VERSION ""

NS_ :

BS_:

BU_: WPC2 RLPSU DPSU APSU PSB SHVU_RR vHS_B2 FCS EMCU SLB ARS RCM CGW_CCU vDummy_HS_B ATS RLHV SGU PFSU ALBCU DSAU SWRC SHVU_FR RCS RRPSU BLTN_CAM SCM DLBCU OHCL RWPC RRHV WPC HOD ASAU

BO_ 273 ARS_04_00ms: 8 ARS
 SG_ ARS_RrCurtainBtn : 0|2@1+ (1,0) [0|0] "" Vector__XXX

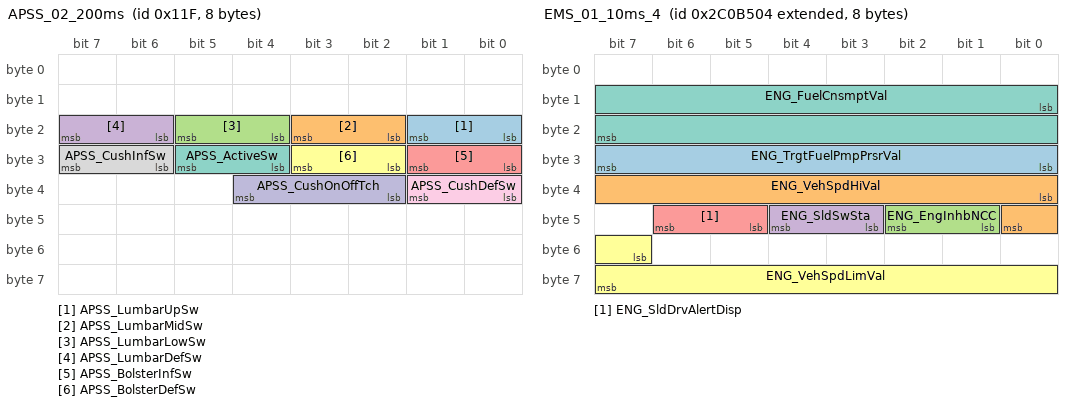
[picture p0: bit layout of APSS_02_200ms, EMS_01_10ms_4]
BO_ 287 APSS_02_200ms: 8 APSU
 SG_ APSS_LumbarUpSw : 16|2@1+ (1,0) [0|0] ""  ALBCU,CGW_CCU
 SG_ APSS_LumbarMidSw : 18|2@1+ (1,0) [0|0] ""  ALBCU,CGW_CCU
 SG_ APSS_LumbarLowSw : 20|2@1+ (1,0) [0|0] ""  ALBCU,CGW_CCU
 SG_ APSS_LumbarDefSw : 22|2@1+ (1,0) [0|0] ""  ALBCU,CGW_CCU
 SG_ APSS_BolsterInfSw : 24|2@1+ (1,0) [0|0] ""  ALBCU,CGW_CCU
 SG_ APSS_BolsterDefSw : 26|2@1+ (1,0) [0|0] ""  ALBCU,CGW_CCU
 SG_ APSS_ActiveSw : 28|2@1+ (1,0) [0|0] ""  ALBCU
 SG_ APSS_CushInfSw : 30|2@1+ (1,0) [0|0] ""  ALBCU
 SG_ APSS_CushDefSw : 32|2@1+ (1,0) [0|0] ""  ALBCU
 SG_ APSS_CushOnOffTch : 34|3@1+ (1,0) [0|0] ""  ALBCU

BO_ 2193667332 EMS_01_10ms_4: 8 CGW_CCU
 SG_ ENG_TrgtFuelPmpPrsrVal : 24|8@1+ (3.137254902,0) [0|0] "kPa" Vector__XXX
 SG_ ENG_VehSpdHiVal : 32|9@1+ (1,0) [0|0] "km/h" Vector__XXX
 SG_ ENG_EngInhbNCC : 41|2@1+ (1,0) [0|0] "" Vector__XXX
 SG_ ENG_SldSwSta : 43|2@1+ (1,0) [0|0] "" Vector__XXX
 SG_ ENG_SldDrvAlertDisp : 45|2@1+ (1,0) [0|0] "" Vector__XXX
 SG_ ENG_VehSpdLimVal : 55|9@1+ (1,0) [0|0] "km/h" Vector__XXX
 SG_ ENG_FuelCnsmptVal : 8|16@1+ (0.128,0) [0|0] "ul" Vector__XXX

BO_ 2193667331 EMS_01_10ms_3: 8 CGW_CCU
 SG_ ENG_TrgtIdleRpmVal : 0|8@1+ (10,0) [0|0] "rpm" Vector__XXX
 SG_ ENG_GearShftDnDis : 10|2@1+ (1,0) [0|0] "" Vector__XXX
 SG_ ENG_DsrGearPosDis : 12|4@1+ (1,0) [0|0] "" Vector__XXX
 SG_ ENG_SldFuncSta : 16|2@1+ (1,0) [0|0] "" Vector__XXX
 SG_ ENG_SldActnSta : 18|2@1+ (1,0) [0|0] "" Vector__XXX
 SG_ ENG_FuelTnkPrsrSta : 20|2@1+ (1,0) [0|0] "" Vector__XXX
 SG_ ENG_IsgBzrReq : 22|2@1+ (1,0) [0|0] "" Vector__XXX
 SG_ ENG_IsgFuelCnsmptDis : 24|2@1+ (1,0) [0|0] "" Vector__XXX
 SG_ ENG_FuelCapOpnSta : 26|2@1+ (1,0) [0|0] "" Vector__XXX
 SG_ ENG_EcoDrvActvSta : 28|2@1+ (1,0) [0|0] "" Vector__XXX
 SG_ ENG_EngRunSta : 30|2@1+ (1,0) [0|0] "" Vector__XXX
 SG_ ENG_Isg2Sta : 32|2@1+ (2,0) [0|0] "" Vector__XXX
 SG_ ENG_IgnOnSta : 34|2@1+ (1,0) [0|0] "" Vector__XXX
 SG_ ENG_Ack4TcsSta : 36|2@1+ (1,0) [0|0] "" Vector__XXX
 SG_ ENG_FuelCutOffSta : 38|2@1+ (1,0) [0|0] "" Vector__XXX
 SG_ ENG_CrctTqSta : 40|2@1+ (1,0) [0|0] "" Vector__XXX
 SG_ ENG_AirCompRlySta : 42|2@1+ (1,0) [0|0] "" Vector__XXX
 SG_ ENG_LnchCntrlSta : 45|3@1+ (1,0) [0|0] "" Vector__XXX
 SG_ ENG_EngSpdVal : 48|16@1+ (0.25,0) [0|0] "rpm"  EMCU
 SG_ ENG_GearShftUpDis : 8|2@1+ (1,0) [0|0] "" Vector__XXX

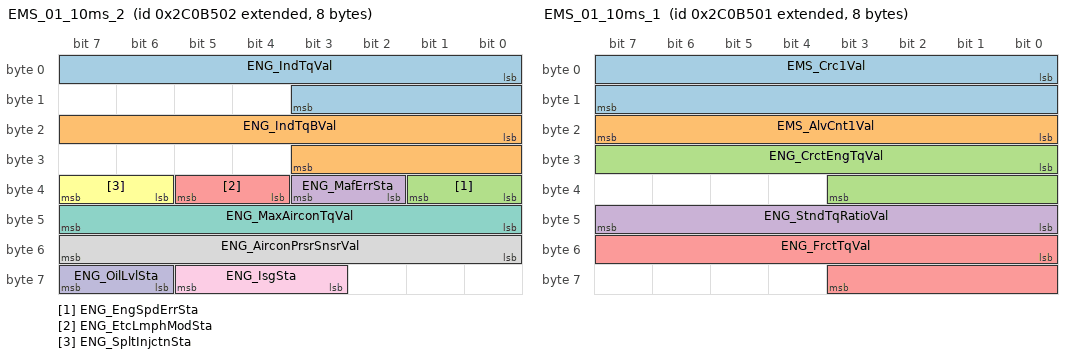
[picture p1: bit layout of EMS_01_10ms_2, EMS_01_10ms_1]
BO_ 2193667330 EMS_01_10ms_2: 8 CGW_CCU
 SG_ ENG_IndTqVal : 0|12@1- (1,0) [0|0] "Nm" Vector__XXX
 SG_ ENG_IndTqBVal : 16|12@1- (1,0) [0|0] "Nm" Vector__XXX
 SG_ ENG_EngSpdErrSta : 32|2@1+ (1,0) [0|0] "" Vector__XXX
 SG_ ENG_MafErrSta : 34|2@1+ (1,0) [0|0] "" Vector__XXX
 SG_ ENG_EtcLmphModSta : 36|2@1+ (1,0) [0|0] "" Vector__XXX
 SG_ ENG_SpltInjctnSta : 38|2@1+ (1,0) [0|0] "" Vector__XXX
 SG_ ENG_MaxAirconTqVal : 40|8@1+ (0.2,0) [0|0] "Nm" Vector__XXX
 SG_ ENG_AirconPrsrSnsrVal : 48|8@1+ (125,0) [0|0] "hPa" Vector__XXX
 SG_ ENG_IsgSta : 59|3@1+ (1,0) [0|0] ""  APSU,RLHV,RRHV,SHVU_FR,SHVU_RR,DPSU,RRPSU,RLPSU,EMCU
 SG_ ENG_OilLvlSta : 62|2@1+ (1,0) [0|0] "" Vector__XXX

BO_ 2193667329 EMS_01_10ms_1: 8 CGW_CCU
 SG_ EMS_Crc1Val : 0|16@1+ (1,0) [0|0] "" Vector__XXX
 SG_ EMS_AlvCnt1Val : 16|8@1+ (1,0) [0|0] "" Vector__XXX
 SG_ ENG_CrctEngTqVal : 24|12@1- (1,0) [0|0] "Nm" Vector__XXX
 SG_ ENG_StndTqRatioVal : 40|8@1+ (0.0078,0) [0|0] "" Vector__XXX
 SG_ ENG_FrctTqVal : 48|12@1- (1,0) [0|0] "Nm" Vector__XXX

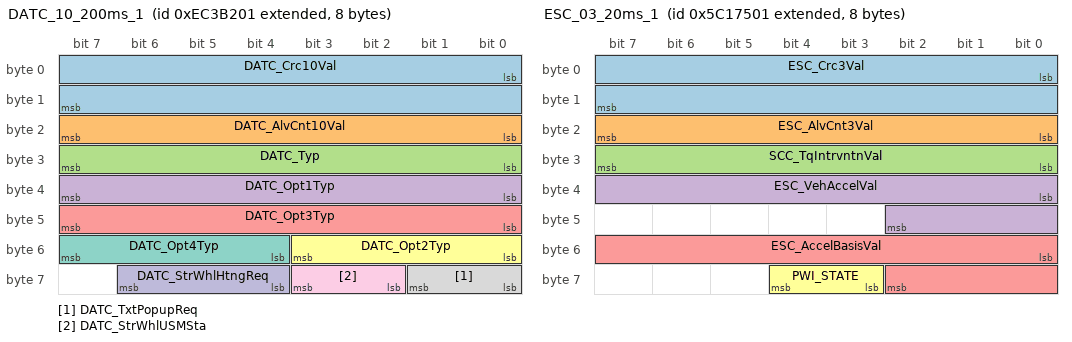
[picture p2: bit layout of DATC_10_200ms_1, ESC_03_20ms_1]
BO_ 2395189761 DATC_10_200ms_1: 8 CGW_CCU
 SG_ DATC_Crc10Val : 0|16@1+ (1,0) [0|0] "" Vector__XXX
 SG_ DATC_AlvCnt10Val : 16|8@1+ (1,0) [0|0] "" Vector__XXX
 SG_ DATC_Typ : 24|8@1+ (1,0) [0|0] ""  RLHV,RRHV,SHVU_FR,SHVU_RR,ATS
 SG_ DATC_Opt1Typ : 32|8@1+ (1,0) [0|0] ""  ATS
 SG_ DATC_Opt3Typ : 40|8@1+ (1,0) [0|0] ""  ATS
 SG_ DATC_Opt2Typ : 48|4@1+ (1,0) [0|0] ""  ATS
 SG_ DATC_Opt4Typ : 52|4@1+ (1,0) [0|0] ""  ATS
 SG_ DATC_TxtPopupReq : 56|2@1+ (1,0) [0|0] "" Vector__XXX
 SG_ DATC_StrWhlUSMSta : 58|2@1+ (1,0) [0|0] ""  APSU
 SG_ DATC_StrWhlHtngReq : 60|3@1+ (1,0) [0|0] "" Vector__XXX

BO_ 2244048129 ESC_03_20ms_1: 8 CGW_CCU
 SG_ ESC_Crc3Val : 0|16@1+ (1,0) [0|0] "" Vector__XXX
 SG_ ESC_AlvCnt3Val : 16|8@1+ (1,0) [0|0] "" Vector__XXX
 SG_ SCC_TqIntrvntnVal : 24|8@1+ (0.390625,0) [0|0] "%" Vector__XXX
 SG_ ESC_VehAccelVal : 32|11@1+ (0.01,-10.23) [0|0] "m/s^2" Vector__XXX
 SG_ ESC_AccelBasisVal : 48|11@1+ (0.01,-10.23) [0|0] "m/s^2" Vector__XXX
 SG_ PWI_STATE : 59|2@1+ (1,0) [0|0] "" Vector__XXX

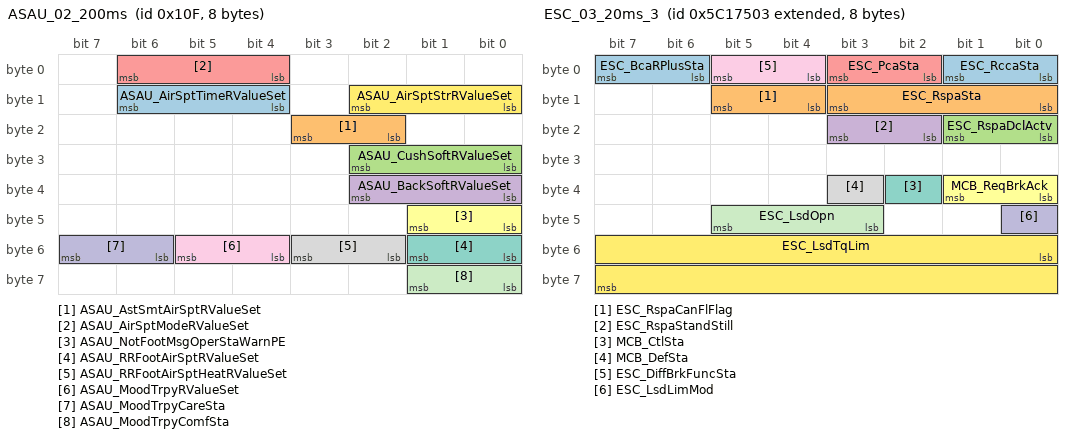
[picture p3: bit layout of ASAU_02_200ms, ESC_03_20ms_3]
BO_ 271 ASAU_02_200ms: 8 ASAU
 SG_ ASAU_AirSptTimeRValueSet : 12|3@1+ (1,0) [0|0] ""  CGW_CCU
 SG_ ASAU_AstSmtAirSptRValueSet : 18|2@1+ (1,0) [0|0] ""  CGW_CCU
 SG_ ASAU_CushSoftRValueSet : 24|3@1+ (1,0) [0|0] ""  CGW_CCU
 SG_ ASAU_BackSoftRValueSet : 32|3@1+ (1,0) [0|0] "" Vector__XXX
 SG_ ASAU_AirSptModeRValueSet : 4|3@1+ (1,0) [0|0] ""  CGW_CCU
 SG_ ASAU_NotFootMsgOperStaWarnPE : 40|2@1+ (1,0) [0|0] ""  ATS
 SG_ ASAU_RRFootAirSptRValueSet : 48|2@1+ (1,0) [0|0] ""  ATS
 SG_ ASAU_RRFootAirSptHeatRValueSet : 50|2@1+ (1,0) [0|0] ""  ATS
 SG_ ASAU_MoodTrpyRValueSet : 52|2@1+ (1,0) [0|0] ""  CGW_CCU
 SG_ ASAU_MoodTrpyCareSta : 54|2@1+ (1,0) [0|0] ""  CGW_CCU
 SG_ ASAU_MoodTrpyComfSta : 56|2@1+ (1,0) [0|0] ""  CGW_CCU
 SG_ ASAU_AirSptStrRValueSet : 8|3@1+ (1,0) [0|0] ""  CGW_CCU

BO_ 2244048131 ESC_03_20ms_3: 8 CGW_CCU
 SG_ ESC_RccaSta : 0|2@1+ (1,0) [0|0] "" Vector__XXX
 SG_ ESC_RspaCanFlFlag : 12|2@1+ (1,0) [0|0] "" Vector__XXX
 SG_ ESC_RspaDclActv : 16|2@1+ (1,0) [0|0] "" Vector__XXX
 SG_ ESC_RspaStandStill : 18|2@1+ (1,0) [0|0] "" Vector__XXX
 SG_ ESC_PcaSta : 2|2@1+ (1,0) [0|0] "" Vector__XXX
 SG_ MCB_ReqBrkAck : 32|2@1+ (1,0) [0|0] "" Vector__XXX
 SG_ MCB_CtlSta : 34|1@1+ (1,0) [0|0] "" Vector__XXX
 SG_ MCB_DefSta : 35|1@1+ (1,0) [0|0] "" Vector__XXX
 SG_ ESC_DiffBrkFuncSta : 4|2@1+ (1,0) [0|0] "" Vector__XXX
 SG_ ESC_LsdLimMod : 40|1@1+ (1,0) [0|0] "" Vector__XXX
 SG_ ESC_LsdOpn : 43|3@1+ (1,0) [0|0] "" Vector__XXX
 SG_ ESC_LsdTqLim : 48|16@1+ (1,0) [0|0] "Nm" Vector__XXX
 SG_ ESC_BcaRPlusSta : 6|2@1+ (1,0) [0|0] "" Vector__XXX
 SG_ ESC_RspaSta : 8|4@1+ (1,0) [0|0] "" Vector__XXX

BO_ 2244048130 ESC_03_20ms_2: 8 CGW_CCU
 SG_ SCC_OptTyp : 0|2@1+ (1,0) [0|0] "" Vector__XXX
 SG_ ESC_BrkLtReq : 10|2@1+ (1,0) [0|0] "" Vector__XXX
 SG_ ESC_DclEnblReq : 12|2@1+ (1,0) [0|0] "" Vector__XXX
 SG_ ESC_DrvOvrdSta : 16|2@1+ (1,0) [0|0] "" Vector__XXX
 SG_ ESC_DrvBrkSta : 18|2@1+ (1,0) [0|0] "" Vector__XXX
 SG_ SCC_EnblReq : 2|2@1+ (1,0) [0|0] "" Vector__XXX
 SG_ ESC_DrvBrkActvSta : 20|2@1+ (1,0) [0|0] "" Vector__XXX
 SG_ ESC_PrkBrkActvSta : 22|2@1+ (1,0) [0|0] "" Vector__XXX
 SG_ ESC_HDP_FltMonSta : 24|3@1+ (1,0) [0|0] ""  PSB
 SG_ ESC_HDPSpprtSWVer : 27|5@1+ (1,0) [0|0] "" Vector__XXX
 SG_ FCA_EquipSta : 32|2@1+ (1,0) [0|0] "" Vector__XXX
 SG_ FCA_AvlblSta : 34|2@1+ (1,0) [0|0] "" Vector__XXX
 SG_ ESC_FCA_ActvSta : 36|2@1+ (1,0) [0|0] "" Vector__XXX
 SG_ ESC_DBS_ActvSta : 38|2@1+ (1,0) [0|0] "" Vector__XXX
 SG_ SCC_TqReq : 4|2@1+ (1,0) [0|0] "" Vector__XXX
 SG_ ESC_HDP_EgSta : 40|3@1+ (1,0) [0|0] ""  PSB
 SG_ ESC_HDP_EnblReq : 43|3@1+ (1,0) [0|0] "" Vector__XXX
 SG_ CSC_Sta : 48|2@1+ (1,0) [0|0] "" Vector__XXX
 SG_ CSC_WrngSta : 50|2@1+ (1,0) [0|0] "" Vector__XXX
 SG_ ESC_BrkdFltStndstill : 56|2@1+ (1,0) [0|0] "" Vector__XXX
 SG_ SCC_ReqLimSta : 6|2@1+ (1,0) [0|0] "" Vector__XXX
 SG_ ESC_StdStillVal : 8|2@1+ (1,0) [0|0] "" Vector__XXX

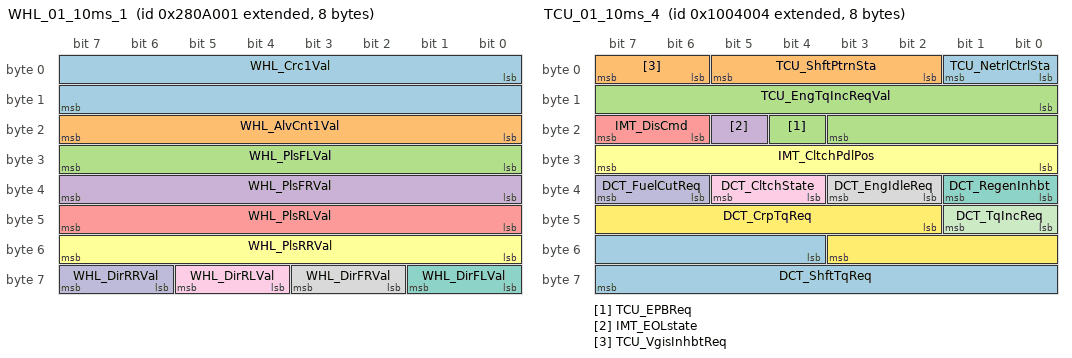
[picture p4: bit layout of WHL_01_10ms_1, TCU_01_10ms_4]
BO_ 2189467649 WHL_01_10ms_1: 8 CGW_CCU
 SG_ WHL_Crc1Val : 0|16@1+ (1,0) [0|0] "" Vector__XXX
 SG_ WHL_AlvCnt1Val : 16|8@1+ (1,0) [0|0] "" Vector__XXX
 SG_ WHL_PlsFLVal : 24|8@1+ (0.5,0) [0|0] "pulse count" Vector__XXX
 SG_ WHL_PlsFRVal : 32|8@1+ (0.5,0) [0|0] "pulse count" Vector__XXX
 SG_ WHL_PlsRLVal : 40|8@1+ (0.5,0) [0|0] "pulse count" Vector__XXX
 SG_ WHL_PlsRRVal : 48|8@1+ (0.5,0) [0|0] "pulse count" Vector__XXX
 SG_ WHL_DirFLVal : 56|2@1+ (1,0) [0|0] "" Vector__XXX
 SG_ WHL_DirFRVal : 58|2@1+ (1,0) [0|0] "" Vector__XXX
 SG_ WHL_DirRLVal : 60|2@1+ (1,0) [0|0] "" Vector__XXX
 SG_ WHL_DirRRVal : 62|2@1+ (1,0) [0|0] "" Vector__XXX

BO_ 2164277252 TCU_01_10ms_4: 8 CGW_CCU
 SG_ TCU_NetrlCtrlSta : 0|2@1+ (1,0) [0|0] "" Vector__XXX
 SG_ TCU_ShftPtrnSta : 2|4@1+ (1,0) [0|0] "" Vector__XXX
 SG_ TCU_EPBReq : 20|1@1+ (1,0) [0|0] "" Vector__XXX
 SG_ IMT_EOLstate : 21|1@1+ (1,0) [0|0] "" Vector__XXX
 SG_ IMT_DisCmd : 22|2@1+ (1,0) [0|0] "" Vector__XXX
 SG_ IMT_CltchPdlPos : 24|8@1+ (0.390625,0) [0|0] "%" Vector__XXX
 SG_ DCT_RegenInhbt : 32|2@1+ (1,0) [0|0] "" Vector__XXX
 SG_ DCT_EngIdleReq : 34|2@1+ (1,0) [0|0] "" Vector__XXX
 SG_ DCT_CltchState : 36|2@1+ (1,0) [0|0] "" Vector__XXX
 SG_ DCT_FuelCutReq : 38|2@1+ (1,0) [0|0] "" Vector__XXX
 SG_ DCT_TqIncReq : 40|2@1+ (1,0) [0|0] "" Vector__XXX
 SG_ DCT_CrpTqReq : 42|10@1+ (1,-512) [0|0] "Nm" Vector__XXX
 SG_ DCT_ShftTqReq : 52|12@1- (1,0) [0|0] "Nm" Vector__XXX
 SG_ TCU_VgisInhbtReq : 6|2@1+ (1,0) [0|0] "" Vector__XXX
 SG_ TCU_EngTqIncReqVal : 8|12@1- (1,0) [0|0] "Nm" Vector__XXX

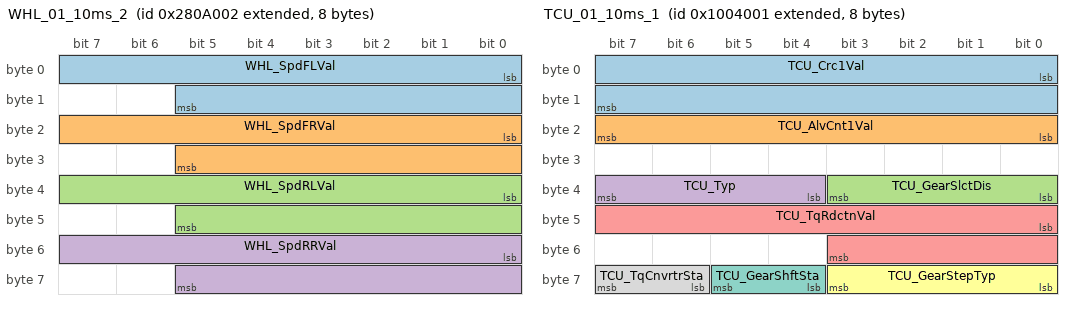
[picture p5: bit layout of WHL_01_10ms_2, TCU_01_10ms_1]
BO_ 2189467650 WHL_01_10ms_2: 8 CGW_CCU
 SG_ WHL_SpdFLVal : 0|14@1+ (0.03125,0) [0|0] "km^h"  PSB
 SG_ WHL_SpdFRVal : 16|14@1+ (0.03125,0) [0|0] "km^h"  PSB
 SG_ WHL_SpdRLVal : 32|14@1+ (0.03125,0) [0|0] "km^h"  PSB,APSU
 SG_ WHL_SpdRRVal : 48|14@1+ (0.03125,0) [0|0] "km^h"  PSB,APSU

BO_ 2189467651 WHL_01_10ms_3: 8 CGW_CCU
 SG_ WHL_SpdCalParmtr : 8|9@1+ (0.5,200) [0|0] "mm" Vector__XXX

BO_ 2164277249 TCU_01_10ms_1: 8 CGW_CCU
 SG_ TCU_Crc1Val : 0|16@1+ (1,0) [0|0] "" Vector__XXX
 SG_ TCU_AlvCnt1Val : 16|8@1+ (1,0) [0|0] ""  EMCU
 SG_ TCU_GearSlctDis : 32|4@1+ (1,0) [0|0] ""  SWRC,APSU,RLHV,RRHV,PFSU,RRPSU,RLPSU,BLTN_CAM
 SG_ TCU_Typ : 36|4@1+ (1,0) [0|0] ""  APSU,PFSU
 SG_ TCU_TqRdctnVal : 40|12@1- (1,0) [0|0] "Nm" Vector__XXX
 SG_ TCU_GearStepTyp : 56|4@1+ (1,0) [0|0] "" Vector__XXX
 SG_ TCU_GearShftSta : 60|2@1+ (1,0) [0|0] "" Vector__XXX
 SG_ TCU_TqCnvrtrSta : 62|2@1+ (1,0) [0|0] ""  EMCU

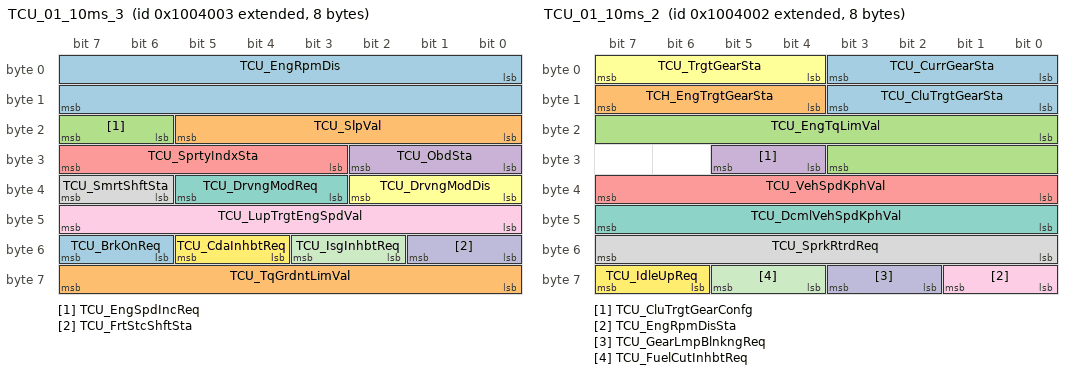
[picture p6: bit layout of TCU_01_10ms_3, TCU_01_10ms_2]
BO_ 2164277251 TCU_01_10ms_3: 8 CGW_CCU
 SG_ TCU_EngRpmDis : 0|16@1+ (0.25,0) [0|0] "rpm" Vector__XXX
 SG_ TCU_SlpVal : 16|6@1+ (0.5,-16) [0|0] "%" Vector__XXX
 SG_ TCU_EngSpdIncReq : 22|2@1+ (1,0) [0|0] "" Vector__XXX
 SG_ TCU_ObdSta : 24|3@1+ (1,0) [0|0] "" Vector__XXX
 SG_ TCU_SprtyIndxSta : 27|5@1+ (1,0) [0|0] "" Vector__XXX
 SG_ TCU_DrvngModDis : 32|3@1+ (1,0) [0|0] "" Vector__XXX
 SG_ TCU_DrvngModReq : 35|3@1+ (1,0) [0|0] "" Vector__XXX
 SG_ TCU_SmrtShftSta : 38|2@1+ (1,0) [0|0] "" Vector__XXX
 SG_ TCU_LupTrgtEngSpdVal : 40|8@1+ (10,500) [0|0] "rpm" Vector__XXX
 SG_ TCU_FrtStcShftSta : 48|2@1+ (1,0) [0|0] "" Vector__XXX
 SG_ TCU_IsgInhbtReq : 50|2@1+ (1,0) [0|0] "" Vector__XXX
 SG_ TCU_CdaInhbtReq : 52|2@1+ (1,0) [0|0] "" Vector__XXX
 SG_ TCU_BrkOnReq : 54|2@1+ (1,0) [0|0] "" Vector__XXX
 SG_ TCU_TqGrdntLimVal : 56|8@1+ (10,0) [0|0] "Nm/s" Vector__XXX

BO_ 2164277250 TCU_01_10ms_2: 8 CGW_CCU
 SG_ TCU_CurrGearSta : 0|4@1+ (1,0) [0|0] ""  EMCU
 SG_ TCH_EngTrgtGearSta : 12|4@1+ (1,0) [0|0] "" Vector__XXX
 SG_ TCU_EngTqLimVal : 16|12@1- (1,0) [0|0] "Nm" Vector__XXX
 SG_ TCU_CluTrgtGearConfg : 28|2@1+ (1,0) [0|0] "" Vector__XXX
 SG_ TCU_VehSpdKphVal : 32|8@1+ (1,0) [0|0] "km/h" Vector__XXX
 SG_ TCU_TrgtGearSta : 4|4@1+ (1,0) [0|0] "" Vector__XXX
 SG_ TCU_DcmlVehSpdKphVal : 40|8@1+ (0.0078125,0) [0|0] "km/h" Vector__XXX
 SG_ TCU_SprkRtrdReq : 48|8@1+ (0.375,-23.625) [0|0] "¢ª" Vector__XXX
 SG_ TCU_EngRpmDisSta : 56|2@1+ (1,0) [0|0] "" Vector__XXX
 SG_ TCU_GearLmpBlnkngReq : 58|2@1+ (1,0) [0|0] "" Vector__XXX
 SG_ TCU_FuelCutInhbtReq : 60|2@1+ (1,0) [0|0] "" Vector__XXX
 SG_ TCU_IdleUpReq : 62|2@1+ (1,0) [0|0] "" Vector__XXX
 SG_ TCU_CluTrgtGearSta : 8|4@1+ (1,0) [0|0] "" Vector__XXX

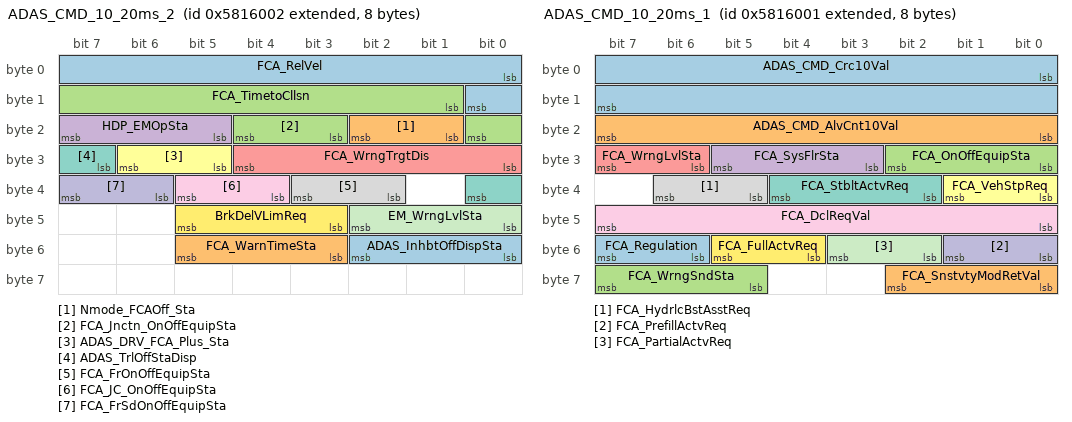
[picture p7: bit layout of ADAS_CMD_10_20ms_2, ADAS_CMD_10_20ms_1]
BO_ 2239848450 ADAS_CMD_10_20ms_2: 8 CGW_CCU
 SG_ FCA_RelVel : 0|9@1+ (0.1,-25.5) [0|0] "m/s" Vector__XXX
 SG_ Nmode_FCAOff_Sta : 17|2@1+ (1,0) [0|0] "" Vector__XXX
 SG_ FCA_Jnctn_OnOffEquipSta : 19|2@1+ (1,0) [0|0] "" Vector__XXX
 SG_ HDP_EMOpSta : 21|3@1+ (1,0) [0|0] "" Vector__XXX
 SG_ FCA_WrngTrgtDis : 24|5@1+ (1,0) [0|0] ""  APSU
 SG_ ADAS_DRV_FCA_Plus_Sta : 29|2@1+ (1,0) [0|0] "" Vector__XXX
 SG_ ADAS_TrlOffStaDisp : 31|2@1+ (1,0) [0|0] "" Vector__XXX
 SG_ FCA_FrOnOffEquipSta : 34|2@1+ (1,0) [0|0] "" Vector__XXX
 SG_ FCA_JC_OnOffEquipSta : 36|2@1+ (1,0) [0|0] "" Vector__XXX
 SG_ FCA_FrSdOnOffEquipSta : 38|2@1+ (1,0) [0|0] "" Vector__XXX
 SG_ EM_WrngLvlSta : 40|3@1+ (1,0) [0|0] "" Vector__XXX
 SG_ BrkDelVLimReq : 43|3@1+ (1,0) [0|0] "" Vector__XXX
 SG_ ADAS_InhbtOffDispSta : 48|3@1+ (1,0) [0|0] "" Vector__XXX
 SG_ FCA_WarnTimeSta : 51|3@1+ (1,0) [0|0] "" Vector__XXX
 SG_ FCA_TimetoCllsn : 9|8@1+ (10,0) [0|0] "ms" Vector__XXX

BO_ 2239848449 ADAS_CMD_10_20ms_1: 8 CGW_CCU
 SG_ ADAS_CMD_Crc10Val : 0|16@1+ (1,0) [0|0] "" Vector__XXX
 SG_ ADAS_CMD_AlvCnt10Val : 16|8@1+ (1,0) [0|0] "" Vector__XXX
 SG_ FCA_OnOffEquipSta : 24|3@1+ (1,0) [0|0] "" Vector__XXX
 SG_ FCA_SysFlrSta : 27|3@1+ (1,0) [0|0] ""  PSB
 SG_ FCA_WrngLvlSta : 30|2@1+ (1,0) [0|0] ""  SWRC,APSU,RRPSU,RLPSU
 SG_ FCA_VehStpReq : 32|2@1+ (1,0) [0|0] ""  SWRC
 SG_ FCA_StbltActvReq : 34|3@1+ (1,0) [0|0] ""  PSB
 SG_ FCA_HydrlcBstAsstReq : 37|2@1+ (1,0) [0|0] "" Vector__XXX
 SG_ FCA_DclReqVal : 40|8@1+ (0.01,0) [0|0] "g" Vector__XXX
 SG_ FCA_PrefillActvReq : 48|2@1+ (1,0) [0|0] "" Vector__XXX
 SG_ FCA_PartialActvReq : 50|2@1+ (1,0) [0|0] "" Vector__XXX
 SG_ FCA_FullActvReq : 52|2@1+ (1,0) [0|0] ""  APSU,RRPSU,RLPSU
 SG_ FCA_Regulation : 54|2@1+ (1,0) [0|0] "" Vector__XXX
 SG_ FCA_SnstvtyModRetVal : 56|3@1+ (1,0) [0|0] "" Vector__XXX
 SG_ FCA_WrngSndSta : 61|3@1+ (1,0) [0|0] "" Vector__XXX

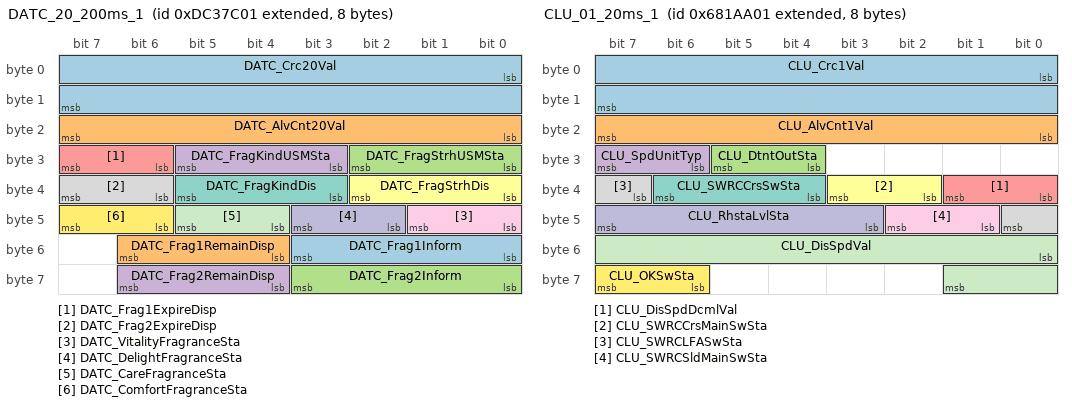
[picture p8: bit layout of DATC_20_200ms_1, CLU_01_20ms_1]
BO_ 2378398721 DATC_20_200ms_1: 8 CGW_CCU
 SG_ DATC_Crc20Val : 0|16@1+ (1,0) [0|0] "" Vector__XXX
 SG_ DATC_AlvCnt20Val : 16|8@1+ (1,0) [0|0] "" Vector__XXX
 SG_ DATC_FragStrhUSMSta : 24|3@1+ (1,0) [0|0] ""  ATS
 SG_ DATC_FragKindUSMSta : 27|3@1+ (1,0) [0|0] ""  ATS
 SG_ DATC_Frag1ExpireDisp : 30|2@1+ (1,0) [0|0] ""  ATS
 SG_ DATC_FragStrhDis : 32|3@1+ (1,0) [0|0] ""  ATS
 SG_ DATC_FragKindDis : 35|3@1+ (1,0) [0|0] ""  ATS
 SG_ DATC_Frag2ExpireDisp : 38|2@1+ (1,0) [0|0] ""  ATS
 SG_ DATC_VitalityFragranceSta : 40|2@1+ (1,0) [0|0] "" Vector__XXX
 SG_ DATC_DelightFragranceSta : 42|2@1+ (1,0) [0|0] "" Vector__XXX
 SG_ DATC_CareFragranceSta : 44|2@1+ (1,0) [0|0] "" Vector__XXX
 SG_ DATC_ComfortFragranceSta : 46|2@1+ (1,0) [0|0] "" Vector__XXX
 SG_ DATC_Frag1Inform : 48|4@1+ (1,0) [0|0] ""  ATS
 SG_ DATC_Frag1RemainDisp : 52|3@1+ (1,0) [0|0] ""  ATS
 SG_ DATC_Frag2Inform : 56|4@1+ (1,0) [0|0] ""  ATS
 SG_ DATC_Frag2RemainDisp : 60|3@1+ (1,0) [0|0] ""  ATS

BO_ 2256644609 CLU_01_20ms_1: 8 CGW_CCU
 SG_ CLU_Crc1Val : 0|16@1+ (1,0) [0|0] ""  SHVU_RR,DPSU,ATS
 SG_ CLU_AlvCnt1Val : 16|8@1+ (1,0) [0|0] ""  SHVU_RR,DPSU,ATS,EMCU
 SG_ CLU_DtntOutSta : 28|2@1+ (1,0) [0|0] ""  FCS,WPC,RWPC,ARS,SWRC,APSU,RLHV,RRHV,SHVU_FR,SHVU_RR,DPSU,RCS,RRPSU,RLPSU,ATS,DSAU,ASAU,OHCL,WPC2
 SG_ CLU_SpdUnitTyp : 30|2@1+ (1,0) [0|0] ""  DPSU,BLTN_CAM,EMCU,WPC2
 SG_ CLU_DisSpdDcmlVal : 32|2@1+ (0.125,0) [0|0] "" Vector__XXX
 SG_ CLU_SWRCCrsMainSwSta : 34|2@1+ (1,0) [0|0] "" Vector__XXX
 SG_ CLU_SWRCCrsSwSta : 36|3@1+ (1,0) [0|0] "" Vector__XXX
 SG_ CLU_SWRCLFASwSta : 39|2@1+ (1,0) [0|0] "" Vector__XXX
 SG_ CLU_SWRCSldMainSwSta : 41|2@1+ (1,0) [0|0] "" Vector__XXX
 SG_ CLU_RhstaLvlSta : 43|5@1+ (1,0) [0|0] ""  FCS,WPC,RWPC,ARS,SWRC,APSU,RLHV,RRHV,SHVU_FR,SHVU_RR,DPSU,RCS,RRPSU,RLPSU,ATS,DSAU,ASAU,OHCL,WPC2
 SG_ CLU_DisSpdVal : 48|10@1+ (0.5,0) [0|0] "km/h or MPH"  APSU,DPSU,BLTN_CAM,EMCU,WPC2
 SG_ CLU_OKSwSta : 62|2@1+ (1,0) [0|0] "" Vector__XXX

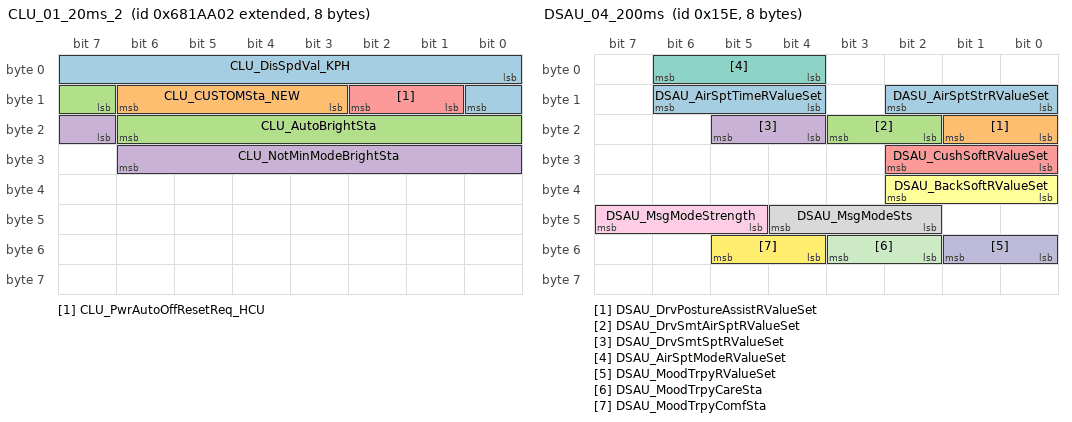
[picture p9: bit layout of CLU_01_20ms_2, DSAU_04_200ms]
BO_ 2256644610 CLU_01_20ms_2: 8 CGW_CCU
 SG_ CLU_DisSpdVal_KPH : 0|9@1+ (1,0) [0|0] "km/h"  WPC,RWPC,APSU,RLHV,RRHV,SHVU_FR,SHVU_RR,DPSU,DLBCU,PFSU,RRPSU,RLPSU,ATS,DSAU,ASAU,RCM,ALBCU,WPC2
 SG_ CLU_CUSTOMSta_NEW : 11|4@1+ (1,0) [0|0] ""  SWRC
 SG_ CLU_AutoBrightSta : 15|8@1+ (1,0) [0|0] ""  FCS,WPC,RWPC,SWRC,APSU,RLHV,RRHV,SHVU_FR,SHVU_RR,DPSU,RCS,ATS,DSAU,ASAU,OHCL,BLTN_CAM,WPC2
 SG_ CLU_NotMinModeBrightSta : 23|8@1+ (1,0) [0|0] "" Vector__XXX
 SG_ CLU_PwrAutoOffResetReq_HCU : 9|2@1+ (1,0) [0|0] "" Vector__XXX

BO_ 350 DSAU_04_200ms: 8 DSAU
 SG_ DSAU_AirSptTimeRValueSet : 12|3@1+ (1,0) [0|0] ""  CGW_CCU
 SG_ DSAU_DrvPostureAssistRValueSet : 16|2@1+ (1,0) [0|0] "" Vector__XXX
 SG_ DSAU_DrvSmtAirSptRValueSet : 18|2@1+ (1,0) [0|0] ""  CGW_CCU
 SG_ DSAU_DrvSmtSptRValueSet : 20|2@1+ (1,0) [0|0] "" Vector__XXX
 SG_ DSAU_CushSoftRValueSet : 24|3@1+ (1,0) [0|0] ""  CGW_CCU
 SG_ DSAU_BackSoftRValueSet : 32|3@1+ (1,0) [0|0] "" Vector__XXX
 SG_ DSAU_AirSptModeRValueSet : 4|3@1+ (1,0) [0|0] ""  CGW_CCU
 SG_ DSAU_MsgModeSts : 42|3@1+ (1,0) [0|0] ""  CGW_CCU
 SG_ DSAU_MsgModeStrength : 45|3@1+ (1,0) [0|0] ""  CGW_CCU
 SG_ DSAU_MoodTrpyRValueSet : 48|2@1+ (1,0) [0|0] ""  CGW_CCU
 SG_ DSAU_MoodTrpyCareSta : 50|2@1+ (1,0) [0|0] ""  CGW_CCU
 SG_ DSAU_MoodTrpyComfSta : 52|2@1+ (1,0) [0|0] ""  CGW_CCU
 SG_ DASU_AirSptStrRValueSet : 8|3@1+ (1,0) [0|0] ""  CGW_CCU

BO_ 349 DSAU_03_200ms: 8 DSAU
 SG_ DSAU_CushInfDis : 0|2@1+ (1,0) [0|0] ""  CGW_CCU
 SG_ DSAU_CushDefDis : 2|2@1+ (1,0) [0|0] ""  CGW_CCU

BO_ 348 DSAU_02_200ms: 8 DSAU
 SG_ DSAU_BolsterInfDis : 0|2@1+ (1,0) [0|0] ""  CGW_CCU
 SG_ DSAU_BolsterDefDis : 2|2@1+ (1,0) [0|0] ""  CGW_CCU

BO_ 346 DPSS_04_200ms: 8 DPSU
 SG_ DPSS_WalkInSwitchSts : 44|2@1+ (1,0) [0|0] "" Vector__XXX

CM_ BO_ 273 "[EC] On Event and On Change";
CM_ SG_ 273 ARS_RrCurtainBtn "Rear Curtain Button";
CM_ BO_ 287 "[PE] Periodic and On Event";
CM_ SG_ 287 APSS_LumbarUpSw "APSS_LumbarUpMoveSwitch";
CM_ SG_ 287 APSS_LumbarMidSw "APSS_LumbarMiddleSwitch";
CM_ SG_ 287 APSS_LumbarLowSw "APSS_LumbarLowerSwitch";
CM_ SG_ 287 APSS_LumbarDefSw "APSS_LumbarDeflationSwitch";
CM_ SG_ 287 APSS_BolsterInfSw "APSS_BolsterInflationSwitch";
CM_ SG_ 287 APSS_BolsterDefSw "APSS_BolsterDeflationSwitch";
CM_ SG_ 287 APSS_ActiveSw "APSS_ActiveSwitch";
CM_ SG_ 287 APSS_CushInfSw "APSS_Cush Support Inflation Switch";
CM_ SG_ 287 APSS_CushDefSw "APSS_Cush Support Deflation Switch";
CM_ SG_ 287 APSS_CushOnOffTch "APSS_CushOnOffTouch";
CM_ BO_ 2193667332 "[P] Periodic";
CM_ SG_ 2193667332 ENG_TrgtFuelPmpPrsrVal "ENG_TargetFuelPumpPressureValue ##2G##EMS - EMS20 - CF_Ems_PumpTPres";
CM_ SG_ 2193667332 ENG_VehSpdHiVal "ENG_VehicleSpeedHighValue";
CM_ SG_ 2193667332 ENG_EngInhbNCC "This signal indicates the Inhibition of NCC MODE";
CM_ SG_ 2193667332 ENG_SldSwSta "The status of Speed limiter function.";
CM_ SG_ 2193667332 ENG_SldDrvAlertDisp "The status of No Sld Engaged or Sld Disengaged.";
CM_ SG_ 2193667332 ENG_VehSpdLimVal "ENG_VehicleSpeedLimitValue ##2G##EMS - EMS_H12 - SLD_VS, EMS20-SLD_VS_EXT";
CM_ SG_ 2193667332 ENG_FuelCnsmptVal "ENG_FuelConsumptionValue ##2G##EMS - EMS20 - FCO";
CM_ BO_ 2193667331 "[P] Periodic";
CM_ SG_ 2193667331 ENG_TrgtIdleRpmVal "ENG_TargetIdleRpmValue ##2G##EMS - EMS_H12 - R_NEngIdlTgC";
CM_ SG_ 2193667331 ENG_GearShftDnDis "ENG_GearShiftDownDisplay ##2G##EMS - EMS_H12 - CF_Ems_DownTarGr";
CM_ SG_ 2193667331 ENG_DsrGearPosDis "ENG_DesirableGearPositionDisplay ##2G##EMS - EMS_H12 - CF_Ems_DesCurGr";
CM_ SG_ 2193667331 ENG_SldFuncSta "ENG_SpeedLimitFunctionStatus ##2G##EMS - EMS_H12 - CF_Ems_SldAct";
CM_ SG_ 2193667331 ENG_SldActnSta "ENG_SpeedLimitActionStatus ##2G##EMS - EMS_H12 - CF_Ems_SldPosAct";
CM_ SG_ 2193667331 ENG_FuelTnkPrsrSta "ENG_FuelTankPressureStatus ##2G##EMS - EMS_H12 - CF_Ems_HPresStat";
CM_ SG_ 2193667331 ENG_IsgBzrReq "ENG_IsgBuzzerRequest ##2G##EMS - EMS_H12 - CF_Ems_IsgBuz";
CM_ SG_ 2193667331 ENG_IsgFuelCnsmptDis "ENG_IsgFuelConsumptionDisplay ##2G##EMS - EMS_H12 - CF_Ems_IdlStpFCO";
CM_ SG_ 2193667331 ENG_FuelCapOpnSta "ENG_FuelCapOpenStatus ##2G##EMS - EMS_H12 - CF_Ems_FCopen";
CM_ SG_ 2193667331 ENG_EcoDrvActvSta "ENG_EcoDriveActiveStatus ##2G##EMS - EMS_H12 - CF_Ems_ActEcoAct";
CM_ SG_ 2193667331 ENG_EngRunSta "ENG_EngineRunningStatus ##2G##EMS - EMS_H12 - CF_Ems_EngRunNorm";
CM_ SG_ 2193667331 ENG_Isg2Sta "ENG_Isg2Status ##2G##EMS - EMS_H12 - CF_Ems_IsgStat2";
CM_ SG_ 2193667331 ENG_IgnOnSta "ENG_IgnitionOnStatus ##2G##EMS - EMS11 - SWI_IGK";
CM_ SG_ 2193667331 ENG_Ack4TcsSta "ENG_AcknowledgeForTcsStatus ##2G##EMS - EMS11 - ACK_TCS";
CM_ SG_ 2193667331 ENG_FuelCutOffSta "ENG_FuelCutOffStatus ##2G##EMS - EMS11 - PUC_STAT";
CM_ SG_ 2193667331 ENG_CrctTqSta "ENG_CorrectedTorqueStatus ##2G##EMS - EMS11 - TQ_COR_STAT";
CM_ SG_ 2193667331 ENG_AirCompRlySta "ENG_AirCompressorRelayStatus ##2G##EMS - EMS11 - RLY_AC";
CM_ SG_ 2193667331 ENG_LnchCntrlSta "ENG_LaunchControlStatus";
CM_ SG_ 2193667331 ENG_EngSpdVal "ENG_EngineSpeedValue ##2G##EMS - EMS11 - N";
CM_ SG_ 2193667331 ENG_GearShftUpDis "ENG_GearShiftUpDisplay ##2G##EMS - EMS_H12 - CF_Ems_UpTarGr";
CM_ BO_ 2193667330 "[P] Periodic";
CM_ SG_ 2193667330 ENG_IndTqVal "ENG_IndicatedTorqueValue ##2G##EMS - EMS11 - TQI";
CM_ SG_ 2193667330 ENG_IndTqBVal "ENG_IndicatedTorqueBValue ##2G##EMS - EMS_H12 - TQI_B";
CM_ SG_ 2193667330 ENG_EngSpdErrSta "ENG_EngineSpeedErrorStatus ##2G##EMS - EMS11 - F_N_ENG";
CM_ SG_ 2193667330 ENG_MafErrSta "ENG_MassAirFlowErrorStatus ##2G##EMS - EMS11 - F_SUB_TQI";
CM_ SG_ 2193667330 ENG_EtcLmphModSta "ENG_EtcLimphomeModeStatus ##2G##EMS - EMS_H12 - CF_Ems_EtcLimpMod";
CM_ SG_ 2193667330 ENG_SpltInjctnSta "ENG_SplitInjectionStatus";
CM_ SG_ 2193667330 ENG_MaxAirconTqVal "ENG_MaximumAirconTorqueValue ##2G##EMS - EMS_H12 - R_TqAcnApvC";
CM_ SG_ 2193667330 ENG_AirconPrsrSnsrVal "ENG_AirconPressureSensorValue ##2G##EMS - EMS_H12 - R_PAcnC";
CM_ SG_ 2193667330 ENG_IsgSta "ENG_IsgStatus ##2G##EMS - EMS_H12 - CF_Ems_IsgStat";
CM_ SG_ 2193667330 ENG_OilLvlSta "ENG_OilLevelStatus ##2G##EMS - EMS_H12 - CF_Ems_OilChg";
CM_ BO_ 2193667329 "[P] Periodic";
CM_ SG_ 2193667329 EMS_Crc1Val "EMS_CyclicRedundancyCheck1Value";
CM_ SG_ 2193667329 EMS_AlvCnt1Val "EMS_AliveCounter1Value";
CM_ SG_ 2193667329 ENG_CrctEngTqVal "ENG_CorrectedEngineTorqueValue ##2G##EMS - EMS11 - TQI_ACOR";
CM_ SG_ 2193667329 ENG_StndTqRatioVal "ENG_StandardTorqueRatioValue ##2G##EMS - EMS11 - RATIO_TQI_BAS_MAX_STND";
CM_ SG_ 2193667329 ENG_FrctTqVal "ENG_FrictionTorqueValue ##2G##EMS - EMS11 - TQFR";
CM_ BO_ 2395189761 "[PE] Periodic and On Event";
CM_ SG_ 2395189761 DATC_Crc10Val "DATC_CyclicRedundancyCheck10Value";
CM_ SG_ 2395189761 DATC_AlvCnt10Val "DATC_AliveCounter10Value";
CM_ SG_ 2395189761 DATC_Typ "DATC_Type";
CM_ SG_ 2395189761 DATC_Opt1Typ "DATC_Option1Type";
CM_ SG_ 2395189761 DATC_Opt3Typ "DATC_Option3Type";
CM_ SG_ 2395189761 DATC_Opt2Typ "DATC_Option2Type";
CM_ SG_ 2395189761 DATC_Opt4Typ "HTR CONTROL OPTION";
CM_ SG_ 2395189761 DATC_TxtPopupReq "DATC_TextPopupReq";
CM_ SG_ 2395189761 DATC_StrWhlUSMSta "DATC_SteeringWheelUSMState";
CM_ SG_ 2395189761 DATC_StrWhlHtngReq "DATC_SteeringWheelHeatReq";
CM_ BO_ 2244048129 "[P] Periodic";
CM_ SG_ 2244048129 ESC_Crc3Val "ESC_CyclicRedundancyCheck3Value";
CM_ SG_ 2244048129 ESC_AlvCnt3Val "ESC_AliveCounter3Value";
CM_ SG_ 2244048129 SCC_TqIntrvntnVal "SCC_TorqueInterventionValue ##2G##ESC - TCS13 - TQI_ACC";
CM_ SG_ 2244048129 ESC_VehAccelVal "ESC_VehicleAccelerationValue ##2G##ESC - TCS13 - ACCEL_REF_ACC";
CM_ SG_ 2244048129 ESC_AccelBasisVal "ESC_AccelerationBasisValue ##2G##ESC - TCS13 - aBasis";
CM_ BO_ 271 "[PE] Periodic and On Event";
CM_ SG_ 271 ASAU_AirSptTimeRValueSet "Air Support Time(Massage Time) USM R Value";
CM_ SG_ 271 ASAU_AstSmtAirSptRValueSet "Seat Smart Air Support Function USM R Value";
CM_ SG_ 271 ASAU_CushSoftRValueSet "Cushion Soft R Value";
CM_ SG_ 271 ASAU_BackSoftRValueSet "Back Soft USM R Value";
CM_ SG_ 271 ASAU_AirSptModeRValueSet "Air Support Mode(Massage Mode) USM R Value";
CM_ SG_ 271 ASAU_NotFootMsgOperStaWarnPE "Passenger Foot Massage Operation Disable Mode";
CM_ SG_ 271 ASAU_RRFootAirSptRValueSet "Foot Air Support USM R Value";
CM_ SG_ 271 ASAU_RRFootAirSptHeatRValueSet "Foot Air Support Heat USM R Value";
CM_ SG_ 271 ASAU_MoodTrpyRValueSet "Passenger Seat Mood Therapy R Value";
CM_ SG_ 271 ASAU_MoodTrpyCareSta "Passenger Seat Mood Therapy Care Mode R Value";
CM_ SG_ 271 ASAU_MoodTrpyComfSta "Passenger Seat Mood Therapy Comfort Mode R Value";
CM_ SG_ 271 ASAU_AirSptStrRValueSet "Air Support Strenth(Massage Strenth) USM R Value";
CM_ BO_ 2244048131 "[P] Periodic";
CM_ SG_ 2244048131 ESC_RccaSta "ESC_RccaStatus ##2G##ESC - ESP11 - ESP_RCCA_STAT";
CM_ SG_ 2244048131 ESC_RspaCanFlFlag "##2G##ESC - ESP11 - ESC_RspaCanfailflag";
CM_ SG_ 2244048131 ESC_RspaDclActv "##2G##ESC - ESP11 - ESC_RSPA_DEC_ACT";
CM_ SG_ 2244048131 ESC_RspaStandStill "##2G##ESC - ESP11 - ESC_RSPA_STANDSTILL";
CM_ SG_ 2244048131 ESC_PcaSta "ESC_PcaStatus";
CM_ SG_ 2244048131 MCB_ReqBrkAck "Acknowledge Status for MCB Brake Request";
CM_ SG_ 2244048131 MCB_CtlSta "Status for MCB Activation";
CM_ SG_ 2244048131 MCB_DefSta "Status for MCB defect";
CM_ SG_ 2244048131 ESC_DiffBrkFuncSta "ESC_DifferentialBrakeFunctionStatus ##2G##ESC - TCS13 - DF_BF_STAT";
CM_ SG_ 2244048131 ESC_LsdLimMod "eLSD torque limit mode ##2G##ESC - ESP_LSD11 - LSD_LIM_MODE";
CM_ SG_ 2244048131 ESC_LsdOpn "eLSD clutch open mode ##2G##ESC - ESP_LSD11 - LSD_OPEN";
CM_ SG_ 2244048131 ESC_LsdTqLim "value of the torquel limit of eLSD ##2G##ESC - ESP_LSD11 - LSD_TQC_LIM";
CM_ SG_ 2244048131 ESC_BcaRPlusSta "ESC_BcaRPlusStatus";
CM_ SG_ 2244048131 ESC_RspaSta "ESC_RspaStatus ##2G##ESC - ESP11 - ESP_RSPA_STAT";
CM_ BO_ 2244048130 "[P] Periodic";
CM_ SG_ 2244048130 SCC_OptTyp "SCC_OptionType ##2G##ESC - TCS13 - ACC_EQUIP";
CM_ SG_ 2244048130 ESC_BrkLtReq "ESC_BrakeLightRequest ##2G##ESC - TCS13 - BrakeLight";
CM_ SG_ 2244048130 ESC_DclEnblReq "ESC_DecelerationEnableRequest ##2G##ESC - TCS13 - DCEnable";
CM_ SG_ 2244048130 ESC_DrvOvrdSta "ESC_OverrideRequest ##2G##ESC - TCS13 - DriverOverride";
CM_ SG_ 2244048130 ESC_DrvBrkSta "ESC_DriverBrakingStatus ##2G##ESC - TCS13 - CF_DriBkeStat";
CM_ SG_ 2244048130 SCC_EnblReq "SCC_EnableRequest ##2G##ESC - TCS13 - ACCEnable";
CM_ SG_ 2244048130 ESC_DrvBrkActvSta "ESC_DriverBrakingActiveStatus ##2G##ESC - TCS13 - DriverBraking";
CM_ SG_ 2244048130 ESC_PrkBrkActvSta "ESC_ParkingBrakeActiveStatus ##2G##ESC - TCS13 - PBRAKE_ACT";
CM_ SG_ 2244048130 ESC_HDP_FltMonSta "ESC_HDP_FaultStatus";
CM_ SG_ 2244048130 ESC_HDPSpprtSWVer "IEB/RCU - HDP Support Software Version";
CM_ SG_ 2244048130 FCA_EquipSta "FCA_EquipmentStatus ##2G##ESC - TCS13 - FCA_EQUIP";
CM_ SG_ 2244048130 FCA_AvlblSta "VSM_AvailableStatus ##2G##ESC - TCS13 - CF_VSM_Avail";
CM_ SG_ 2244048130 ESC_FCA_ActvSta "Status of control for FCA control request flag";
CM_ SG_ 2244048130 ESC_DBS_ActvSta "ESC_DBS_ActvSta ##2G## ESC - TCS11 - DBS_ACK";
CM_ SG_ 2244048130 SCC_TqReq "SCC_TorqueRequest ##2G##ESC - TCS13 - ACC_REQ";
CM_ SG_ 2244048130 ESC_HDP_EgSta "ESC_HDP_EngagedStatus";
CM_ SG_ 2244048130 ESC_HDP_EnblReq "ESC_HDP_EnableRequest";
CM_ SG_ 2244048130 ESC_BrkdFltStndstill "Detect Indication of braked, flatland and standstill state";
CM_ SG_ 2244048130 SCC_ReqLimSta "SCC_RequestLimitedStatus ##2G##ESC - TCS13 - ACCReqLim";
CM_ SG_ 2244048130 ESC_StdStillVal "ESC_StandStillValue ##2G##ESC - TCS13 - StandStill";
CM_ BO_ 2189467649 "[P] Periodic";
CM_ SG_ 2189467649 WHL_Crc1Val "WHL_CyclicRedundancyCheck1Value";
CM_ SG_ 2189467649 WHL_AlvCnt1Val "WHL_AliveCounter1Value";
CM_ SG_ 2189467649 WHL_PlsFLVal "WHL_PulseFrontLeftValue ##2G##ESC - WHL_PUL11 - WHL_PUL_FL";
CM_ SG_ 2189467649 WHL_PlsFRVal "WHL_PulseFrontRightValue ##2G##ESC - WHL_PUL11 - WHL_PUL_FR";
CM_ SG_ 2189467649 WHL_PlsRLVal "WHL_PulseRearLeftValue ##2G##ESC - WHL_PUL11 - WHL_PUL_RL";
CM_ SG_ 2189467649 WHL_PlsRRVal "WHL_PulseRearRightValue ##2G##ESC - WHL_PUL11 - WHL_PUL_RR";
CM_ SG_ 2189467649 WHL_DirFLVal "WHL_DirectionFrontLeftValue ##2G##ESC - WHL_PUL11 - WHL_DIR_FL";
CM_ SG_ 2189467649 WHL_DirFRVal "WHL_DirectionFrontRightValue ##2G##ESC - WHL_PUL11 - WHL_DIR_FR";
CM_ SG_ 2189467649 WHL_DirRLVal "WHL_DirectionRearLeftValue ##2G##ESC - WHL_PUL11 - WHL_DIR_RL";
CM_ SG_ 2189467649 WHL_DirRRVal "WHL_DirectionRearRightValue ##2G##ESC - WHL_PUL11 - WHL_DIR_RR";
CM_ BO_ 2164277252 "[P] Periodic";
CM_ SG_ 2164277252 TCU_NetrlCtrlSta "TCU_NeutralControlStatus";
CM_ SG_ 2164277252 TCU_ShftPtrnSta "TCU_ShiftPatternStatus";
CM_ SG_ 2164277252 TCU_EPBReq "EPB Request signal for prevent P-D Shock on hill";
CM_ SG_ 2164277252 IMT_EOLstate "Gear Display for EOL mode to cluster. This signal is for IMT system only.";
CM_ SG_ 2164277252 IMT_DisCmd "Gear Display type command to cluster . this signal is for IMT system only.";
CM_ SG_ 2164277252 IMT_CltchPdlPos "Clutch Pedal Position. This signal is for IMT system only.";
CM_ SG_ 2164277252 DCT_RegenInhbt "The regen inhibit request from TCU";
CM_ SG_ 2164277252 DCT_EngIdleReq "Engine Idle Request";
CM_ SG_ 2164277252 DCT_CltchState "DCT clutch status";
CM_ SG_ 2164277252 DCT_FuelCutReq "TCU require ECU to perform ¡®Fuel Cut¡¯";
CM_ SG_ 2164277252 DCT_TqIncReq "Request for Torque Increase";
CM_ SG_ 2164277252 DCT_CrpTqReq "Pre-control torque for creeping";
CM_ SG_ 2164277252 DCT_ShftTqReq "Pre-control torque for shifting";
CM_ SG_ 2164277252 TCU_VgisInhbtReq "TCU_VgisInhibitionRequest";
CM_ SG_ 2164277252 TCU_EngTqIncReqVal "TCU_EngineTorqueIncreaseReqValue";
CM_ BO_ 2189467650 "[P] Periodic";
CM_ SG_ 2189467650 WHL_SpdFLVal "WHL_SpeedFrontLeftValue ##2G##ESC - WHL_SPD11 - WHL_SPD_FL";
CM_ SG_ 2189467650 WHL_SpdFRVal "WHL_SpeedFrontRightValue ##2G##ESC - WHL_SPD11 - WHL_SPD_FR";
CM_ SG_ 2189467650 WHL_SpdRLVal "WHL_SpeedRearLeftValue ##2G##ESC - WHL_SPD11 - WHL_SPD_RL";
CM_ SG_ 2189467650 WHL_SpdRRVal "WHL_SpeedRearRightValue ##2G##ESC - WHL_SPD11 - WHL_SPD_RR";
CM_ BO_ 2189467651 "[P] Periodic";
CM_ SG_ 2189467651 WHL_SpdCalParmtr "WHL_SpeedCalculationParameter";
CM_ BO_ 2164277249 "[P] Periodic";
CM_ SG_ 2164277249 TCU_Crc1Val "TCU_CyclicRedundancyCheck1Value";
CM_ SG_ 2164277249 TCU_AlvCnt1Val "TCU_AliveCounter1Value";
CM_ SG_ 2164277249 TCU_GearSlctDis "TCU_GearSelectDisplay";
CM_ SG_ 2164277249 TCU_Typ "TCU_Type";
CM_ SG_ 2164277249 TCU_TqRdctnVal "TCU_TorqueReductionValue";
CM_ SG_ 2164277249 TCU_GearStepTyp "TCU_GearStepType";
CM_ SG_ 2164277249 TCU_GearShftSta "TCU_GearShiftStatus";
CM_ SG_ 2164277249 TCU_TqCnvrtrSta "TCU_TorqueConverterStatus";
CM_ BO_ 2164277251 "[P] Periodic";
CM_ SG_ 2164277251 TCU_EngRpmDis "TCU_EngineRpmDisplay";
CM_ SG_ 2164277251 TCU_SlpVal "TCU_SlopeValue";
CM_ SG_ 2164277251 TCU_EngSpdIncReq "TCU_EngineSpeedIncreaseRequest";
CM_ SG_ 2164277251 TCU_ObdSta "TCU_ObdStatus";
CM_ SG_ 2164277251 TCU_SprtyIndxSta "TCU_SportyIndexStatus";
CM_ SG_ 2164277251 TCU_DrvngModDis "TCU_DrivingModeDisplay";
CM_ SG_ 2164277251 TCU_DrvngModReq "TCU_DrivingModeRequest";
CM_ SG_ 2164277251 TCU_SmrtShftSta "TCU_SmartShiftStatus";
CM_ SG_ 2164277251 TCU_LupTrgtEngSpdVal "TCU_LupTargetEngineSpeedValue";
CM_ SG_ 2164277251 TCU_FrtStcShftSta "TCU_FirstStaticShiftStatus";
CM_ SG_ 2164277251 TCU_IsgInhbtReq "TCU_IsgInhibitRequest";
CM_ SG_ 2164277251 TCU_CdaInhbtReq "TCU_CdaInhibitRequest";
CM_ SG_ 2164277251 TCU_BrkOnReq "TCU_BrakeOnRequest";
CM_ SG_ 2164277251 TCU_TqGrdntLimVal "TCU_TorqueGradientLimitationValue";
CM_ BO_ 2164277250 "[P] Periodic";
CM_ SG_ 2164277250 TCU_CurrGearSta "TCU_CurrentGearStatus";
CM_ SG_ 2164277250 TCH_EngTrgtGearSta "TCU_EngineTargetGear";
CM_ SG_ 2164277250 TCU_EngTqLimVal "TCU_EngineTorqueLimitValue";
CM_ SG_ 2164277250 TCU_CluTrgtGearConfg "Signal source Configuration of  Target gear for CLU";
CM_ SG_ 2164277250 TCU_VehSpdKphVal "TCU_VehicleSpeedKphValue";
CM_ SG_ 2164277250 TCU_TrgtGearSta "TCU_TargetGearStatus";
CM_ SG_ 2164277250 TCU_DcmlVehSpdKphVal "TCU_VehicleSpeedDecimalKphValue";
CM_ SG_ 2164277250 TCU_SprkRtrdReq "TCU_SparkRetardAngleValue";
CM_ SG_ 2164277250 TCU_EngRpmDisSta "TCU_EngineRpmDisplayStatus";
CM_ SG_ 2164277250 TCU_GearLmpBlnkngReq "TCU_GearLampBlinkingRequest";
CM_ SG_ 2164277250 TCU_FuelCutInhbtReq "TCU_FuelCutInhibitionRequest";
CM_ SG_ 2164277250 TCU_IdleUpReq "TCU_IdleUpRequest";
CM_ SG_ 2164277250 TCU_CluTrgtGearSta "TCU_ClusterTargetGear";
CM_ BO_ 2239848450 "[P] Periodic";
CM_ SG_ 2239848450 FCA_RelVel "FCA_RelativeVelocity ##2G##FCA - FCA11_FS - FCA_RelativeVelocity";
CM_ SG_ 2239848450 Nmode_FCAOff_Sta "Nmode_FCAOff_Status ##2G##FCA - FCA12 - Nmode_FCAOff_Status";
CM_ SG_ 2239848450 FCA_Jnctn_OnOffEquipSta "FCA_Junction_OnOffEquipStatus";
CM_ SG_ 2239848450 HDP_EMOpSta "HDP EM Operating State";
CM_ SG_ 2239848450 FCA_WrngTrgtDis "FCA_WarningTargetDisplay";
CM_ SG_ 2239848450 ADAS_DRV_FCA_Plus_Sta "Àü¹æÄ«¸Þ¶ó, Àü¹æ·¹ÀÌ´õ ¹× ÀüÃø¹æ ·¹ÀÌ´õ/ÈÄÃø¹æ ·¹ÀÌÅÍ Ç»Àü Æ®·¢À» ÅëÇØ FCA-Car Å¸°Ù ¹× ÀÚÂ÷ ÁÂÃø/¿ìÃø ¿µ¿ª È¸ÇÇ ºÒ°¡´É ¿©ºÎ¸¦ ÆÇ´ÜÇÏ¿© FCA-Car/Ped/Cyc+ Flag¸¦ Ãâ·Â";
CM_ SG_ 2239848450 ADAS_TrlOffStaDisp "ADAS_Trailer Off State Display";
CM_ SG_ 2239848450 FCA_FrOnOffEquipSta "FCA Front On Off Equipment State";
CM_ SG_ 2239848450 FCA_JC_OnOffEquipSta "FCA_JC On Off Equipment State";
CM_ SG_ 2239848450 FCA_FrSdOnOffEquipSta "FCA Front Side On Off Equipment State";
CM_ SG_ 2239848450 EM_WrngLvlSta "EM_WarningLevelStatus";
CM_ SG_ 2239848450 BrkDelVLimReq "Brake Delta V Limit Request";
CM_ SG_ 2239848450 ADAS_InhbtOffDispSta "ADAS Inhibit Off Display State";
CM_ SG_ 2239848450 FCA_WarnTimeSta "FCA Warning Timing State";
CM_ SG_ 2239848450 FCA_TimetoCllsn "FCA_TimetoCollision ##2G##FCA - FCA11_FS - FCA_TimetoCollision";
CM_ BO_ 2239848449 "[P] Periodic";
CM_ SG_ 2239848449 ADAS_CMD_Crc10Val "ADAS_CMD_CyclicRedundancyCheck10Value ##2G##FCA - FCA11 - CR_FCA_ChkSum";
CM_ SG_ 2239848449 ADAS_CMD_AlvCnt10Val "ADAS_CMD_AliveCounter10Value ##2G##FCA - FCA11 - CR_FCA_Alive";
CM_ SG_ 2239848449 FCA_OnOffEquipSta "FCA_OnOffEquipmentStatus ##2G##FCA - FCA12 - FCA_USM";
CM_ SG_ 2239848449 FCA_SysFlrSta "FCA_SystemFailureStatus ##2G##FCA - FCA11 - FCA_Failinfo";
CM_ SG_ 2239848449 FCA_WrngLvlSta "FCA_WarningLevelStatus ##2G##FCA - FCA11 - CF_VSM_Warn";
CM_ SG_ 2239848449 FCA_VehStpReq "FCA_VehicleStopRequest ##2G##FCA - FCA11 - FCA_StopReq";
CM_ SG_ 2239848449 FCA_StbltActvReq "FCA_SeatBeltActivateRequest ##2G##FCA - FCA11 - CF_VSM_BeltCmd";
CM_ SG_ 2239848449 FCA_HydrlcBstAsstReq "FCA_HydraulicBoostAssistRequest ##2G##FCA - FCA11 - CF_VSM_HBACmd";
CM_ SG_ 2239848449 FCA_DclReqVal "FCA_DecelerationRequestValue ##2G##FCA - FCA11 - CR_VSM_DecCmd";
CM_ SG_ 2239848449 FCA_PrefillActvReq "FCA_PrefillActivateRequest ##2G##FCA - FCA11 - CF_VSM_Prefill";
CM_ SG_ 2239848449 FCA_PartialActvReq "FCA_PartialActivateRequest";
CM_ SG_ 2239848449 FCA_FullActvReq "FCA_FullActivateRequest";
CM_ SG_ 2239848449 FCA_Regulation "FCA_Regulation";
CM_ SG_ 2239848449 FCA_SnstvtyModRetVal "FCA_SensitivityModeReturnValue ##2G##FCA - FCA12 - FCA_DrvSetState";
CM_ SG_ 2239848449 FCA_WrngSndSta "FCA warning sound status";
CM_ BO_ 2378398721 "[PE] Periodic and On Event";
CM_ SG_ 2378398721 DATC_Crc20Val "DATC_CyclicRedundancyCheck20Value";
CM_ SG_ 2378398721 DATC_AlvCnt20Val "DATC_AliveCounter20Value";
CM_ SG_ 2378398721 DATC_FragStrhUSMSta "Fragrance Strength State";
CM_ SG_ 2378398721 DATC_FragKindUSMSta "Fragrance Kind State";
CM_ SG_ 2378398721 DATC_Frag1ExpireDisp "DATC_Fragrance1ExpireDisplay";
CM_ SG_ 2378398721 DATC_FragStrhDis "Fragrance Strength Display";
CM_ SG_ 2378398721 DATC_FragKindDis "Fragrance Kind Display";
CM_ SG_ 2378398721 DATC_Frag2ExpireDisp "DATC_Fragrance2ExpireDisplay";
CM_ SG_ 2378398721 DATC_VitalityFragranceSta "DATC_VitalityFragranceState";
CM_ SG_ 2378398721 DATC_DelightFragranceSta "DATC_DelightFragranceState";
CM_ SG_ 2378398721 DATC_CareFragranceSta "DATC_CareFragranceState";
CM_ SG_ 2378398721 DATC_ComfortFragranceSta "DATC_ComfortFragranceState";
CM_ SG_ 2378398721 DATC_Frag1Inform "DATC_Fragrance1Information";
CM_ SG_ 2378398721 DATC_Frag1RemainDisp "DATC_Fragrance1RemainDisplay";
CM_ SG_ 2378398721 DATC_Frag2Inform "DATC_Fragrance2Information";
CM_ SG_ 2378398721 DATC_Frag2RemainDisp "DATC_Fragrance2RemainDisplay";
CM_ BO_ 2256644609 "[P] Periodic";
CM_ SG_ 2256644609 CLU_Crc1Val "CLU_CyclicRedundancyCheck1Value";
CM_ SG_ 2256644609 CLU_AlvCnt1Val "CLU_AliveCounter1Value";
CM_ SG_ 2256644609 CLU_DtntOutSta "CLU_DetentOutStatus";
CM_ SG_ 2256644609 CLU_SpdUnitTyp "CLU_SpeedUnitType";
CM_ SG_ 2256644609 CLU_DisSpdDcmlVal "CLU_DisplaySpeedDecimalValue";
CM_ SG_ 2256644609 CLU_SWRCCrsMainSwSta "CLU_SWRCCrsMainSwSta";
CM_ SG_ 2256644609 CLU_SWRCCrsSwSta "CLU_SWRCCrsSwSta";
CM_ SG_ 2256644609 CLU_SWRCLFASwSta "SWRC_LFASwitchStatus";
CM_ SG_ 2256644609 CLU_SWRCSldMainSwSta "SWRC_SpeedLimiterMainSwitchStatus";
CM_ SG_ 2256644609 CLU_RhstaLvlSta "CLU_RheostatLevelStatus";
CM_ SG_ 2256644609 CLU_DisSpdVal "CLU_DisplaySpeedValue";
CM_ SG_ 2256644609 CLU_OKSwSta "OK Switch On/Off State";
CM_ BO_ 2256644610 "[P] Periodic";
CM_ SG_ 2256644610 CLU_DisSpdVal_KPH "CLU_DisplaySpeedValue_KPH";
CM_ SG_ 2256644610 CLU_AutoBrightSta "CLU_AutoBrightStatus";
CM_ SG_ 2256644610 CLU_NotMinModeBrightSta "CLU_NotMinimumModeBrightStaus";
CM_ SG_ 2256644610 CLU_PwrAutoOffResetReq_HCU "reset power auto off time";
CM_ BO_ 350 "[PE] Periodic and On Event";
CM_ SG_ 350 DSAU_AirSptTimeRValueSet "Air Support Time(Massage Time) USM R Value";
CM_ SG_ 350 DSAU_DrvPostureAssistRValueSet "Drive Seat Posture Assist Function USM R Value";
CM_ SG_ 350 DSAU_DrvSmtAirSptRValueSet "Seat Smart Air Support Function USM R Value";
CM_ SG_ 350 DSAU_DrvSmtSptRValueSet "Seat Smart Support Function USM R Value";
CM_ SG_ 350 DSAU_CushSoftRValueSet "Cushion Soft R Value";
CM_ SG_ 350 DSAU_BackSoftRValueSet "Back Soft USM R Value";
CM_ SG_ 350 DSAU_AirSptModeRValueSet "Air Support Mode(Massage Mode) USM R Value";
CM_ SG_ 350 DSAU_MsgModeSts "Air Support Mode Function Operating Display";
CM_ SG_ 350 DSAU_MsgModeStrength "Air Support intensity regulation(Massage Strenth)";
CM_ SG_ 350 DSAU_MoodTrpyRValueSet "Drive Seat Mood Therapy R Value";
CM_ SG_ 350 DSAU_MoodTrpyCareSta "Drive Seat Mood Therapy Care Mode R Value";
CM_ SG_ 350 DSAU_MoodTrpyComfSta "Drive Seat Mood Therapy Comfort Mode R Value";
CM_ SG_ 350 DASU_AirSptStrRValueSet "Air Support Strenth(Massage Strenth) USM R Value";
CM_ BO_ 349 "[PE] Periodic and On Event";
CM_ SG_ 349 DSAU_CushInfDis "DSAU_CushionInflationDisplay";
CM_ SG_ 349 DSAU_CushDefDis "DSAU_CushionDeflationDisplay";
CM_ BO_ 348 "[PE] Periodic and On Event";
CM_ SG_ 348 DSAU_BolsterInfDis "DSAU_BolsterInflationDisplay";
CM_ SG_ 348 DSAU_BolsterDefDis "DSAU_BolsterDeflationDisplay";
CM_ BO_ 346 "[PE] Periodic and On Event";
CM_ SG_ 346 DPSS_WalkInSwitchSts "DPSS_WalkInSwitchStatus";
BA_DEF_ BO_  "DiagState" ENUM  "No","Yes";
BA_DEF_ BO_  "DiagResponse" ENUM  "No","Yes";
BA_DEF_ BO_  "DiagRequest" ENUM  "No","Yes";
BA_DEF_ BO_  "TpMessage" ENUM  "No","Yes";
BA_DEF_ BO_  "UsrMsgIDSforwardDeviation" INT 0 100;
BA_DEF_ BO_  "UsrMsgIDSbackwardDeviation" INT 50 1000;
BA_DEF_ BO_  "GenMsgCycleTime" INT 0 2000;
BA_DEF_ BO_  "GenMsgStartDelayTime" INT 0 2000;
BA_DEF_ BO_  "GenMsgSendType" ENUM  "Cyclic","NoMsgSendType";
BA_DEF_ BO_  "GenMsgCycleTimeFast" INT 0 500;
BA_DEF_ BO_  "GenMsgDelayTime" INT 0 20;
BA_DEF_ BO_  "GenMsgILSupport" ENUM  "No","Yes";
BA_DEF_ BO_  "GenMsgNrOfRepetition" INT 0 3;
BA_DEF_ BO_  "NmMessage" ENUM  "No","Yes";
BA_DEF_ BO_  "NWM-Botschaft" ENUM  "No","Yes";
BA_DEF_ BO_  "TpTxIndex" INT 0 65535;
BA_DEF_ BO_  "VFrameFormat" ENUM  "StandardCAN","ExtendedCAN","reserved","reserved","reserved","reserved","reserved","reserved","reserved","reserved","reserved","reserved","reserved","reserved","StandardCAN_FD","ExtendedCAN_FD";
BA_DEF_ SG_  "UserSigValidity" ENUM  "B+","ACC","IG","IG1","IG2","IG3","IG1 or IG2","IG1 or IG3","Undef";
BA_DEF_ SG_  "TimeoutValue" STRING ;
BA_DEF_ SG_  "UsrSigPurpose" ENUM  "Undef","FN","DIAG","DIAG(Req)","DIAG(Res)","DIAG(Phy)","DEV","CCP(Req)","CCP(Res)","NM","TP";
BA_DEF_ SG_  "GenSigStartValue" INT 0 1215752192;
BA_DEF_ SG_  "NetworkRequest" ENUM  "Yes","No";
BA_DEF_ SG_  "NetworkRequestHoldingTime" INT 0 65535;
BA_DEF_ SG_  "Description" STRING ;
BA_DEF_ SG_  "Version" STRING ;
BA_DEF_ SG_  "GenSigEnvVarType" ENUM  "Int","Float","Undef";
BA_DEF_ SG_  "GenSigSendType" ENUM  "Cyclic","OnWrite","OnWriteWithRepetition","OnChange","OnChangeWithRepetition","IfActive","IfActiveWithRepetition","NoSigSendType","OnChangeAndIfActive","OnChangeAndIfActiveWithRepetition";
BA_DEF_ SG_  "GwSigLatencyTime" INT 0 65536;
BA_DEF_ SG_  "GwSigMissingSourceType" ENUM  "Undef","OldValue","DefaultValue","InitialValue";
BA_DEF_ SG_  "NWM-WakeupAllowed" ENUM  "<n.a.>";
BA_DEF_ SG_  "RoutingFactor" INT 1 1215752192;
BA_DEF_ SG_  "SystemSignalLongSymbol" STRING ;
BA_DEF_REL_ BU_SG_REL_  "GenSigTimeoutTime" INT 0 7000;
BA_DEF_DEF_  "DiagState" "No";
BA_DEF_DEF_  "DiagResponse" "No";
BA_DEF_DEF_  "DiagRequest" "No";
BA_DEF_DEF_  "TpMessage" "No";
BA_DEF_DEF_  "UsrMsgIDSforwardDeviation" 10;
BA_DEF_DEF_  "UsrMsgIDSbackwardDeviation" 100;
BA_DEF_DEF_  "GenMsgCycleTime" 200;
BA_DEF_DEF_  "GenMsgStartDelayTime" 0;
BA_DEF_DEF_  "GenMsgSendType" "NoMsgSendType";
BA_DEF_DEF_  "GenMsgCycleTimeFast" 40;
BA_DEF_DEF_  "GenMsgDelayTime" 20;
BA_DEF_DEF_  "GenMsgILSupport" "Yes";
BA_DEF_DEF_  "GenMsgNrOfRepetition" 3;
BA_DEF_DEF_  "NmMessage" "No";
BA_DEF_DEF_  "NWM-Botschaft" "No";
BA_DEF_DEF_  "TpTxIndex" 0;
BA_DEF_DEF_  "VFrameFormat" "StandardCAN";
BA_DEF_DEF_  "UserSigValidity" "IG";
BA_DEF_DEF_  "TimeoutValue" "";
BA_DEF_DEF_  "UsrSigPurpose" "FN";
BA_DEF_DEF_  "GenSigStartValue" 0;
BA_DEF_DEF_  "NetworkRequest" "No";
BA_DEF_DEF_  "NetworkRequestHoldingTime" 0;
BA_DEF_DEF_  "Description" "";
BA_DEF_DEF_  "Version" "";
BA_DEF_DEF_  "GenSigEnvVarType" "Undef";
BA_DEF_DEF_  "GenSigSendType" "NoSigSendType";
BA_DEF_DEF_  "GwSigLatencyTime" 40;
BA_DEF_DEF_  "GwSigMissingSourceType" "Undef";
BA_DEF_DEF_  "NWM-WakeupAllowed" "<n.a.>";
BA_DEF_DEF_  "RoutingFactor" 1;
BA_DEF_DEF_REL_ "GenSigTimeoutTime" 500;
BA_DEF_DEF_  "SystemSignalLongSymbol" "";
BA_ "GenMsgCycleTime" BO_ 273 0;
BA_ "GenMsgSendType" BO_ 287 0;
BA_ "GenMsgSendType" BO_ 2193667332 0;
BA_ "GenMsgCycleTime" BO_ 2193667332 50;
BA_ "GenMsgCycleTimeFast" BO_ 2193667332 0;
BA_ "GenMsgNrOfRepetition" BO_ 2193667332 0;
BA_ "VFrameFormat" BO_ 2193667332 1;
BA_ "GenMsgSendType" BO_ 2193667331 0;
BA_ "GenMsgCycleTime" BO_ 2193667331 50;
BA_ "GenMsgCycleTimeFast" BO_ 2193667331 0;
BA_ "GenMsgNrOfRepetition" BO_ 2193667331 0;
BA_ "VFrameFormat" BO_ 2193667331 1;
BA_ "GenMsgSendType" BO_ 2193667330 0;
BA_ "GenMsgCycleTime" BO_ 2193667330 50;
BA_ "GenMsgCycleTimeFast" BO_ 2193667330 0;
BA_ "GenMsgNrOfRepetition" BO_ 2193667330 0;
BA_ "VFrameFormat" BO_ 2193667330 1;
BA_ "GenMsgSendType" BO_ 2193667329 0;
BA_ "GenMsgCycleTime" BO_ 2193667329 50;
BA_ "GenMsgCycleTimeFast" BO_ 2193667329 0;
BA_ "GenMsgNrOfRepetition" BO_ 2193667329 0;
BA_ "VFrameFormat" BO_ 2193667329 1;
BA_ "GenMsgSendType" BO_ 2395189761 0;
BA_ "VFrameFormat" BO_ 2395189761 1;
BA_ "GenMsgSendType" BO_ 2244048129 0;
BA_ "GenMsgCycleTime" BO_ 2244048129 100;
BA_ "GenMsgCycleTimeFast" BO_ 2244048129 0;
BA_ "GenMsgNrOfRepetition" BO_ 2244048129 0;
BA_ "VFrameFormat" BO_ 2244048129 1;
BA_ "GenMsgSendType" BO_ 271 0;
BA_ "GenMsgSendType" BO_ 2244048131 0;
BA_ "GenMsgCycleTime" BO_ 2244048131 100;
BA_ "GenMsgCycleTimeFast" BO_ 2244048131 0;
BA_ "GenMsgNrOfRepetition" BO_ 2244048131 0;
BA_ "VFrameFormat" BO_ 2244048131 1;
BA_ "GenMsgSendType" BO_ 2244048130 0;
BA_ "GenMsgCycleTime" BO_ 2244048130 100;
BA_ "GenMsgCycleTimeFast" BO_ 2244048130 0;
BA_ "GenMsgNrOfRepetition" BO_ 2244048130 0;
BA_ "VFrameFormat" BO_ 2244048130 1;
BA_ "GenMsgSendType" BO_ 2189467649 0;
BA_ "GenMsgCycleTime" BO_ 2189467649 50;
BA_ "GenMsgCycleTimeFast" BO_ 2189467649 0;
BA_ "GenMsgNrOfRepetition" BO_ 2189467649 0;
BA_ "VFrameFormat" BO_ 2189467649 1;
BA_ "GenMsgSendType" BO_ 2164277252 0;
BA_ "GenMsgCycleTime" BO_ 2164277252 50;
BA_ "GenMsgCycleTimeFast" BO_ 2164277252 0;
BA_ "GenMsgNrOfRepetition" BO_ 2164277252 0;
BA_ "VFrameFormat" BO_ 2164277252 1;
BA_ "GenMsgSendType" BO_ 2189467650 0;
BA_ "GenMsgCycleTime" BO_ 2189467650 50;
BA_ "GenMsgCycleTimeFast" BO_ 2189467650 0;
BA_ "GenMsgNrOfRepetition" BO_ 2189467650 0;
BA_ "VFrameFormat" BO_ 2189467650 1;
BA_ "GenMsgSendType" BO_ 2189467651 0;
BA_ "GenMsgCycleTime" BO_ 2189467651 50;
BA_ "GenMsgCycleTimeFast" BO_ 2189467651 0;
BA_ "GenMsgNrOfRepetition" BO_ 2189467651 0;
BA_ "VFrameFormat" BO_ 2189467651 1;
BA_ "GenMsgSendType" BO_ 2164277249 0;
BA_ "GenMsgCycleTime" BO_ 2164277249 50;
BA_ "GenMsgCycleTimeFast" BO_ 2164277249 0;
BA_ "GenMsgNrOfRepetition" BO_ 2164277249 0;
BA_ "VFrameFormat" BO_ 2164277249 1;
BA_ "GenMsgSendType" BO_ 2164277251 0;
BA_ "GenMsgCycleTime" BO_ 2164277251 50;
BA_ "GenMsgCycleTimeFast" BO_ 2164277251 0;
BA_ "GenMsgNrOfRepetition" BO_ 2164277251 0;
BA_ "VFrameFormat" BO_ 2164277251 1;
BA_ "GenMsgSendType" BO_ 2164277250 0;
BA_ "GenMsgCycleTime" BO_ 2164277250 50;
BA_ "GenMsgCycleTimeFast" BO_ 2164277250 0;
BA_ "GenMsgNrOfRepetition" BO_ 2164277250 0;
BA_ "VFrameFormat" BO_ 2164277250 1;
BA_ "GenMsgSendType" BO_ 2239848450 0;
BA_ "GenMsgCycleTime" BO_ 2239848450 100;
BA_ "GenMsgCycleTimeFast" BO_ 2239848450 0;
BA_ "GenMsgNrOfRepetition" BO_ 2239848450 0;
BA_ "VFrameFormat" BO_ 2239848450 1;
BA_ "GenMsgSendType" BO_ 2239848449 0;
BA_ "GenMsgCycleTime" BO_ 2239848449 100;
BA_ "GenMsgCycleTimeFast" BO_ 2239848449 0;
BA_ "GenMsgNrOfRepetition" BO_ 2239848449 0;
BA_ "VFrameFormat" BO_ 2239848449 1;
BA_ "GenMsgSendType" BO_ 2378398721 0;
BA_ "VFrameFormat" BO_ 2378398721 1;
BA_ "GenMsgSendType" BO_ 2256644609 0;
BA_ "GenMsgCycleTime" BO_ 2256644609 100;
BA_ "GenMsgCycleTimeFast" BO_ 2256644609 0;
BA_ "GenMsgNrOfRepetition" BO_ 2256644609 0;
BA_ "VFrameFormat" BO_ 2256644609 1;
BA_ "GenMsgSendType" BO_ 2256644610 0;
BA_ "GenMsgCycleTime" BO_ 2256644610 100;
BA_ "GenMsgCycleTimeFast" BO_ 2256644610 0;
BA_ "GenMsgNrOfRepetition" BO_ 2256644610 0;
BA_ "VFrameFormat" BO_ 2256644610 1;
BA_ "GenMsgSendType" BO_ 350 0;
BA_ "GenMsgSendType" BO_ 349 0;
BA_ "GenMsgSendType" BO_ 348 0;
BA_ "GenMsgSendType" BO_ 346 0;
BA_ "Description" SG_ 273 ARS_RrCurtainBtn "Rear Curtain Button";
BA_ "GenSigSendType" SG_ 273 ARS_RrCurtainBtn 4;
BA_ "UserSigValidity" SG_ 273 ARS_RrCurtainBtn 3;
BA_ "NetworkRequest" SG_ 273 ARS_RrCurtainBtn 0;
BA_ "NetworkRequestHoldingTime" SG_ 273 ARS_RrCurtainBtn 5000;
BA_ "Version" SG_ 273 ARS_RrCurtainBtn "22.02.05";
BA_ "Description" SG_ 287 APSS_LumbarUpSw "APSS_LumbarUpMoveSwitch";
BA_ "GenSigSendType" SG_ 287 APSS_LumbarUpSw 4;
BA_ "UserSigValidity" SG_ 287 APSS_LumbarUpSw 0;
BA_ "NetworkRequest" SG_ 287 APSS_LumbarUpSw 0;
BA_ "NetworkRequestHoldingTime" SG_ 287 APSS_LumbarUpSw 5000;
BA_ "Version" SG_ 287 APSS_LumbarUpSw "19.11.06";
BA_ "Description" SG_ 287 APSS_LumbarMidSw "APSS_LumbarMiddleSwitch";
BA_ "GenSigSendType" SG_ 287 APSS_LumbarMidSw 4;
BA_ "UserSigValidity" SG_ 287 APSS_LumbarMidSw 0;
BA_ "NetworkRequest" SG_ 287 APSS_LumbarMidSw 0;
BA_ "NetworkRequestHoldingTime" SG_ 287 APSS_LumbarMidSw 5000;
BA_ "Version" SG_ 287 APSS_LumbarMidSw "19.11.06";
BA_ "Description" SG_ 287 APSS_LumbarLowSw "APSS_LumbarLowerSwitch";
BA_ "GenSigSendType" SG_ 287 APSS_LumbarLowSw 4;
BA_ "UserSigValidity" SG_ 287 APSS_LumbarLowSw 0;
BA_ "NetworkRequest" SG_ 287 APSS_LumbarLowSw 0;
BA_ "NetworkRequestHoldingTime" SG_ 287 APSS_LumbarLowSw 5000;
BA_ "Version" SG_ 287 APSS_LumbarLowSw "19.11.06";
BA_ "Description" SG_ 287 APSS_LumbarDefSw "APSS_LumbarDeflationSwitch";
BA_ "GenSigSendType" SG_ 287 APSS_LumbarDefSw 4;
BA_ "UserSigValidity" SG_ 287 APSS_LumbarDefSw 0;
BA_ "NetworkRequest" SG_ 287 APSS_LumbarDefSw 0;
BA_ "NetworkRequestHoldingTime" SG_ 287 APSS_LumbarDefSw 5000;
BA_ "Version" SG_ 287 APSS_LumbarDefSw "19.11.06";
BA_ "Description" SG_ 287 APSS_BolsterInfSw "APSS_BolsterInflationSwitch";
BA_ "GenSigSendType" SG_ 287 APSS_BolsterInfSw 4;
BA_ "UserSigValidity" SG_ 287 APSS_BolsterInfSw 0;
BA_ "NetworkRequest" SG_ 287 APSS_BolsterInfSw 0;
BA_ "NetworkRequestHoldingTime" SG_ 287 APSS_BolsterInfSw 5000;
BA_ "Version" SG_ 287 APSS_BolsterInfSw "19.11.06";
BA_ "Description" SG_ 287 APSS_BolsterDefSw "APSS_BolsterDeflationSwitch";
BA_ "GenSigSendType" SG_ 287 APSS_BolsterDefSw 4;
BA_ "UserSigValidity" SG_ 287 APSS_BolsterDefSw 0;
BA_ "NetworkRequest" SG_ 287 APSS_BolsterDefSw 0;
BA_ "NetworkRequestHoldingTime" SG_ 287 APSS_BolsterDefSw 5000;
BA_ "Version" SG_ 287 APSS_BolsterDefSw "19.11.06";
BA_ "Description" SG_ 287 APSS_ActiveSw "Á¶¼ö¼® Äí¼Ç º¼½ºÅÍ Á¶Àý ½ºÀ§Ä¡";
BA_ "GenSigSendType" SG_ 287 APSS_ActiveSw 4;
BA_ "UserSigValidity" SG_ 287 APSS_ActiveSw 0;
BA_ "NetworkRequest" SG_ 287 APSS_ActiveSw 0;
BA_ "NetworkRequestHoldingTime" SG_ 287 APSS_ActiveSw 5000;
BA_ "Version" SG_ 287 APSS_ActiveSw "20.11.02";
BA_ "Description" SG_ 287 APSS_CushInfSw "Á¶¼ö¼® Äí¼Ç°ø¾ÐÁ¶Àý Èí±â ¹öÆ°";
BA_ "GenSigSendType" SG_ 287 APSS_CushInfSw 4;
BA_ "UserSigValidity" SG_ 287 APSS_CushInfSw 0;
BA_ "NetworkRequest" SG_ 287 APSS_CushInfSw 0;
BA_ "NetworkRequestHoldingTime" SG_ 287 APSS_CushInfSw 5000;
BA_ "Version" SG_ 287 APSS_CushInfSw "20.11.02";
BA_ "Description" SG_ 287 APSS_CushDefSw "Á¶¼ö¼® Äí¼Ç °ø¾Ð Á¶Àý ¹è±â ¹öÆ°";
BA_ "GenSigSendType" SG_ 287 APSS_CushDefSw 4;
BA_ "UserSigValidity" SG_ 287 APSS_CushDefSw 0;
BA_ "NetworkRequest" SG_ 287 APSS_CushDefSw 0;
BA_ "NetworkRequestHoldingTime" SG_ 287 APSS_CushDefSw 5000;
BA_ "Version" SG_ 287 APSS_CushDefSw "20.11.02";
BA_ "Description" SG_ 287 APSS_CushOnOffTch "ÅÍÄ¡ ½ºÀ§Ä¡ Á¤º¸";
BA_ "GenSigSendType" SG_ 287 APSS_CushOnOffTch 4;
BA_ "UserSigValidity" SG_ 287 APSS_CushOnOffTch 3;
BA_ "NetworkRequest" SG_ 287 APSS_CushOnOffTch 0;
BA_ "NetworkRequestHoldingTime" SG_ 287 APSS_CushOnOffTch 5000;
BA_ "Version" SG_ 287 APSS_CushOnOffTch "20.11.02";
BA_ "Description" SG_ 2193667332 ENG_TrgtFuelPmpPrsrVal "This signal indicates the Target Pressure of Fuel Pump";
BA_ "UserSigValidity" SG_ 2193667332 ENG_TrgtFuelPmpPrsrVal 3;
BA_ "RoutingFactor" SG_ 2193667332 ENG_TrgtFuelPmpPrsrVal 5;
BA_ "Version" SG_ 2193667332 ENG_TrgtFuelPmpPrsrVal "17.12.00";
BA_ "Description" SG_ 2193667332 ENG_VehSpdHiVal "This signal provides the one wheel velocity with resolution of 1 km/h,

and have 9 bits lengh.

In case of failure of sheel speed sensor, the value 1FF is used as error identifier";
BA_ "UserSigValidity" SG_ 2193667332 ENG_VehSpdHiVal 3;
BA_ "RoutingFactor" SG_ 2193667332 ENG_VehSpdHiVal 5;
BA_ "Version" SG_ 2193667332 ENG_VehSpdHiVal "18.01.01";
BA_ "Description" SG_ 2193667332 ENG_EngInhbNCC "This signal indicates the Inhibition of NCC MODE";
BA_ "GenSigStartValue" SG_ 2193667332 ENG_EngInhbNCC 1;
BA_ "UserSigValidity" SG_ 2193667332 ENG_EngInhbNCC 3;
BA_ "RoutingFactor" SG_ 2193667332 ENG_EngInhbNCC 5;
BA_ "Version" SG_ 2193667332 ENG_EngInhbNCC "18.04.02";
BA_ "Description" SG_ 2193667332 ENG_SldSwSta "This signal indicates the status of Speed limiter function.";
BA_ "TimeoutValue" SG_ 2193667332 ENG_SldSwSta "0x0";
BA_ "UserSigValidity" SG_ 2193667332 ENG_SldSwSta 3;
BA_ "RoutingFactor" SG_ 2193667332 ENG_SldSwSta 5;
BA_ "Version" SG_ 2193667332 ENG_SldSwSta "19.12.08";
BA_ "Description" SG_ 2193667332 ENG_SldDrvAlertDisp "If EMS sends the No Sld engaged status or Sld Disengaged status, 

Cluster shall display the status of Sld.";
BA_ "TimeoutValue" SG_ 2193667332 ENG_SldDrvAlertDisp "0x0";
BA_ "UserSigValidity" SG_ 2193667332 ENG_SldDrvAlertDisp 3;
BA_ "RoutingFactor" SG_ 2193667332 ENG_SldDrvAlertDisp 5;
BA_ "Version" SG_ 2193667332 ENG_SldDrvAlertDisp "19.12.08";
BA_ "Description" SG_ 2193667332 ENG_VehSpdLimVal "The vehicle speed which is measured by the EMS has to be sent to CLUSTER. This value is used for limiting speed of EMS. 

EMS limite vehicle speed as this value.";
BA_ "UserSigValidity" SG_ 2193667332 ENG_VehSpdLimVal 3;
BA_ "RoutingFactor" SG_ 2193667332 ENG_VehSpdLimVal 5;
BA_ "Version" SG_ 2193667332 ENG_VehSpdLimVal "18.01.01";
BA_ "Description" SG_ 2193667332 ENG_FuelCnsmptVal "The EMS uses the signal 'FCO' (FUEL CONSUMPTION) to inform other ECUs about the current consumption.";
BA_ "UserSigValidity" SG_ 2193667332 ENG_FuelCnsmptVal 3;
BA_ "RoutingFactor" SG_ 2193667332 ENG_FuelCnsmptVal 5;
BA_ "Version" SG_ 2193667332 ENG_FuelCnsmptVal "17.12.00";
BA_ "Description" SG_ 2193667331 ENG_TrgtIdleRpmVal "The stationary target speed depends principally of the engine coolant temperature.

There is a difference between the target speed for manual transmission MT and automatic transmission (AT) in ¡¯neutral¡¯ and AT in ¡¯drive¡¯. 

- Immediately after start ";
BA_ "UserSigValidity" SG_ 2193667331 ENG_TrgtIdleRpmVal 3;
BA_ "RoutingFactor" SG_ 2193667331 ENG_TrgtIdleRpmVal 5;
BA_ "Version" SG_ 2193667331 ENG_TrgtIdleRpmVal "17.12.00";
BA_ "Description" SG_ 2193667331 ENG_GearShftDnDis "This signal represents gear shift down display status. EMS transmits gear shift down status to the cluster.";
BA_ "UserSigValidity" SG_ 2193667331 ENG_GearShftDnDis 3;
BA_ "RoutingFactor" SG_ 2193667331 ENG_GearShftDnDis 5;
BA_ "Version" SG_ 2193667331 ENG_GearShftDnDis "17.12.00";
BA_ "Description" SG_ 2193667331 ENG_DsrGearPosDis "This signal represents desirable gear position of current driving condition.

EMS transmits desirable gear position to the cluster.";
BA_ "UserSigValidity" SG_ 2193667331 ENG_DsrGearPosDis 3;
BA_ "RoutingFactor" SG_ 2193667331 ENG_DsrGearPosDis 5;
BA_ "Version" SG_ 2193667331 ENG_DsrGearPosDis "17.12.00";
BA_ "Description" SG_ 2193667331 ENG_SldFuncSta "This signal indicates that if speed limiter function is active or not.

If the speed limiter function is activated then CF_Ems_SldAct = 1. Although ¡°SLD Main¡± switch is on, if the Speed limiter function is deactivated then CF_Ems_SldAct should be set t";
BA_ "UserSigValidity" SG_ 2193667331 ENG_SldFuncSta 3;
BA_ "RoutingFactor" SG_ 2193667331 ENG_SldFuncSta 5;
BA_ "Version" SG_ 2193667331 ENG_SldFuncSta "17.12.00";
BA_ "Description" SG_ 2193667331 ENG_SldActnSta "This signal indicates that if positive action of a driver at speed limiter function is active or not. If the positive action is activated then CF_Ems_SldPosAct = 1, which let the current vehicle speed to exceed the limit speed set from a driver.

If kick";
BA_ "UserSigValidity" SG_ 2193667331 ENG_SldActnSta 3;
BA_ "RoutingFactor" SG_ 2193667331 ENG_SldActnSta 5;
BA_ "Version" SG_ 2193667331 ENG_SldActnSta "17.12.00";
BA_ "Description" SG_ 2193667331 ENG_FuelTnkPrsrSta "This signal indicates that if fuel tank is high Pressure or not.

If the fuel tank is in high pressure status then CF_Ems_HPresStat = ¡®1¡¯.

If the fuel tank isn¡¯t in high pressure status then CF_Ems_HPresStat should be set to ¡®0¡¯.";
BA_ "UserSigValidity" SG_ 2193667331 ENG_FuelTnkPrsrSta 3;
BA_ "RoutingFactor" SG_ 2193667331 ENG_FuelTnkPrsrSta 5;
BA_ "Version" SG_ 2193667331 ENG_FuelTnkPrsrSta "17.12.00";
BA_ "Description" SG_ 2193667331 ENG_IsgBzrReq "This signal is for Economy Type ISG. This signal is reminding for preventing sudden starting immediately just after engine restarted or driver shift gear N to D range without braking to make auto starting.

 It transfer first 3 times why if valid one is ";
BA_ "UserSigValidity" SG_ 2193667331 ENG_IsgBzrReq 3;
BA_ "RoutingFactor" SG_ 2193667331 ENG_IsgBzrReq 5;
BA_ "Version" SG_ 2193667331 ENG_IsgBzrReq "17.12.00";
BA_ "Description" SG_ 2193667331 ENG_IsgFuelCnsmptDis "This signal is the fuel consumption during Idle stop for display to cluster. 

It transfer first 3 times during 0.001L why if valid one is missing, other valid signals are used for extra signals. So, cluster displays 0.001L at only one among three signal";
BA_ "UserSigValidity" SG_ 2193667331 ENG_IsgFuelCnsmptDis 3;
BA_ "RoutingFactor" SG_ 2193667331 ENG_IsgFuelCnsmptDis 5;
BA_ "Version" SG_ 2193667331 ENG_IsgFuelCnsmptDis "17.12.00";
BA_ "Description" SG_ 2193667331 ENG_FuelCapOpnSta "This signal indicates that if fuel cap is opened or not.

If the fuel cap is opened then CF_Ems_FCopen = 1.

If the fuel tank isn¡¯t opened then CF_Ems_FCopen should be set to ¡®0¡¯.";
BA_ "UserSigValidity" SG_ 2193667331 ENG_FuelCapOpnSta 3;
BA_ "RoutingFactor" SG_ 2193667331 ENG_FuelCapOpnSta 5;
BA_ "Version" SG_ 2193667331 ENG_FuelCapOpnSta "17.12.00";
BA_ "Description" SG_ 2193667331 ENG_EcoDrvActvSta "This signal indicates if Active Eco Drive function is active or not.

If Active Eco Drive function is active, then CF_Ems_ActEcoAct =1.";
BA_ "UserSigValidity" SG_ 2193667331 ENG_EcoDrvActvSta 3;
BA_ "RoutingFactor" SG_ 2193667331 ENG_EcoDrvActvSta 5;
BA_ "Version" SG_ 2193667331 ENG_EcoDrvActvSta "17.12.00";
BA_ "Description" SG_ 2193667331 ENG_EngRunSta "This signal is indicating normal engine running status. When engine is normal engine running state out of start, the signal turns to 1, otherwise 0 including engine stop & starting phase(cranking).";
BA_ "UserSigValidity" SG_ 2193667331 ENG_EngRunSta 3;
BA_ "RoutingFactor" SG_ 2193667331 ENG_EngRunSta 5;
BA_ "Version" SG_ 2193667331 ENG_EngRunSta "17.12.00";
BA_ "Description" SG_ 2193667331 ENG_Isg2Sta "1. ISG Status CAN message is divided by CF_EMS_IsgStat and CF_EMS_IsgStat2 

2. CF_EMS_IsgStat and CF_EMS_IsgStat2 do not duplicate the output condition

(EX: If CF_EMS_IsgStat2 is 01h~03h, CF_EMS_IsgStat is 00h)";
BA_ "UserSigValidity" SG_ 2193667331 ENG_Isg2Sta 3;
BA_ "RoutingFactor" SG_ 2193667331 ENG_Isg2Sta 5;
BA_ "Version" SG_ 2193667331 ENG_Isg2Sta "17.12.00";
BA_ "Description" SG_ 2193667331 ENG_IgnOnSta "Status of ignition lock.";
BA_ "GenSigStartValue" SG_ 2193667331 ENG_IgnOnSta 1;
BA_ "UserSigValidity" SG_ 2193667331 ENG_IgnOnSta 3;
BA_ "RoutingFactor" SG_ 2193667331 ENG_IgnOnSta 5;
BA_ "Version" SG_ 2193667331 ENG_IgnOnSta "17.12.00";
BA_ "Description" SG_ 2193667331 ENG_Ack4TcsSta "Monitoring of TCS message; the EMS checks whether at least one new message has been transferred within 500 ms, and whether there is no plausibility error in conjunction with a torque intervention. If this case occurs, the bit is set; otherwise it is rese";
BA_ "UserSigValidity" SG_ 2193667331 ENG_Ack4TcsSta 3;
BA_ "RoutingFactor" SG_ 2193667331 ENG_Ack4TcsSta 5;
BA_ "Version" SG_ 2193667331 ENG_Ack4TcsSta "17.12.00";
BA_ "Description" SG_ 2193667331 ENG_FuelCutOffSta "If the PUC_STAT - bit = 1 then the engine is in fuel cut off state, i.e. e. no injection is applied.";
BA_ "UserSigValidity" SG_ 2193667331 ENG_FuelCutOffSta 3;
BA_ "RoutingFactor" SG_ 2193667331 ENG_FuelCutOffSta 5;
BA_ "Version" SG_ 2193667331 ENG_FuelCutOffSta "17.12.00";
BA_ "Description" SG_ 2193667331 ENG_CrctTqSta "The information TQ_COR_STAT informs the TCS or the TCU whether and to which extent injection and ignition interventions are admitted.



0x0:The desired intervention regarding ignition angle retardation and cylinder shut-off is executed. (Default value)/";
BA_ "UserSigValidity" SG_ 2193667331 ENG_CrctTqSta 3;
BA_ "RoutingFactor" SG_ 2193667331 ENG_CrctTqSta 5;
BA_ "Version" SG_ 2193667331 ENG_CrctTqSta "17.12.02";
BA_ "Description" SG_ 2193667331 ENG_AirCompRlySta "The signal RLY_AC identifies the activation of the air conditioner compressor relay.";
BA_ "UserSigValidity" SG_ 2193667331 ENG_AirCompRlySta 3;
BA_ "RoutingFactor" SG_ 2193667331 ENG_AirCompRlySta 5;
BA_ "Version" SG_ 2193667331 ENG_AirCompRlySta "17.12.00";
BA_ "Description" SG_ 2193667331 ENG_LnchCntrlSta "State of Launch Control";
BA_ "UserSigValidity" SG_ 2193667331 ENG_LnchCntrlSta 3;
BA_ "RoutingFactor" SG_ 2193667331 ENG_LnchCntrlSta 5;
BA_ "Version" SG_ 2193667331 ENG_LnchCntrlSta "17.11.00";
BA_ "Description" SG_ 2193667331 ENG_EngSpdVal "This signal is generated by crankshaft segment period measurement (in case of an six-cylinder engine, this corresponds to a crankshaft angle of 120¡Æ) and measured with a resolution of 4 us.

This signal is represented as a 16 bit value.



The signal is";
BA_ "UserSigValidity" SG_ 2193667331 ENG_EngSpdVal 3;
BA_ "RoutingFactor" SG_ 2193667331 ENG_EngSpdVal 5;
BA_ "Version" SG_ 2193667331 ENG_EngSpdVal "17.12.00";
BA_ "Description" SG_ 2193667331 ENG_GearShftUpDis "This signal represents gear shift up display status. EMS transmits gear shift up status to the cluster.";
BA_ "UserSigValidity" SG_ 2193667331 ENG_GearShftUpDis 3;
BA_ "RoutingFactor" SG_ 2193667331 ENG_GearShftUpDis 5;
BA_ "Version" SG_ 2193667331 ENG_GearShftUpDis "17.12.00";
BA_ "Description" SG_ 2193667330 ENG_IndTqVal "1) In cars equipped with gasoline engines with ETC system, the signal TQI is determined on the driver¡¯s demand including cruise control and other functions and corresponds to the theoretical

engine torque. The signal comprises influences, such as the a";
BA_ "UserSigValidity" SG_ 2193667330 ENG_IndTqVal 3;
BA_ "RoutingFactor" SG_ 2193667330 ENG_IndTqVal 5;
BA_ "Version" SG_ 2193667330 ENG_IndTqVal "18.01.01";
BA_ "Description" SG_ 2193667330 ENG_IndTqBVal "TQI_B = f (actual torque + with the influence of TCS/ESC [without the influence of TCU interventions])

In cars equipped with gasoline engines with ETC system, the signal TQI is determined on actual torque.

The signal comprises influences, such as the a";
BA_ "UserSigValidity" SG_ 2193667330 ENG_IndTqBVal 3;
BA_ "RoutingFactor" SG_ 2193667330 ENG_IndTqBVal 5;
BA_ "Version" SG_ 2193667330 ENG_IndTqBVal "18.01.01";
BA_ "Description" SG_ 2193667330 ENG_EngSpdErrSta "This signal identifies an error on searching for a long tooth or on engine speed sensing.

Note : in some cases a limp-home function can be activated in the ECU (the engine speed signal is then based on the camshaft signal), and the engine may run even i";
BA_ "UserSigValidity" SG_ 2193667330 ENG_EngSpdErrSta 3;
BA_ "RoutingFactor" SG_ 2193667330 ENG_EngSpdErrSta 5;
BA_ "Version" SG_ 2193667330 ENG_EngSpdErrSta "17.12.00";
BA_ "Description" SG_ 2193667330 ENG_MafErrSta "This signal indicates error on MAF signal";
BA_ "UserSigValidity" SG_ 2193667330 ENG_MafErrSta 3;
BA_ "RoutingFactor" SG_ 2193667330 ENG_MafErrSta 5;
BA_ "Version" SG_ 2193667330 ENG_MafErrSta "17.12.00";
BA_ "Description" SG_ 2193667330 ENG_EtcLmphModSta "When ETC Mal-function occurred, EMS requests Cluster to indicate limphome mode driving and inform driver to go to AS center as soon as possible.

- In case of ETC malfunction, EMS finishes ETC control so that a vehicle goes to limphome mode driving (Forc";
BA_ "UserSigValidity" SG_ 2193667330 ENG_EtcLmphModSta 3;
BA_ "RoutingFactor" SG_ 2193667330 ENG_EtcLmphModSta 5;
BA_ "Version" SG_ 2193667330 ENG_EtcLmphModSta "17.12.00";
BA_ "Description" SG_ 2193667330 ENG_SpltInjctnSta "The signal Split_Stat identifies the split injection status. 

 * Note This message is for the GDI Delphi engine applied vehicle only.";
BA_ "UserSigValidity" SG_ 2193667330 ENG_SpltInjctnSta 3;
BA_ "RoutingFactor" SG_ 2193667330 ENG_SpltInjctnSta 5;
BA_ "Version" SG_ 2193667330 ENG_SpltInjctnSta "17.11.00";
BA_ "Description" SG_ 2193667330 ENG_MaxAirconTqVal "EMS defines the maximum allowed A/C compressor torque for drivability and engine safety.

This signal offered to A/C ECU unit only in case of the external variable A/C system installed vehicle.";
BA_ "UserSigValidity" SG_ 2193667330 ENG_MaxAirconTqVal 3;
BA_ "RoutingFactor" SG_ 2193667330 ENG_MaxAirconTqVal 5;
BA_ "Version" SG_ 2193667330 ENG_MaxAirconTqVal "17.12.00";
BA_ "Description" SG_ 2193667330 ENG_AirconPrsrSnsrVal "An EMS senses A/C pitot-tube pressure (between compressor & evaporator) directly with APT sensor.

This signal offered to A/C ECU only in case of the external variable A/C system installed vehicle.";
BA_ "UserSigValidity" SG_ 2193667330 ENG_AirconPrsrSnsrVal 3;
BA_ "RoutingFactor" SG_ 2193667330 ENG_AirconPrsrSnsrVal 5;
BA_ "Version" SG_ 2193667330 ENG_AirconPrsrSnsrVal "17.12.00";
BA_ "Description" SG_ 2193667330 ENG_IsgSta "1. ISG Status expressing CAN message divided by CF_EMS_IsgStat and CF_EMS_IsgStat2 

2. In EMS , CF_EMS_IsgStat and CF_EMS_IsgStat2 do not duplicate the output condition

(EX: If CF_EMS_IsgStat is 01h~07h, CF_EMS_IsgStat2 is 00h)



0x0:ISG is not operat";
BA_ "UserSigValidity" SG_ 2193667330 ENG_IsgSta 3;
BA_ "RoutingFactor" SG_ 2193667330 ENG_IsgSta 5;
BA_ "Version" SG_ 2193667330 ENG_IsgSta "17.12.02";
BA_ "Description" SG_ 2193667330 ENG_OilLvlSta "This signal indicates the replace time of engine oil.";
BA_ "UserSigValidity" SG_ 2193667330 ENG_OilLvlSta 3;
BA_ "RoutingFactor" SG_ 2193667330 ENG_OilLvlSta 5;
BA_ "Version" SG_ 2193667330 ENG_OilLvlSta "17.12.00";
BA_ "Description" SG_ 2193667329 EMS_Crc1Val "The data area for CRC calculation is based on the data length (DLC) of the message DB.

The CRC shall be calculated over the entire data block (excluding the CRC bytes) including the user data, alive counter and Data ID



- CRC Polynomial (0x1021) , Ini";
BA_ "GenSigStartValue" SG_ 2193667329 EMS_Crc1Val 65535;
BA_ "UserSigValidity" SG_ 2193667329 EMS_Crc1Val 3;
BA_ "RoutingFactor" SG_ 2193667329 EMS_Crc1Val 5;
BA_ "Version" SG_ 2193667329 EMS_Crc1Val "21.09.03";
BA_ "Description" SG_ 2193667329 EMS_AlvCnt1Val "For the first transmission request for a data element the counter shall be initialized with 0 and shall be incremented by 1 for every subsequent send request. 

When the counter reaches the maximum value(0xFF), then it shall restart with 0 for the next s";
BA_ "UserSigValidity" SG_ 2193667329 EMS_AlvCnt1Val 3;
BA_ "RoutingFactor" SG_ 2193667329 EMS_AlvCnt1Val 5;
BA_ "Version" SG_ 2193667329 EMS_AlvCnt1Val "21.09.03";
BA_ "Description" SG_ 2193667329 ENG_CrctEngTqVal "This signal comprises the actual indicated engine torque (determined by calculation within the engine management system) (lambda control, knock control, catalyst overheating prevention function, temperature influences, TCS, TCU torque intervention etc. b";
BA_ "UserSigValidity" SG_ 2193667329 ENG_CrctEngTqVal 3;
BA_ "RoutingFactor" SG_ 2193667329 ENG_CrctEngTqVal 5;
BA_ "Version" SG_ 2193667329 ENG_CrctEngTqVal "18.01.03";
BA_ "Description" SG_ 2193667329 ENG_StndTqRatioVal "This factor is calculated inside the ECU to express the long-term changes of the engine torque capabilities due to special operating conditions. It takes into consideration mainly the ambient pressure, the ambient air temperature, and the fuel quality. I";
BA_ "GenSigStartValue" SG_ 2193667329 ENG_StndTqRatioVal 127;
BA_ "UserSigValidity" SG_ 2193667329 ENG_StndTqRatioVal 3;
BA_ "RoutingFactor" SG_ 2193667329 ENG_StndTqRatioVal 5;
BA_ "Version" SG_ 2193667329 ENG_StndTqRatioVal "17.12.00";
BA_ "Description" SG_ 2193667329 ENG_FrctTqVal "This signal identifies the current engine friction loss torque. It is stored as a function of 'EngClntTempVal' and 'EngSpdVal' (FrctTqVal = f(EngClntTempVal, EngSpdVal)) in terms of an index table.

The index table is corrected depending on the current l";
BA_ "UserSigValidity" SG_ 2193667329 ENG_FrctTqVal 3;
BA_ "RoutingFactor" SG_ 2193667329 ENG_FrctTqVal 5;
BA_ "Version" SG_ 2193667329 ENG_FrctTqVal "18.01.01";
BA_ "Description" SG_ 2395189761 DATC_Crc10Val "The data area for CRC calculation is based on the data length (DLC) of the message DB.

The CRC shall be calculated over the entire data block (excluding the CRC bytes) including the user data, alive counter and Data ID



- CRC Polynomial (0x1021) , Ini";
BA_ "GenSigSendType" SG_ 2395189761 DATC_Crc10Val 4;
BA_ "GenSigStartValue" SG_ 2395189761 DATC_Crc10Val 65535;
BA_ "UserSigValidity" SG_ 2395189761 DATC_Crc10Val 3;
BA_ "Version" SG_ 2395189761 DATC_Crc10Val "21.09.03";
BA_ "Description" SG_ 2395189761 DATC_AlvCnt10Val "For the first transmission request for a data element the counter shall be initialized with 0 and shall be incremented by 1 for every subsequent send request. 

When the counter reaches the maximum value(0xFF), then it shall restart with 0 for the next s";
BA_ "GenSigSendType" SG_ 2395189761 DATC_AlvCnt10Val 4;
BA_ "UserSigValidity" SG_ 2395189761 DATC_AlvCnt10Val 3;
BA_ "Version" SG_ 2395189761 DATC_AlvCnt10Val "21.09.03";
BA_ "Description" SG_ 2395189761 DATC_Typ "HTR CONTROL TYPE

Bit0 (FR Control) : 0 ? ATC / 1 ? MTC

Bit1~2 (Temp) : 0 ? Single / 1 ? Dual / 2 ? 3Zone / 3 ? 4Zone

Bit3~4 (Mode) : 0 ? Single / 1 ? Dual / 2 ? 3Zone / 3 ? 4Zone

Bit5 (Rear Control) : 0 ? None or MTC / 1- ATC

Bit6 (RHD) : 0 ? LHD / ";
BA_ "GenSigSendType" SG_ 2395189761 DATC_Typ 4;
BA_ "UserSigValidity" SG_ 2395189761 DATC_Typ 3;
BA_ "Version" SG_ 2395189761 DATC_Typ "20.03.01";
BA_ "Description" SG_ 2395189761 DATC_Opt1Typ "Bit0 : (ADS) : 0 - Non ADS / 1 - ADS

Bit1 : (AQS) : 0 - Non AQS / 1 ? AQS

Bit2 : (MAX AC) : 0 - Non MAX AC / 1 - MAX AC

Bit3 : (SYNC) : 0 - Non SYNC / 1 - SYNC

Bit4 : (DUST) : 0 - Non AIR PURIFIER / 1 - AIR PURIFIER

Bit5 : (Smart_Vent) : 0 - Non SMA";
BA_ "GenSigSendType" SG_ 2395189761 DATC_Opt1Typ 4;
BA_ "UserSigValidity" SG_ 2395189761 DATC_Opt1Typ 3;
BA_ "Version" SG_ 2395189761 DATC_Opt1Typ "18.05.00";
BA_ "Description" SG_ 2395189761 DATC_Opt3Typ "This signal indicates Option of HTR Control.



Bit0~1 (Button Type)  : 0 ? Not Display in AVN /

                              1 ? Single (Blower-Temp-Mode) /

                              2 ? Single (Temp-Mode-Blower) / 

                             ";
BA_ "GenSigSendType" SG_ 2395189761 DATC_Opt3Typ 4;
BA_ "UserSigValidity" SG_ 2395189761 DATC_Opt3Typ 3;
BA_ "Version" SG_ 2395189761 DATC_Opt3Typ "18.11.00";
BA_ "Description" SG_ 2395189761 DATC_Opt2Typ "Bit0 : (FRONT BLOWER) : 0 - SINGLE BLOWER / 1 ? DUAL BLOWER

Bit1 : (FRONT AUTO ZONE) : 0 - SINGLE AUTO / 1 - DUAL AUTO

Bit2 : (LCD / NON LCD TYPE) : 0 - NON LCD /  1 - LCD TYPE

Bit3 : (INDIRECT VENT) : 0 - NON INDIRECT VENT /  1 - INDIRECT VENT

HTR C";
BA_ "GenSigSendType" SG_ 2395189761 DATC_Opt2Typ 4;
BA_ "UserSigValidity" SG_ 2395189761 DATC_Opt2Typ 3;
BA_ "Version" SG_ 2395189761 DATC_Opt2Typ "19.04.06";
BA_ "Description" SG_ 2395189761 DATC_Opt4Typ "This signal indicates Option of HTR Control.



Bit0 (Driver Only Button) :  0 ? NOT Apply / 1 ? Apply

Bit1 (HEAT Button) :  0 ? NOT Apply / 1 ? Apply

Bit2 (Multi-Air Mode) : 0 ? Not Apply / 1 - Apply

Bit3 : (Scheduled Ventilation) : 0 ? Not Apply / 1";
BA_ "GenSigSendType" SG_ 2395189761 DATC_Opt4Typ 4;
BA_ "UserSigValidity" SG_ 2395189761 DATC_Opt4Typ 7;
BA_ "Version" SG_ 2395189761 DATC_Opt4Typ "19.08.08";
BA_ "Description" SG_ 2395189761 DATC_TxtPopupReq "DATC TEXT Pop-up";
BA_ "GenSigSendType" SG_ 2395189761 DATC_TxtPopupReq 4;
BA_ "UserSigValidity" SG_ 2395189761 DATC_TxtPopupReq 3;
BA_ "Version" SG_ 2395189761 DATC_TxtPopupReq "17.11.00";
BA_ "Description" SG_ 2395189761 DATC_StrWhlUSMSta "DATC and Steering Wheel heat Control Display request signal";
BA_ "GenSigSendType" SG_ 2395189761 DATC_StrWhlUSMSta 4;
BA_ "UserSigValidity" SG_ 2395189761 DATC_StrWhlUSMSta 3;
BA_ "Version" SG_ 2395189761 DATC_StrWhlUSMSta "18.03.05";
BA_ "Description" SG_ 2395189761 DATC_StrWhlHtngReq "Steering Wheel heat function on/off request";
BA_ "GenSigSendType" SG_ 2395189761 DATC_StrWhlHtngReq 4;
BA_ "UserSigValidity" SG_ 2395189761 DATC_StrWhlHtngReq 3;
BA_ "Version" SG_ 2395189761 DATC_StrWhlHtngReq "18.01.07";
BA_ "Description" SG_ 2244048129 ESC_Crc3Val "The data area for CRC calculation is based on the data length (DLC) of the message DB.

The CRC shall be calculated over the entire data block (excluding the CRC bytes) including the user data, alive counter and Data ID



- CRC Polynomial (0x1021) , Ini";
BA_ "GenSigStartValue" SG_ 2244048129 ESC_Crc3Val 65535;
BA_ "UserSigValidity" SG_ 2244048129 ESC_Crc3Val 3;
BA_ "RoutingFactor" SG_ 2244048129 ESC_Crc3Val 5;
BA_ "Version" SG_ 2244048129 ESC_Crc3Val "21.09.03";
BA_ "Description" SG_ 2244048129 ESC_AlvCnt3Val "For the first transmission request for a data element the counter shall be initialized with 0 and shall be incremented by 1 for every subsequent send request. 

When the counter reaches the maximum value(0xFF), then it shall restart with 0 for the next s";
BA_ "UserSigValidity" SG_ 2244048129 ESC_AlvCnt3Val 3;
BA_ "RoutingFactor" SG_ 2244048129 ESC_AlvCnt3Val 5;
BA_ "Version" SG_ 2244048129 ESC_AlvCnt3Val "21.09.03";
BA_ "Description" SG_ 2244048129 SCC_TqIntrvntnVal "The indicated torque command TQI_ACC is the basic control path to the engine power control. This command has the same priority in the torque-structure than the driver¡¯s demand torque. The maximum value of either TQI_ACC or the driver torque is selected ";
BA_ "UserSigValidity" SG_ 2244048129 SCC_TqIntrvntnVal 3;
BA_ "RoutingFactor" SG_ 2244048129 SCC_TqIntrvntnVal 5;
BA_ "Version" SG_ 2244048129 SCC_TqIntrvntnVal "17.12.00";
BA_ "Description" SG_ 2244048129 ESC_VehAccelVal "The vehicle acceleration ACCEL_REF_ACC displays the feedback signal for the inner acceleration control loop since it is the SCC-internal acceleration command value. In addition this signal is used to calculate the target object acceleration. If the requi";
BA_ "UserSigValidity" SG_ 2244048129 ESC_VehAccelVal 3;
BA_ "RoutingFactor" SG_ 2244048129 ESC_VehAccelVal 5;
BA_ "Version" SG_ 2244048129 ESC_VehAccelVal "17.12.00";
BA_ "Description" SG_ 2244048129 ESC_AccelBasisVal "This value is used to initialize the acceleration control when SCC is engaged or after driver override.";
BA_ "UserSigValidity" SG_ 2244048129 ESC_AccelBasisVal 3;
BA_ "RoutingFactor" SG_ 2244048129 ESC_AccelBasisVal 5;
BA_ "Version" SG_ 2244048129 ESC_AccelBasisVal "17.12.00";
BA_ "Description" SG_ 2244048129 PWI_STATE "This signal indicates brake pad wear state. If the brake pad is worn to the designted amount, this signal is used to indicate the alarm on the cluster";
BA_ "UserSigValidity" SG_ 2244048129 PWI_STATE 3;
BA_ "RoutingFactor" SG_ 2244048129 PWI_STATE 5;
BA_ "Version" SG_ 2244048129 PWI_STATE "21.04.02";
BA_ "Description" SG_ 271 ASAU_AirSptTimeRValueSet "Air Support Time(Massage Time) USM R Value";
BA_ "GenSigSendType" SG_ 271 ASAU_AirSptTimeRValueSet 4;
BA_ "UserSigValidity" SG_ 271 ASAU_AirSptTimeRValueSet 3;
BA_ "NetworkRequest" SG_ 271 ASAU_AirSptTimeRValueSet 0;
BA_ "NetworkRequestHoldingTime" SG_ 271 ASAU_AirSptTimeRValueSet 5000;
BA_ "Version" SG_ 271 ASAU_AirSptTimeRValueSet "19.11.06";
BA_ "Description" SG_ 271 ASAU_AstSmtAirSptRValueSet "Seat Smart Air Support Function USM R Value";
BA_ "GenSigSendType" SG_ 271 ASAU_AstSmtAirSptRValueSet 4;
BA_ "UserSigValidity" SG_ 271 ASAU_AstSmtAirSptRValueSet 3;
BA_ "NetworkRequest" SG_ 271 ASAU_AstSmtAirSptRValueSet 0;
BA_ "NetworkRequestHoldingTime" SG_ 271 ASAU_AstSmtAirSptRValueSet 5000;
BA_ "Version" SG_ 271 ASAU_AstSmtAirSptRValueSet "19.12.00";
BA_ "Description" SG_ 271 ASAU_CushSoftRValueSet "Cushion Soft R Value";
BA_ "GenSigSendType" SG_ 271 ASAU_CushSoftRValueSet 4;
BA_ "UserSigValidity" SG_ 271 ASAU_CushSoftRValueSet 3;
BA_ "NetworkRequest" SG_ 271 ASAU_CushSoftRValueSet 0;
BA_ "NetworkRequestHoldingTime" SG_ 271 ASAU_CushSoftRValueSet 5000;
BA_ "Version" SG_ 271 ASAU_CushSoftRValueSet "20.04.02";
BA_ "Description" SG_ 271 ASAU_BackSoftRValueSet "Back Soft USM R Value";
BA_ "GenSigSendType" SG_ 271 ASAU_BackSoftRValueSet 4;
BA_ "UserSigValidity" SG_ 271 ASAU_BackSoftRValueSet 3;
BA_ "NetworkRequest" SG_ 271 ASAU_BackSoftRValueSet 0;
BA_ "NetworkRequestHoldingTime" SG_ 271 ASAU_BackSoftRValueSet 5000;
BA_ "Version" SG_ 271 ASAU_BackSoftRValueSet "20.04.02";
BA_ "Description" SG_ 271 ASAU_AirSptModeRValueSet "Air Support Mode(Massage Mode) USM R Value";
BA_ "GenSigSendType" SG_ 271 ASAU_AirSptModeRValueSet 4;
BA_ "UserSigValidity" SG_ 271 ASAU_AirSptModeRValueSet 3;
BA_ "NetworkRequest" SG_ 271 ASAU_AirSptModeRValueSet 0;
BA_ "NetworkRequestHoldingTime" SG_ 271 ASAU_AirSptModeRValueSet 5000;
BA_ "Version" SG_ 271 ASAU_AirSptModeRValueSet "19.11.06";
BA_ "Description" SG_ 271 ASAU_NotFootMsgOperStaWarnPE "Passenger Foot Massage Operation Disable Mode";
BA_ "GenSigSendType" SG_ 271 ASAU_NotFootMsgOperStaWarnPE 4;
BA_ "UserSigValidity" SG_ 271 ASAU_NotFootMsgOperStaWarnPE 3;
BA_ "NetworkRequest" SG_ 271 ASAU_NotFootMsgOperStaWarnPE 0;
BA_ "NetworkRequestHoldingTime" SG_ 271 ASAU_NotFootMsgOperStaWarnPE 5000;
BA_ "Version" SG_ 271 ASAU_NotFootMsgOperStaWarnPE "20.08.00";
BA_ "Description" SG_ 271 ASAU_RRFootAirSptRValueSet "Foot Air Support USM R Value";
BA_ "GenSigSendType" SG_ 271 ASAU_RRFootAirSptRValueSet 4;
BA_ "UserSigValidity" SG_ 271 ASAU_RRFootAirSptRValueSet 3;
BA_ "NetworkRequest" SG_ 271 ASAU_RRFootAirSptRValueSet 0;
BA_ "NetworkRequestHoldingTime" SG_ 271 ASAU_RRFootAirSptRValueSet 5000;
BA_ "Version" SG_ 271 ASAU_RRFootAirSptRValueSet "19.12.00";
BA_ "Description" SG_ 271 ASAU_RRFootAirSptHeatRValueSet "Foot Air Support Heat USM R Value";
BA_ "GenSigSendType" SG_ 271 ASAU_RRFootAirSptHeatRValueSet 4;
BA_ "UserSigValidity" SG_ 271 ASAU_RRFootAirSptHeatRValueSet 3;
BA_ "NetworkRequest" SG_ 271 ASAU_RRFootAirSptHeatRValueSet 0;
BA_ "NetworkRequestHoldingTime" SG_ 271 ASAU_RRFootAirSptHeatRValueSet 5000;
BA_ "Version" SG_ 271 ASAU_RRFootAirSptHeatRValueSet "20.01.02";
BA_ "Description" SG_ 271 ASAU_MoodTrpyRValueSet "Passenger Seat Mood Therapy R Value";
BA_ "GenSigSendType" SG_ 271 ASAU_MoodTrpyRValueSet 4;
BA_ "UserSigValidity" SG_ 271 ASAU_MoodTrpyRValueSet 3;
BA_ "NetworkRequest" SG_ 271 ASAU_MoodTrpyRValueSet 0;
BA_ "NetworkRequestHoldingTime" SG_ 271 ASAU_MoodTrpyRValueSet 5000;
BA_ "Version" SG_ 271 ASAU_MoodTrpyRValueSet "20.07.03";
BA_ "Description" SG_ 271 ASAU_MoodTrpyCareSta "Passenger Seat Mood Therapy Care Mode R Value";
BA_ "GenSigSendType" SG_ 271 ASAU_MoodTrpyCareSta 4;
BA_ "UserSigValidity" SG_ 271 ASAU_MoodTrpyCareSta 3;
BA_ "NetworkRequest" SG_ 271 ASAU_MoodTrpyCareSta 0;
BA_ "NetworkRequestHoldingTime" SG_ 271 ASAU_MoodTrpyCareSta 5000;
BA_ "Version" SG_ 271 ASAU_MoodTrpyCareSta "20.07.12";
BA_ "Description" SG_ 271 ASAU_MoodTrpyComfSta "Passenger Seat Mood Therapy Comfort Mode R Value";
BA_ "GenSigSendType" SG_ 271 ASAU_MoodTrpyComfSta 4;
BA_ "UserSigValidity" SG_ 271 ASAU_MoodTrpyComfSta 3;
BA_ "NetworkRequest" SG_ 271 ASAU_MoodTrpyComfSta 0;
BA_ "NetworkRequestHoldingTime" SG_ 271 ASAU_MoodTrpyComfSta 5000;
BA_ "Version" SG_ 271 ASAU_MoodTrpyComfSta "20.07.12";
BA_ "Description" SG_ 271 ASAU_AirSptStrRValueSet "Air Support Strenth(Massage Strenth) USM R Value";
BA_ "GenSigSendType" SG_ 271 ASAU_AirSptStrRValueSet 4;
BA_ "UserSigValidity" SG_ 271 ASAU_AirSptStrRValueSet 3;
BA_ "NetworkRequest" SG_ 271 ASAU_AirSptStrRValueSet 0;
BA_ "NetworkRequestHoldingTime" SG_ 271 ASAU_AirSptStrRValueSet 5000;
BA_ "Version" SG_ 271 ASAU_AirSptStrRValueSet "20.07.11";
BA_ "Description" SG_ 2244048131 ESC_RccaSta "RCCA Brake Function Status";
BA_ "UserSigValidity" SG_ 2244048131 ESC_RccaSta 3;
BA_ "RoutingFactor" SG_ 2244048131 ESC_RccaSta 5;
BA_ "Version" SG_ 2244048131 ESC_RccaSta "17.12.00";
BA_ "Description" SG_ 2244048131 ESC_RspaCanFlFlag "This signal indicates RSPA CAN failure value.

E.g. Timeout, CRC error, Alive counter error, out of range signal value¡¦";
BA_ "UserSigValidity" SG_ 2244048131 ESC_RspaCanFlFlag 3;
BA_ "RoutingFactor" SG_ 2244048131 ESC_RspaCanFlFlag 5;
BA_ "Version" SG_ 2244048131 ESC_RspaCanFlFlag "17.12.00";
BA_ "Description" SG_ 2244048131 ESC_RspaDclActv "This signal indicates the additional braking control is activated for RSPA.

ESC activate additional deceleration to minimize vehicle speed overshoot.";
BA_ "UserSigValidity" SG_ 2244048131 ESC_RspaDclActv 3;
BA_ "RoutingFactor" SG_ 2244048131 ESC_RspaDclActv 5;
BA_ "Version" SG_ 2244048131 ESC_RspaDclActv "17.12.00";
BA_ "Description" SG_ 2244048131 ESC_RspaStandStill "This signal indicates confirmation for standstill of the vehicle.";
BA_ "UserSigValidity" SG_ 2244048131 ESC_RspaStandStill 3;
BA_ "RoutingFactor" SG_ 2244048131 ESC_RspaStandStill 5;
BA_ "Version" SG_ 2244048131 ESC_RspaStandStill "17.12.00";
BA_ "Description" SG_ 2244048131 ESC_PcaSta "PCA-R Brake Status";
BA_ "UserSigValidity" SG_ 2244048131 ESC_PcaSta 3;
BA_ "RoutingFactor" SG_ 2244048131 ESC_PcaSta 5;
BA_ "Version" SG_ 2244048131 ESC_PcaSta "17.12.06";
BA_ "Description" SG_ 2244048131 MCB_ReqBrkAck "This signal is about communication with ACU. It is changed with ACU_ReqBrk_By_PCB signal value.

If ESC receive 0x1 or 0x2 value of ACU_ReqBrk_By_PCB, signal value of MCB_ReqBrkAck change to 0x1.

If ESC receive 0x0 value of ACU_ReqBrk_By_PCB, signal val";
BA_ "UserSigValidity" SG_ 2244048131 MCB_ReqBrkAck 3;
BA_ "RoutingFactor" SG_ 2244048131 MCB_ReqBrkAck 5;
BA_ "Version" SG_ 2244048131 MCB_ReqBrkAck "18.12.05";
BA_ "Description" SG_ 2244048131 MCB_CtlSta "This signal indicate MCB activation status.";
BA_ "UserSigValidity" SG_ 2244048131 MCB_CtlSta 3;
BA_ "RoutingFactor" SG_ 2244048131 MCB_CtlSta 5;
BA_ "Version" SG_ 2244048131 MCB_CtlSta "19.05.02";
BA_ "Description" SG_ 2244048131 MCB_DefSta "This signal indicate MCB defective status.";
BA_ "UserSigValidity" SG_ 2244048131 MCB_DefSta 3;
BA_ "RoutingFactor" SG_ 2244048131 MCB_DefSta 5;
BA_ "Version" SG_ 2244048131 MCB_DefSta "19.05.02";
BA_ "Description" SG_ 2244048131 ESC_DiffBrkFuncSta "This is ESC status for Differential brake function.";
BA_ "UserSigValidity" SG_ 2244048131 ESC_DiffBrkFuncSta 3;
BA_ "RoutingFactor" SG_ 2244048131 ESC_DiffBrkFuncSta 5;
BA_ "Version" SG_ 2244048131 ESC_DiffBrkFuncSta "17.12.00";
BA_ "Description" SG_ 2244048131 ESC_LsdLimMod "This signal indicates the request for eLSD torque limit mode.

0x0:Maximum limitation mode

0x1:Minimum limitation mode";
BA_ "UserSigValidity" SG_ 2244048131 ESC_LsdLimMod 3;
BA_ "RoutingFactor" SG_ 2244048131 ESC_LsdLimMod 5;
BA_ "Version" SG_ 2244048131 ESC_LsdLimMod "18.05.02";
BA_ "Description" SG_ 2244048131 ESC_LsdOpn "This signal indicates the command for eLSD clutch open mode.";
BA_ "UserSigValidity" SG_ 2244048131 ESC_LsdOpn 3;
BA_ "RoutingFactor" SG_ 2244048131 ESC_LsdOpn 5;
BA_ "Version" SG_ 2244048131 ESC_LsdOpn "20.08.05";
BA_ "Description" SG_ 2244048131 ESC_LsdTqLim "This signal indicates the request for the value of the torquel limit of eLSD.

0xFFFF : Error";
BA_ "GenSigStartValue" SG_ 2244048131 ESC_LsdTqLim 64255;
BA_ "UserSigValidity" SG_ 2244048131 ESC_LsdTqLim 3;
BA_ "RoutingFactor" SG_ 2244048131 ESC_LsdTqLim 5;
BA_ "Version" SG_ 2244048131 ESC_LsdTqLim "18.05.02";
BA_ "Description" SG_ 2244048131 ESC_BcaRPlusSta "BCA-R+ Brake Function Status";
BA_ "UserSigValidity" SG_ 2244048131 ESC_BcaRPlusSta 3;
BA_ "RoutingFactor" SG_ 2244048131 ESC_BcaRPlusSta 5;
BA_ "Version" SG_ 2244048131 ESC_BcaRPlusSta "17.12.07";
BA_ "Description" SG_ 2244048131 ESC_RspaSta "This signal indicates RSPA assistant control mode of ESC";
BA_ "GenSigStartValue" SG_ 2244048131 ESC_RspaSta 1;
BA_ "UserSigValidity" SG_ 2244048131 ESC_RspaSta 3;
BA_ "RoutingFactor" SG_ 2244048131 ESC_RspaSta 5;
BA_ "Version" SG_ 2244048131 ESC_RspaSta "17.12.00";
BA_ "Description" SG_ 2244048130 SCC_OptTyp "This value is used for SCC is equipped or not.

Do not recognize 0x3(Not Coded) as failure.";
BA_ "UserSigValidity" SG_ 2244048130 SCC_OptTyp 3;
BA_ "RoutingFactor" SG_ 2244048130 SCC_OptTyp 5;
BA_ "Version" SG_ 2244048130 SCC_OptTyp "18.12.04";
BA_ "Description" SG_ 2244048130 ESC_BrkLtReq "Flag from TCS which activates the illumination of the brake lights during automatic braking.";
BA_ "UserSigValidity" SG_ 2244048130 ESC_BrkLtReq 3;
BA_ "RoutingFactor" SG_ 2244048130 ESC_BrkLtReq 5;
BA_ "Version" SG_ 2244048130 ESC_BrkLtReq "17.12.00";
BA_ "Description" SG_ 2244048130 ESC_DclEnblReq "This signal enables the deceleration control to accept command values axvCv from SCC. This flag is complementary to the ACC_REQ flag if SCC is in active mode.";
BA_ "UserSigValidity" SG_ 2244048130 ESC_DclEnblReq 3;
BA_ "RoutingFactor" SG_ 2244048130 ESC_DclEnblReq 5;
BA_ "Version" SG_ 2244048130 ESC_DclEnblReq "17.12.00";
BA_ "Description" SG_ 2244048130 ESC_DrvOvrdSta "This signal indicates that acceleration or deceleration value of driver¡¯s requirement is greater than SCC setting value.";
BA_ "UserSigValidity" SG_ 2244048130 ESC_DrvOvrdSta 3;
BA_ "RoutingFactor" SG_ 2244048130 ESC_DrvOvrdSta 5;
BA_ "Version" SG_ 2244048130 ESC_DrvOvrdSta "17.12.00";
BA_ "Description" SG_ 2244048130 ESC_DrvBrkSta "This signal indicates flag from ESC to SCC to indicate the driver braking state";
BA_ "UserSigValidity" SG_ 2244048130 ESC_DrvBrkSta 3;
BA_ "RoutingFactor" SG_ 2244048130 ESC_DrvBrkSta 5;
BA_ "Version" SG_ 2244048130 ESC_DrvBrkSta "17.12.00";
BA_ "Description" SG_ 2244048130 SCC_EnblReq "This signal is set by the safety logic in the TCS/ESC. The safety logic shall monitor the following:

1. A temporary failure in the vehicle does not allow SCC (Brakes are overheated, etc¡¦). 

SCC is disabled reversible.

2. SCC communication failure (ti";
BA_ "UserSigValidity" SG_ 2244048130 SCC_EnblReq 3;
BA_ "RoutingFactor" SG_ 2244048130 SCC_EnblReq 5;
BA_ "Version" SG_ 2244048130 SCC_EnblReq "17.12.00";
BA_ "Description" SG_ 2244048130 ESC_DrvBrkActvSta "This signal indicates that a driver is pressing the brake pedal or not.";
BA_ "UserSigValidity" SG_ 2244048130 ESC_DrvBrkActvSta 3;
BA_ "RoutingFactor" SG_ 2244048130 ESC_DrvBrkActvSta 5;
BA_ "Version" SG_ 2244048130 ESC_DrvBrkActvSta "17.12.00";
BA_ "Description" SG_ 2244048130 ESC_PrkBrkActvSta "This signal indicates whether the parking brake is activated or not.";
BA_ "UserSigValidity" SG_ 2244048130 ESC_PrkBrkActvSta 3;
BA_ "RoutingFactor" SG_ 2244048130 ESC_PrkBrkActvSta 5;
BA_ "Version" SG_ 2244048130 ESC_PrkBrkActvSta "17.12.00";
BA_ "Description" SG_ 2244048130 ESC_HDP_FltMonSta "ÀÌ ½ÅÈ£´Â IEB (ESC)°¡ HDP Á¦¾î±â(Main/Sub)ÀÇ »óÅÂ¸¦ ¸ð´ÏÅÍ¸µÇÑ °á°úÀÌ´Ù.

This signal is the result of the IEB (ESC) monitoring the state of the HDP controller (Main/Sub).";
BA_ "UserSigValidity" SG_ 2244048130 ESC_HDP_FltMonSta 3;
BA_ "RoutingFactor" SG_ 2244048130 ESC_HDP_FltMonSta 5;
BA_ "Version" SG_ 2244048130 ESC_HDP_FltMonSta "21.04.00";
BA_ "Description" SG_ 2244048130 ESC_HDPSpprtSWVer "Software version of IEB/RCU that supports HDP function";
BA_ "UserSigValidity" SG_ 2244048130 ESC_HDPSpprtSWVer 3;
BA_ "RoutingFactor" SG_ 2244048130 ESC_HDPSpprtSWVer 5;
BA_ "Version" SG_ 2244048130 ESC_HDPSpprtSWVer "21.12.07";
BA_ "Description" SG_ 2244048130 FCA_EquipSta "FCA Equipment Status

Do not recognize 0x3(Not Coded) as failure.";
BA_ "UserSigValidity" SG_ 2244048130 FCA_EquipSta 3;
BA_ "RoutingFactor" SG_ 2244048130 FCA_EquipSta 5;
BA_ "Version" SG_ 2244048130 FCA_EquipSta "18.12.04";
BA_ "Description" SG_ 2244048130 FCA_AvlblSta "This signal indicates state signal from ESC to FCA which tells if ESC is 'Available', 'Temporarily not available', 'Permanently not available' or 'FCA Communication Error'.";
BA_ "UserSigValidity" SG_ 2244048130 FCA_AvlblSta 3;
BA_ "RoutingFactor" SG_ 2244048130 FCA_AvlblSta 5;
BA_ "Version" SG_ 2244048130 FCA_AvlblSta "18.02.00";
BA_ "Description" SG_ 2244048130 ESC_FCA_ActvSta "This signal specifies the status of control for FCA control request flag.

(FCA Á¦¾î ¿äÃ»¿¡ ´ëÇÑ Á¦µ¿ Á¦¾î±â ¼öÇà¿©ºÎ È®ÀÎÀ» À§ÇÑ Á¤º¸ ½ÅÈ£)";
BA_ "UserSigValidity" SG_ 2244048130 ESC_FCA_ActvSta 3;
BA_ "RoutingFactor" SG_ 2244048130 ESC_FCA_ActvSta 5;
BA_ "Version" SG_ 2244048130 ESC_FCA_ActvSta "19.11.02";
BA_ "Description" SG_ 2244048130 ESC_DBS_ActvSta "This signal specifies the status of control for DBS flag.

(DBS Á¦¾î ¿äÃ»¿¡ ´ëÇÑ Á¦µ¿ Á¦¾î±â ¼öÇà¿©ºÎ È®ÀÎ À§ÇÑ Á¤º¸ ½ÅÈ£)";
BA_ "UserSigValidity" SG_ 2244048130 ESC_DBS_ActvSta 3;
BA_ "RoutingFactor" SG_ 2244048130 ESC_DBS_ActvSta 5;
BA_ "Version" SG_ 2244048130 ESC_DBS_ActvSta "19.11.02";
BA_ "Description" SG_ 2244048130 SCC_TqReq "When it is set, the signal indicates that ESC requests engine torque control for SCC. When the signal is set, EMS should not conduct fuel-cut off control unless it is required to prevent the damage of the engine and the related components.";
BA_ "UserSigValidity" SG_ 2244048130 SCC_TqReq 3;
BA_ "RoutingFactor" SG_ 2244048130 SCC_TqReq 5;
BA_ "Version" SG_ 2244048130 SCC_TqReq "17.12.00";
BA_ "Description" SG_ 2244048130 ESC_HDP_EgSta "This signal is the information which of the HDP controllers (Main/Sub) the IEB (ESC)/RCU is engaged.";
BA_ "UserSigValidity" SG_ 2244048130 ESC_HDP_EgSta 0;
BA_ "RoutingFactor" SG_ 2244048130 ESC_HDP_EgSta 5;
BA_ "Version" SG_ 2244048130 ESC_HDP_EgSta "22.05.03";
BA_ "Description" SG_ 2244048130 ESC_HDP_EnblReq "This signal is a fault state of the IEB (ESC) for the HDP function.";
BA_ "UserSigValidity" SG_ 2244048130 ESC_HDP_EnblReq 3;
BA_ "RoutingFactor" SG_ 2244048130 ESC_HDP_EnblReq 5;
BA_ "Version" SG_ 2244048130 ESC_HDP_EnblReq "21.12.07";
BA_ "Description" SG_ 2244048130 CSC_Sta "This signal indicates whether the crosswind stability control(CSC) is active.";
BA_ "UserSigValidity" SG_ 2244048130 CSC_Sta 3;
BA_ "RoutingFactor" SG_ 2244048130 CSC_Sta 5;
BA_ "Version" SG_ 2244048130 CSC_Sta "22.01.06";
BA_ "Description" SG_ 2244048130 CSC_WrngSta "This signal is used to display warning message on cluster and hud about crosswind stability control(CSC) function.";
BA_ "UserSigValidity" SG_ 2244048130 CSC_WrngSta 3;
BA_ "RoutingFactor" SG_ 2244048130 CSC_WrngSta 5;
BA_ "Version" SG_ 2244048130 CSC_WrngSta "22.01.06";
BA_ "Description" SG_ 2244048130 ESC_BrkdFltStndstill "The signal indicates state when vehicle is braked, flatland and standstill";
BA_ "UserSigValidity" SG_ 2244048130 ESC_BrkdFltStndstill 3;
BA_ "RoutingFactor" SG_ 2244048130 ESC_BrkdFltStndstill 5;
BA_ "Version" SG_ 2244048130 ESC_BrkdFltStndstill "20.12.04";
BA_ "Description" SG_ 2244048130 SCC_ReqLimSta "Due to limitaion of the actuators the acceleration or deceleration request from SCC can not be processed or only partly. 



Examples:

1. SCC is requesting more acceleration than the engine can deliver.

2. SCC is requesting deceleration on a low ¥ì sur";
BA_ "UserSigValidity" SG_ 2244048130 SCC_ReqLimSta 3;
BA_ "RoutingFactor" SG_ 2244048130 SCC_ReqLimSta 5;
BA_ "Version" SG_ 2244048130 SCC_ReqLimSta "17.12.00";
BA_ "Description" SG_ 2244048130 ESC_StdStillVal "If an ESC uses active wheel speed sensors, wheel speeds down to 0 Km/h can be measured. And at 0 Km/h a StandStill flag is set in the ESC. This signal is used in the offset determination of the yaw rate and shall indicate that the vehicle has come to a c";
BA_ "UserSigValidity" SG_ 2244048130 ESC_StdStillVal 3;
BA_ "RoutingFactor" SG_ 2244048130 ESC_StdStillVal 5;
BA_ "Version" SG_ 2244048130 ESC_StdStillVal "17.12.00";
BA_ "Description" SG_ 2189467649 WHL_Crc1Val "The data area for CRC calculation is based on the data length (DLC) of the message DB.

The CRC shall be calculated over the entire data block (excluding the CRC bytes) including the user data, alive counter and Data ID



- CRC Polynomial (0x1021) , Ini";
BA_ "GenSigStartValue" SG_ 2189467649 WHL_Crc1Val 65535;
BA_ "UserSigValidity" SG_ 2189467649 WHL_Crc1Val 3;
BA_ "RoutingFactor" SG_ 2189467649 WHL_Crc1Val 5;
BA_ "Version" SG_ 2189467649 WHL_Crc1Val "21.09.03";
BA_ "Description" SG_ 2189467649 WHL_AlvCnt1Val "For the first transmission request for a data element the counter shall be initialized with 0 and shall be incremented by 1 for every subsequent send request. 

When the counter reaches the maximum value(0xFF), then it shall restart with 0 for the next s";
BA_ "UserSigValidity" SG_ 2189467649 WHL_AlvCnt1Val 3;
BA_ "RoutingFactor" SG_ 2189467649 WHL_AlvCnt1Val 5;
BA_ "Version" SG_ 2189467649 WHL_AlvCnt1Val "21.09.03";
BA_ "Description" SG_ 2189467649 WHL_PlsFLVal "This signal indicates accumulated pulse counter of ABS^ESC wheel speed sensor (FL^FR^RL^RR)

Receiver unit uses this signal for calculation of vehicle movement distance.

Requested resolution of this signal is 0.5 pulses and refer to below (wheel sensor ";
BA_ "UserSigValidity" SG_ 2189467649 WHL_PlsFLVal 3;
BA_ "RoutingFactor" SG_ 2189467649 WHL_PlsFLVal 5;
BA_ "Version" SG_ 2189467649 WHL_PlsFLVal "17.12.00";
BA_ "Description" SG_ 2189467649 WHL_PlsFRVal "This signal indicates accumulated pulse counter of ABS^ESC wheel speed sensor (FL^FR^RL^RR)

Receiver unit uses this signal for calculation of vehicle movement distance.

Requested resolution of this signal is 0.5 pulses and refer to below (wheel sensor ";
BA_ "UserSigValidity" SG_ 2189467649 WHL_PlsFRVal 3;
BA_ "RoutingFactor" SG_ 2189467649 WHL_PlsFRVal 5;
BA_ "Version" SG_ 2189467649 WHL_PlsFRVal "17.12.00";
BA_ "Description" SG_ 2189467649 WHL_PlsRLVal "This signal indicates accumulated pulse counter of ABS^ESC wheel speed sensor (FL^FR^RL^RR)

Receiver unit uses this signal for calculation of vehicle movement distance.

Requested resolution of this signal is 0.5 pulses and refer to below (wheel sensor ";
BA_ "UserSigValidity" SG_ 2189467649 WHL_PlsRLVal 3;
BA_ "RoutingFactor" SG_ 2189467649 WHL_PlsRLVal 5;
BA_ "Version" SG_ 2189467649 WHL_PlsRLVal "17.12.00";
BA_ "Description" SG_ 2189467649 WHL_PlsRRVal "This signal indicates accumulated pulse counter of ABS^ESC wheel speed sensor (FL^FR^RL^RR)

Receiver unit uses this signal for calculation of vehicle movement distance.

Requested resolution of this signal is 0.5 pulses and refer to below (wheel sensor ";
BA_ "UserSigValidity" SG_ 2189467649 WHL_PlsRRVal 3;
BA_ "RoutingFactor" SG_ 2189467649 WHL_PlsRRVal 5;
BA_ "Version" SG_ 2189467649 WHL_PlsRRVal "17.12.00";
BA_ "Description" SG_ 2189467649 WHL_DirFLVal "This signal is used to check the moving direction of WHL_PUL_FL signal.";
BA_ "UserSigValidity" SG_ 2189467649 WHL_DirFLVal 3;
BA_ "RoutingFactor" SG_ 2189467649 WHL_DirFLVal 5;
BA_ "Version" SG_ 2189467649 WHL_DirFLVal "17.12.00";
BA_ "Description" SG_ 2189467649 WHL_DirFRVal "This signal is used to check the moving direction of WHL_PUL_FR signal.";
BA_ "UserSigValidity" SG_ 2189467649 WHL_DirFRVal 3;
BA_ "RoutingFactor" SG_ 2189467649 WHL_DirFRVal 5;
BA_ "Version" SG_ 2189467649 WHL_DirFRVal "17.12.00";
BA_ "Description" SG_ 2189467649 WHL_DirRLVal "This signal is used to check the moving direction of WHL_PUL_RL signal.";
BA_ "UserSigValidity" SG_ 2189467649 WHL_DirRLVal 3;
BA_ "RoutingFactor" SG_ 2189467649 WHL_DirRLVal 5;
BA_ "Version" SG_ 2189467649 WHL_DirRLVal "17.12.00";
BA_ "Description" SG_ 2189467649 WHL_DirRRVal "This signal is used to check the moving direction of WHL_PUL_RR signal.";
BA_ "UserSigValidity" SG_ 2189467649 WHL_DirRRVal 3;
BA_ "RoutingFactor" SG_ 2189467649 WHL_DirRRVal 5;
BA_ "Version" SG_ 2189467649 WHL_DirRRVal "17.12.00";
BA_ "Description" SG_ 2164277252 TCU_NetrlCtrlSta "This signal indicates the status of Neutral Control.";
BA_ "UserSigValidity" SG_ 2164277252 TCU_NetrlCtrlSta 3;
BA_ "RoutingFactor" SG_ 2164277252 TCU_NetrlCtrlSta 5;
BA_ "Version" SG_ 2164277252 TCU_NetrlCtrlSta "17.11.00";
BA_ "Description" SG_ 2164277252 TCU_ShftPtrnSta "It is an ID of current shift pattern which is being used by TCU.

The ID is assigned for each TCU.";
BA_ "UserSigValidity" SG_ 2164277252 TCU_ShftPtrnSta 3;
BA_ "RoutingFactor" SG_ 2164277252 TCU_ShftPtrnSta 5;
BA_ "Version" SG_ 2164277252 TCU_ShftPtrnSta "17.11.00";
BA_ "Description" SG_ 2164277252 TCU_EPBReq "This is EPB Request signal for prevent P-D Shift shock on the hill";
BA_ "UserSigValidity" SG_ 2164277252 TCU_EPBReq 3;
BA_ "RoutingFactor" SG_ 2164277252 TCU_EPBReq 5;
BA_ "Version" SG_ 2164277252 TCU_EPBReq "19.03.09";
BA_ "Description" SG_ 2164277252 IMT_EOLstate "If this signal is set, Cluster should display gear info using alphabet 'E' regardless the signal 'TCU_GearSlctDis'";
BA_ "UserSigValidity" SG_ 2164277252 IMT_EOLstate 3;
BA_ "RoutingFactor" SG_ 2164277252 IMT_EOLstate 5;
BA_ "Version" SG_ 2164277252 IMT_EOLstate "19.02.06";
BA_ "Description" SG_ 2164277252 IMT_DisCmd "This signal is used for cluster to change gear display type. 

Always Display / Not Display / Blinking";
BA_ "UserSigValidity" SG_ 2164277252 IMT_DisCmd 3;
BA_ "RoutingFactor" SG_ 2164277252 IMT_DisCmd 5;
BA_ "Version" SG_ 2164277252 IMT_DisCmd "19.02.06";
BA_ "Description" SG_ 2164277252 IMT_CltchPdlPos "Clutch Position Sensor value for 3 pedal IMT system.

This value is not supported by 2 pedal IMT system.



0% means pedal off 

99.21875% (0xFE) means pedal fully pressed

99.609375 (0xFF) means  error";
BA_ "UserSigValidity" SG_ 2164277252 IMT_CltchPdlPos 3;
BA_ "RoutingFactor" SG_ 2164277252 IMT_CltchPdlPos 5;
BA_ "Version" SG_ 2164277252 IMT_CltchPdlPos "19.02.06";
BA_ "Description" SG_ 2164277252 DCT_RegenInhbt "The regen inhibit request from TCU.

ECU is received regen inhibit flag from TCU, then ECU is limited the regen state.";
BA_ "UserSigValidity" SG_ 2164277252 DCT_RegenInhbt 3;
BA_ "RoutingFactor" SG_ 2164277252 DCT_RegenInhbt 5;
BA_ "Version" SG_ 2164277252 DCT_RegenInhbt "18.08.02";
BA_ "Description" SG_ 2164277252 DCT_EngIdleReq "Engine Idle Request from TCU";
BA_ "UserSigValidity" SG_ 2164277252 DCT_EngIdleReq 3;
BA_ "RoutingFactor" SG_ 2164277252 DCT_EngIdleReq 5;
BA_ "Version" SG_ 2164277252 DCT_EngIdleReq "18.08.02";
BA_ "Description" SG_ 2164277252 DCT_CltchState "Status of DCT clutches. This signal gives information about the frictional connection between the engine and the drive train.";
BA_ "UserSigValidity" SG_ 2164277252 DCT_CltchState 3;
BA_ "RoutingFactor" SG_ 2164277252 DCT_CltchState 5;
BA_ "Version" SG_ 2164277252 DCT_CltchState "18.08.02";
BA_ "Description" SG_ 2164277252 DCT_FuelCutReq "Fuel Cut request bit signal to let EMS perform ¡®Fuel Cut torque intervention¡¯ during shift";
BA_ "UserSigValidity" SG_ 2164277252 DCT_FuelCutReq 3;
BA_ "RoutingFactor" SG_ 2164277252 DCT_FuelCutReq 5;
BA_ "Version" SG_ 2164277252 DCT_FuelCutReq "18.08.02";
BA_ "Description" SG_ 2164277252 DCT_TqIncReq "An Identifier of a DCT TCU controller for increasing torque intervention. 

This bit is to prevent the triggering of unintended DCT TCU interventions.



In the case of a torque increase, following conditions must be fulfilled.

DCT_TqIncReq = 1 and TCU_";
BA_ "UserSigValidity" SG_ 2164277252 DCT_TqIncReq 3;
BA_ "RoutingFactor" SG_ 2164277252 DCT_TqIncReq 5;
BA_ "Version" SG_ 2164277252 DCT_TqIncReq "18.08.02";
BA_ "Description" SG_ 2164277252 DCT_CrpTqReq "During creep mode (engine in idle, brake pedal not pressed, gear engaged) clutch torque will be applied. In order to support the engine¡¯s idle controller DCT_CrpTqReq gives the information how much clutch torque will be applied within the next 50 ms.";
BA_ "GenSigStartValue" SG_ 2164277252 DCT_CrpTqReq 512;
BA_ "UserSigValidity" SG_ 2164277252 DCT_CrpTqReq 3;
BA_ "RoutingFactor" SG_ 2164277252 DCT_CrpTqReq 5;
BA_ "Version" SG_ 2164277252 DCT_CrpTqReq "18.08.02";
BA_ "Description" SG_ 2164277252 DCT_ShftTqReq "To ensure a torque increasing during gear shift within short time, ECU needs to build up a torque reserve determined by the pre-control torque. 

Open throttle valve (more air) and automatic ignition angle reduction (within limited range based on engine ";
BA_ "UserSigValidity" SG_ 2164277252 DCT_ShftTqReq 3;
BA_ "RoutingFactor" SG_ 2164277252 DCT_ShftTqReq 5;
BA_ "Version" SG_ 2164277252 DCT_ShftTqReq "20.03.05";
BA_ "Description" SG_ 2164277252 TCU_VgisInhbtReq "TCU requests ECU to inhibit the VGIS fuction from changing its status.";
BA_ "UserSigValidity" SG_ 2164277252 TCU_VgisInhbtReq 3;
BA_ "RoutingFactor" SG_ 2164277252 TCU_VgisInhbtReq 5;
BA_ "Version" SG_ 2164277252 TCU_VgisInhbtReq "17.11.00";
BA_ "Description" SG_ 2164277252 TCU_EngTqIncReqVal "The TCU requests the engine torque increase via this signal to the EMS.



If MSB is 1, this signal is - value.

else, this signal is +value.

0~10bit is used for absolute value.";
BA_ "UserSigValidity" SG_ 2164277252 TCU_EngTqIncReqVal 3;
BA_ "RoutingFactor" SG_ 2164277252 TCU_EngTqIncReqVal 5;
BA_ "Version" SG_ 2164277252 TCU_EngTqIncReqVal "20.03.05";
BA_ "Description" SG_ 2189467650 WHL_SpdFLVal "This signal provides the wheel velocity of each wheel and have 14 bits length and a resolution of 0.03125 km^h.(This resolution is higher than that of signal in TCS5).

In case of failure of one wheel speed sensor, the value 3FFFH is used as error identi";
BA_ "UserSigValidity" SG_ 2189467650 WHL_SpdFLVal 3;
BA_ "RoutingFactor" SG_ 2189467650 WHL_SpdFLVal 5;
BA_ "Version" SG_ 2189467650 WHL_SpdFLVal "17.12.00";
BA_ "Description" SG_ 2189467650 WHL_SpdFRVal "This signal provides the wheel velocity of each wheel and have 14 bits length and a resolution of 0.03125 km^h.(This resolution is higher than that of signal in TCS5).

In case of failure of one wheel speed sensor, the value 3FFFH is used as error identi";
BA_ "UserSigValidity" SG_ 2189467650 WHL_SpdFRVal 3;
BA_ "RoutingFactor" SG_ 2189467650 WHL_SpdFRVal 5;
BA_ "Version" SG_ 2189467650 WHL_SpdFRVal "17.12.00";
BA_ "Description" SG_ 2189467650 WHL_SpdRLVal "This signal provides the wheel velocity of each wheel and have 14 bits length and a resolution of 0.03125 km^h.(This resolution is higher than that of signal in TCS5).

In case of failure of one wheel speed sensor, the value 3FFFH is used as error identi";
BA_ "UserSigValidity" SG_ 2189467650 WHL_SpdRLVal 3;
BA_ "RoutingFactor" SG_ 2189467650 WHL_SpdRLVal 5;
BA_ "Version" SG_ 2189467650 WHL_SpdRLVal "17.12.00";
BA_ "Description" SG_ 2189467650 WHL_SpdRRVal "This signal provides the wheel velocity of each wheel and have 14 bits length and a resolution of 0.03125 km^h.(This resolution is higher than that of signal in TCS5).

In case of failure of one wheel speed sensor, the value 3FFFH is used as error identi";
BA_ "UserSigValidity" SG_ 2189467650 WHL_SpdRRVal 3;
BA_ "RoutingFactor" SG_ 2189467650 WHL_SpdRRVal 5;
BA_ "Version" SG_ 2189467650 WHL_SpdRRVal "17.12.00";
BA_ "Description" SG_ 2189467651 WHL_SpdCalParmtr "ÀÌ ½ÅÈ£´Â ABS/ESC ³»ºÎ¿¡¼­ ÈÙ ÆÞ½º °ªÀ» ÈÙ ½ºÇÇµå·Î º¯È¯ÇÏ´Âµ¥ »ç¿ëÇÏ´Â ESC ³»ºÎ ÆÄ¶ó¹ÌÅÍ¸¦ ÀÇ¹ÌÇÔ.

º» ½ÅÈ£´Â ½ÇÁ¦ Å¸ÀÌ¾î µ¿¹Ý°æ°ú ´Ù¸¦ ¼ö ÀÖÀ¸¸ç, ABS/ESCÀÇ Á¦¾î¸¦ À§ÇÑ Â÷¼Ó ÃßÁ¤À» À§ÇØ °³¹ß °úÁ¤ Áß¿¡ ÀÓÀÇ·Î º¯°æÀÌ °¡´ÉÇÑ Calibration Value ÀÓ.

½ÅÈ£ »ç¿";
BA_ "UserSigValidity" SG_ 2189467651 WHL_SpdCalParmtr 3;
BA_ "RoutingFactor" SG_ 2189467651 WHL_SpdCalParmtr 5;
BA_ "Version" SG_ 2189467651 WHL_SpdCalParmtr "19.05.02";
BA_ "Description" SG_ 2164277249 TCU_Crc1Val "The data area for CRC calculation is based on the data length (DLC) of the message DB.

The CRC shall be calculated over the entire data block (excluding the CRC bytes) including the user data, alive counter and Data ID

 

- CRC Polynomial (0x1021) , In";
BA_ "GenSigStartValue" SG_ 2164277249 TCU_Crc1Val 65535;
BA_ "UserSigValidity" SG_ 2164277249 TCU_Crc1Val 3;
BA_ "RoutingFactor" SG_ 2164277249 TCU_Crc1Val 5;
BA_ "Version" SG_ 2164277249 TCU_Crc1Val "18.11.08";
BA_ "Description" SG_ 2164277249 TCU_AlvCnt1Val "For the first transmission request for a data element the counter shall be initialized with 0 and shall be incremented by 1 for every subsequent send request. 

When the counter reaches the maximum value(0xFF), then it shall restart with 0 for the next s";
BA_ "UserSigValidity" SG_ 2164277249 TCU_AlvCnt1Val 3;
BA_ "RoutingFactor" SG_ 2164277249 TCU_AlvCnt1Val 5;
BA_ "Version" SG_ 2164277249 TCU_AlvCnt1Val "18.11.08";
BA_ "Description" SG_ 2164277249 TCU_GearSlctDis "Position (P, R, N..), which was identified by the gear selector.

In case the gear selector is in a intermediate position, the last clear recognized position is used.

There is no specific phase relationship between the output and any other signal.";
BA_ "GenSigStartValue" SG_ 2164277249 TCU_GearSlctDis 9;
BA_ "UserSigValidity" SG_ 2164277249 TCU_GearSlctDis 3;
BA_ "RoutingFactor" SG_ 2164277249 TCU_GearSlctDis 5;
BA_ "Version" SG_ 2164277249 TCU_GearSlctDis "17.11.00";
BA_ "Description" SG_ 2164277249 TCU_Typ "Information regarding the type of transmission - Step A/T or CVT or DCT / AMT / eClutch";
BA_ "UserSigValidity" SG_ 2164277249 TCU_Typ 3;
BA_ "RoutingFactor" SG_ 2164277249 TCU_Typ 5;
BA_ "Version" SG_ 2164277249 TCU_Typ "18.12.02";
BA_ "Description" SG_ 2164277249 TCU_TqRdctnVal "The TCU requests a torque reduction via this signal to the EMS. 



If MSB is 1, this signal is - value.

else, this signal is +value.

0~10bit is used for absolute value.";
BA_ "GenSigStartValue" SG_ 2164277249 TCU_TqRdctnVal 2047;
BA_ "UserSigValidity" SG_ 2164277249 TCU_TqRdctnVal 3;
BA_ "RoutingFactor" SG_ 2164277249 TCU_TqRdctnVal 5;
BA_ "Version" SG_ 2164277249 TCU_TqRdctnVal "20.03.05";
BA_ "Description" SG_ 2164277249 TCU_GearStepTyp "This signal indicates number of gear steps of step type automatic transmission(A/T) or Dual Clutch Transmission(DCT). A vehicle can have A/T or DCT variant according to its option, for example 4-speed A/T or 5-speed A/T can be equipped in the same kind o";
BA_ "UserSigValidity" SG_ 2164277249 TCU_GearStepTyp 3;
BA_ "RoutingFactor" SG_ 2164277249 TCU_GearStepTyp 5;
BA_ "Version" SG_ 2164277249 TCU_GearStepTyp "19.02.07";
BA_ "Description" SG_ 2164277249 TCU_GearShftSta "SWI_GS indicates whether a gear change is being executed in the gearbox.



Note : Gear change means a gear shift at D-range and Garage shift(PRND).";
BA_ "UserSigValidity" SG_ 2164277249 TCU_GearShftSta 3;
BA_ "RoutingFactor" SG_ 2164277249 TCU_GearShftSta 5;
BA_ "Version" SG_ 2164277249 TCU_GearShftSta "17.11.00";
BA_ "Description" SG_ 2164277249 TCU_TqCnvrtrSta "Status converter clutch



There is no specific phase relationship between the output and any other signal.";
BA_ "UserSigValidity" SG_ 2164277249 TCU_TqCnvrtrSta 3;
BA_ "RoutingFactor" SG_ 2164277249 TCU_TqCnvrtrSta 5;
BA_ "Version" SG_ 2164277249 TCU_TqCnvrtrSta "17.11.00";
BA_ "Description" SG_ 2164277251 TCU_EngRpmDis "Engine RPM from TCU (Only for the display on Cluster)";
BA_ "UserSigValidity" SG_ 2164277251 TCU_EngRpmDis 3;
BA_ "RoutingFactor" SG_ 2164277251 TCU_EngRpmDis 5;
BA_ "Version" SG_ 2164277251 TCU_EngRpmDis "17.11.00";
BA_ "Description" SG_ 2164277251 TCU_SlpVal "This signal is used to avoid busy shifting during uphill driving.

It is calculated using engine torque, turbine torque and gearbox torque so on.

It has some restrictions like the following sentences

- No slope calculation during shifting, braking, 1st";
BA_ "GenSigStartValue" SG_ 2164277251 TCU_SlpVal 32;
BA_ "UserSigValidity" SG_ 2164277251 TCU_SlpVal 3;
BA_ "RoutingFactor" SG_ 2164277251 TCU_SlpVal 5;
BA_ "Version" SG_ 2164277251 TCU_SlpVal "17.11.00";
BA_ "Description" SG_ 2164277251 TCU_EngSpdIncReq "This signal is a target engine speed requirement start flag signal by TCU, 

which is sent to ECU. It is synchronized to the signal engine speed increasing target speed value.";
BA_ "UserSigValidity" SG_ 2164277251 TCU_EngSpdIncReq 3;
BA_ "RoutingFactor" SG_ 2164277251 TCU_EngSpdIncReq 5;
BA_ "Version" SG_ 2164277251 TCU_EngSpdIncReq "17.11.00";
BA_ "Description" SG_ 2164277251 TCU_ObdSta "The signal TCU_OBD is used to inform the OBD master (EMS-ECU) in case a OBD relevant fault is detected. According to the OBD regulations the TCU could request MIL on. If a freeze frame request by the TCU has not been acknowledged (OBD_FRF_ACK) within 2 s";
BA_ "UserSigValidity" SG_ 2164277251 TCU_ObdSta 3;
BA_ "RoutingFactor" SG_ 2164277251 TCU_ObdSta 5;
BA_ "Version" SG_ 2164277251 TCU_ObdSta "19.02.07";
BA_ "Description" SG_ 2164277251 TCU_SprtyIndxSta "Sporty index based on the driver's driving behaviour";
BA_ "UserSigValidity" SG_ 2164277251 TCU_SprtyIndxSta 3;
BA_ "RoutingFactor" SG_ 2164277251 TCU_SprtyIndxSta 5;
BA_ "Version" SG_ 2164277251 TCU_SprtyIndxSta "17.11.00";
BA_ "Description" SG_ 2164277251 TCU_DrvngModDis "Driving mode display by TCU";
BA_ "UserSigValidity" SG_ 2164277251 TCU_DrvngModDis 3;
BA_ "RoutingFactor" SG_ 2164277251 TCU_DrvngModDis 5;
BA_ "Version" SG_ 2164277251 TCU_DrvngModDis "17.11.00";
BA_ "Description" SG_ 2164277251 TCU_DrvngModReq "Driving mode request with Normal, Eco, Eco+, Sport, Sport+

and Snow only TCU automode is on, otherwise, inactive";
BA_ "UserSigValidity" SG_ 2164277251 TCU_DrvngModReq 3;
BA_ "RoutingFactor" SG_ 2164277251 TCU_DrvngModReq 5;
BA_ "Version" SG_ 2164277251 TCU_DrvngModReq "17.11.00";
BA_ "Description" SG_ 2164277251 TCU_SmrtShftSta "Information of SmartShift";
BA_ "UserSigValidity" SG_ 2164277251 TCU_SmrtShftSta 3;
BA_ "RoutingFactor" SG_ 2164277251 TCU_SmrtShftSta 5;
BA_ "Version" SG_ 2164277251 TCU_SmrtShftSta "17.11.00";
BA_ "Description" SG_ 2164277251 TCU_LupTrgtEngSpdVal "This signal is a target engine speed requested by TCU, which is sent to ECU. 

It is intended for OFF-SLIP to be more successful in triggering fuel cut-off under more various driving conditions.";
BA_ "GenSigStartValue" SG_ 2164277251 TCU_LupTrgtEngSpdVal 255;
BA_ "UserSigValidity" SG_ 2164277251 TCU_LupTrgtEngSpdVal 3;
BA_ "RoutingFactor" SG_ 2164277251 TCU_LupTrgtEngSpdVal 5;
BA_ "Version" SG_ 2164277251 TCU_LupTrgtEngSpdVal "17.11.00";
BA_ "Description" SG_ 2164277251 TCU_FrtStcShftSta "Status of fisrt static shift";
BA_ "UserSigValidity" SG_ 2164277251 TCU_FrtStcShftSta 3;
BA_ "RoutingFactor" SG_ 2164277251 TCU_FrtStcShftSta 5;
BA_ "Version" SG_ 2164277251 TCU_FrtStcShftSta "17.11.00";
BA_ "Description" SG_ 2164277251 TCU_IsgInhbtReq "TCU requests ECU to inhibit the ISG function when ISG start condition of AT is not met (oil temp is too low , AT ISG system malfunction, etc ¡¦ )";
BA_ "UserSigValidity" SG_ 2164277251 TCU_IsgInhbtReq 3;
BA_ "RoutingFactor" SG_ 2164277251 TCU_IsgInhbtReq 5;
BA_ "Version" SG_ 2164277251 TCU_IsgInhbtReq "17.11.00";
BA_ "Description" SG_ 2164277251 TCU_CdaInhbtReq "TCU requests ECU to prohibit the CDA transition during gear shifting or lock-up clutch operation in the automatic transmission in order to prevent a shock on the vehicle. Without gear shifting and lock-up clutch operation, CDA transition can be performed";
BA_ "UserSigValidity" SG_ 2164277251 TCU_CdaInhbtReq 3;
BA_ "RoutingFactor" SG_ 2164277251 TCU_CdaInhbtReq 5;
BA_ "Version" SG_ 2164277251 TCU_CdaInhbtReq "17.11.00";
BA_ "Description" SG_ 2164277251 TCU_BrkOnReq "The TCU request the ESC to activate the Brake.

The ESC holds the Brake ON during the TCU¡¯s Brake ON Request.";
BA_ "UserSigValidity" SG_ 2164277251 TCU_BrkOnReq 3;
BA_ "RoutingFactor" SG_ 2164277251 TCU_BrkOnReq 5;
BA_ "Version" SG_ 2164277251 TCU_BrkOnReq "17.11.00";
BA_ "Description" SG_ 2164277251 TCU_TqGrdntLimVal "TCU requests EMS to perform the engine torque gradient limitation control with a rate of Nm per second(Nm/sec).



Downshift : The engine torque gradient limitation for downshift will be a function of pedal and shift-time. 

Upshift : The engine torque g";
BA_ "UserSigValidity" SG_ 2164277251 TCU_TqGrdntLimVal 3;
BA_ "RoutingFactor" SG_ 2164277251 TCU_TqGrdntLimVal 5;
BA_ "Version" SG_ 2164277251 TCU_TqGrdntLimVal "17.11.00";
BA_ "Description" SG_ 2164277250 TCU_CurrGearSta "CUR_GR indicates the gear speed which is currently engaged in the gearbox.";
BA_ "UserSigValidity" SG_ 2164277250 TCU_CurrGearSta 3;
BA_ "RoutingFactor" SG_ 2164277250 TCU_CurrGearSta 5;
BA_ "Version" SG_ 2164277250 TCU_CurrGearSta "17.11.00";
BA_ "Description" SG_ 2164277250 TCH_EngTrgtGearSta "TCH_EngTrgtGearSta informs about target gear of SS timing 

(For indicating Paddle shift or Manual mode on cluster)";
BA_ "UserSigValidity" SG_ 2164277250 TCH_EngTrgtGearSta 3;
BA_ "RoutingFactor" SG_ 2164277250 TCH_EngTrgtGearSta 5;
BA_ "Version" SG_ 2164277250 TCH_EngTrgtGearSta "17.11.00";
BA_ "Description" SG_ 2164277250 TCU_EngTqLimVal "The TCU requests a engine torque limit(ETL) from the EMS. 

There is no time limitation of the intervention.

TCU requests engine torque limit below the TCU requesting torque.

The engine torque request signal means the absolute torque limitation.

TCU s";
BA_ "GenSigStartValue" SG_ 2164277250 TCU_EngTqLimVal 2047;
BA_ "UserSigValidity" SG_ 2164277250 TCU_EngTqLimVal 3;
BA_ "RoutingFactor" SG_ 2164277250 TCU_EngTqLimVal 5;
BA_ "Version" SG_ 2164277250 TCU_EngTqLimVal "20.03.05";
BA_ "Description" SG_ 2164277250 TCU_CluTrgtGearConfg "This signal indicates the signal source configuration of target gear for CLU";
BA_ "UserSigValidity" SG_ 2164277250 TCU_CluTrgtGearConfg 3;
BA_ "RoutingFactor" SG_ 2164277250 TCU_CluTrgtGearConfg 5;
BA_ "Version" SG_ 2164277250 TCU_CluTrgtGearConfg "18.08.01";
BA_ "Description" SG_ 2164277250 TCU_VehSpdKphVal "The vehicle speed calculated by TCU is transferred. 

If a vehicle has no vehicle speed sensor, no wheel speed sensor and no ABS(TCS/ESC) then it is impossible for an EMS to calculate veficle speed. In this case a TCU should calculate vehicle speed and s";
BA_ "UserSigValidity" SG_ 2164277250 TCU_VehSpdKphVal 3;
BA_ "RoutingFactor" SG_ 2164277250 TCU_VehSpdKphVal 5;
BA_ "Version" SG_ 2164277250 TCU_VehSpdKphVal "17.11.00";
BA_ "Description" SG_ 2164277250 TCU_TrgtGearSta "CF_Tcu_TarGr informs about the speed, which is currently engaged in the gearbox, or, in case of a gear change (SWI_GS), which speed is reached.



Note: Gear changes covering more than one speed are also possible.

In the P and N positions, the frictiona";
BA_ "UserSigValidity" SG_ 2164277250 TCU_TrgtGearSta 3;
BA_ "RoutingFactor" SG_ 2164277250 TCU_TrgtGearSta 5;
BA_ "Version" SG_ 2164277250 TCU_TrgtGearSta "17.11.00";
BA_ "Description" SG_ 2164277250 TCU_DcmlVehSpdKphVal "The signal VS_TCU_DECIAMAL means the value which is below decimal point of the vehicle speed.

For instance, if a vehicle speed is 13.75Km/h, VS_TCU means 13Km/h and VS_TCU_DECIMAL means 0.75Km/h.



Example)   VS_TCU = 13,  VS_TCU_DECIAMAL  = 96

Vehicl";
BA_ "UserSigValidity" SG_ 2164277250 TCU_DcmlVehSpdKphVal 3;
BA_ "RoutingFactor" SG_ 2164277250 TCU_DcmlVehSpdKphVal 5;
BA_ "Version" SG_ 2164277250 TCU_DcmlVehSpdKphVal "17.11.00";
BA_ "Description" SG_ 2164277250 TCU_SprkRtrdReq "The TCU requests a spark angle retard via the signal SPK_RTD_TCU to the EMS for torque reduction during the gear engage condition.



(PH) = ((HEX) - 3FH) * 0.375 (Advance) (PH) = (3FH - (HEX)) * (-0.375) (Retard)

-15¢ª  ... 0¢ª= 17H .. 3FH (Retard)

0.";
BA_ "GenSigStartValue" SG_ 2164277250 TCU_SprkRtrdReq 255;
BA_ "UserSigValidity" SG_ 2164277250 TCU_SprkRtrdReq 3;
BA_ "RoutingFactor" SG_ 2164277250 TCU_SprkRtrdReq 5;
BA_ "Version" SG_ 2164277250 TCU_SprkRtrdReq "17.11.00";
BA_ "Description" SG_ 2164277250 TCU_EngRpmDisSta "Flag for Engine RPM(from TCU) Display on Cluster, Only when this flag is set to 1, Cluster shall display the Engine RPM from TCU";
BA_ "UserSigValidity" SG_ 2164277250 TCU_EngRpmDisSta 3;
BA_ "RoutingFactor" SG_ 2164277250 TCU_EngRpmDisSta 5;
BA_ "Version" SG_ 2164277250 TCU_EngRpmDisSta "17.11.00";
BA_ "Description" SG_ 2164277250 TCU_GearLmpBlnkngReq "Cluster controls blinking of Gear lamp receiving the request signal from TCU.";
BA_ "UserSigValidity" SG_ 2164277250 TCU_GearLmpBlnkngReq 3;
BA_ "RoutingFactor" SG_ 2164277250 TCU_GearLmpBlnkngReq 5;
BA_ "Version" SG_ 2164277250 TCU_GearLmpBlnkngReq "17.11.00";
BA_ "Description" SG_ 2164277250 TCU_FuelCutInhbtReq "During coast down shifting, EMS may cut off fuel injection and as a result, a driver can feel bad shift feeling. In this case, to enhance shift quality, TCU needs inhibition of fuel cut off control.

This signal indicates inhibition of engine fuel cut of";
BA_ "UserSigValidity" SG_ 2164277250 TCU_FuelCutInhbtReq 3;
BA_ "RoutingFactor" SG_ 2164277250 TCU_FuelCutInhbtReq 5;
BA_ "Version" SG_ 2164277250 TCU_FuelCutInhbtReq "17.11.00";
BA_ "Description" SG_ 2164277250 TCU_IdleUpReq "When ATF(Automatic Transmission Fluid) rises in high temperauture, the TCU requests engine idle RPM up via the signal IDLE_UP_TCU to the EMS for reduction of gearshift time form Neutral to Reverse.



THIS SIGNAL IS FOR ¡°LAMBDA ENGINE¡± SYSTEM ONLY.";
BA_ "UserSigValidity" SG_ 2164277250 TCU_IdleUpReq 3;
BA_ "RoutingFactor" SG_ 2164277250 TCU_IdleUpReq 5;
BA_ "Version" SG_ 2164277250 TCU_IdleUpReq "17.11.00";
BA_ "Description" SG_ 2164277250 TCU_CluTrgtGearSta "TCH_CluTrgtGearSta informs about target gear of SS timing 

(For indicating Paddle shift or Manual mode on cluster)";
BA_ "UserSigValidity" SG_ 2164277250 TCU_CluTrgtGearSta 3;
BA_ "RoutingFactor" SG_ 2164277250 TCU_CluTrgtGearSta 5;
BA_ "Version" SG_ 2164277250 TCU_CluTrgtGearSta "17.11.00";
BA_ "Description" SG_ 2239848450 FCA_RelVel "This signal indicates the relative velocity between the host vehicle and a forward vehicle.







(PH) = ((HEX)-0FFH)*0.1 [m/s/digit]



       = (HEX)*0.1 [m/s/digit] - 25.5 [m/s]



CAN Message Physical range : Max. Relative velocity : 0x1FE(25.5m/s),";
BA_ "UserSigValidity" SG_ 2239848450 FCA_RelVel 3;
BA_ "RoutingFactor" SG_ 2239848450 FCA_RelVel 5;
BA_ "Version" SG_ 2239848450 FCA_RelVel "20.02.00";
BA_ "Description" SG_ 2239848450 Nmode_FCAOff_Sta "This signal describes status of FCA off when Nmode on";
BA_ "UserSigValidity" SG_ 2239848450 Nmode_FCAOff_Sta 3;
BA_ "RoutingFactor" SG_ 2239848450 Nmode_FCAOff_Sta 5;
BA_ "Version" SG_ 2239848450 Nmode_FCAOff_Sta "17.12.00";
BA_ "Description" SG_ 2239848450 FCA_Jnctn_OnOffEquipSta "This signal describes the FCA-JC Function.

- ½Ã½ºÅÛ ÀåÂø ¿©ºÎ ¹× ½Ã½ºÅÛ on/off Á¤º¸";
BA_ "UserSigValidity" SG_ 2239848450 FCA_Jnctn_OnOffEquipSta 3;
BA_ "RoutingFactor" SG_ 2239848450 FCA_Jnctn_OnOffEquipSta 5;
BA_ "Version" SG_ 2239848450 FCA_Jnctn_OnOffEquipSta "17.11.00";
BA_ "Description" SG_ 2239848450 HDP_EMOpSta "EM On (Not Active/Active), Off status";
BA_ "UserSigValidity" SG_ 2239848450 HDP_EMOpSta 3;
BA_ "RoutingFactor" SG_ 2239848450 HDP_EMOpSta 5;
BA_ "Version" SG_ 2239848450 HDP_EMOpSta "20.06.05";
BA_ "Description" SG_ 2239848450 FCA_WrngTrgtDis "Request CLU to activate the corresponding warning device(s) according to the type of FCA warning target.

- FCA °æ°í ´ë»ó Á¾·ùº° Ç¥½Ã Á¤º¸½ÅÈ£";
BA_ "UserSigValidity" SG_ 2239848450 FCA_WrngTrgtDis 3;
BA_ "RoutingFactor" SG_ 2239848450 FCA_WrngTrgtDis 5;
BA_ "Version" SG_ 2239848450 FCA_WrngTrgtDis "19.03.06";
BA_ "Description" SG_ 2239848450 ADAS_DRV_FCA_Plus_Sta "Àü¹æÄ«¸Þ¶ó, Àü¹æ·¹ÀÌ´õ ¹× ÀüÃø¹æ ·¹ÀÌ´õ/ÈÄÃø¹æ ·¹ÀÌÅÍ Ç»Àü Æ®·¢À» ÅëÇØ FCA-Car Å¸°Ù ¹× ÀÚÂ÷ ÁÂÃø/¿ìÃø ¿µ¿ª È¸ÇÇ ºÒ°¡´É ¿©ºÎ¸¦ ÆÇ´ÜÇÏ¿© FCA-Car/Ped/Cyc+ Flag¸¦ Ãâ·ÂÇÔ";
BA_ "UserSigValidity" SG_ 2239848450 ADAS_DRV_FCA_Plus_Sta 3;
BA_ "RoutingFactor" SG_ 2239848450 ADAS_DRV_FCA_Plus_Sta 5;
BA_ "Version" SG_ 2239848450 ADAS_DRV_FCA_Plus_Sta "18.08.06";
BA_ "Description" SG_ 2239848450 ADAS_TrlOffStaDisp "This signal describes ADAS system automatically off by trailer connected.";
BA_ "UserSigValidity" SG_ 2239848450 ADAS_TrlOffStaDisp 3;
BA_ "RoutingFactor" SG_ 2239848450 ADAS_TrlOffStaDisp 5;
BA_ "Version" SG_ 2239848450 ADAS_TrlOffStaDisp "20.12.01";
BA_ "Description" SG_ 2239848450 FCA_FrOnOffEquipSta "This signal describes the FCA-Car/Ped/Cyc/JT state.

- Front Camera Only: FCA-Car/Ped/Cyc

- Sensor Fusion: FCA-Car/Ped/Cyc/JT



 FCA-Car/Ped/Cyc/JT Àû¿ë ¿©ºÎ ¹× On/Off Á¤º¸

- Àü¹æ Ä«¸Þ¶ó ´Üµ¶: FCA-Car/Ped/Cyc

- ¼¾¼­Ç»Àü: FCA-Car/Ped/Cyc/JT";
BA_ "UserSigValidity" SG_ 2239848450 FCA_FrOnOffEquipSta 3;
BA_ "RoutingFactor" SG_ 2239848450 FCA_FrOnOffEquipSta 5;
BA_ "Version" SG_ 2239848450 FCA_FrOnOffEquipSta "20.12.03";
BA_ "Description" SG_ 2239848450 FCA_JC_OnOffEquipSta "This signal describes the FCA-JC state.

 - FCA-JC Àû¿ë ¿©ºÎ ¹× On/Off Á¤º¸";
BA_ "UserSigValidity" SG_ 2239848450 FCA_JC_OnOffEquipSta 3;
BA_ "RoutingFactor" SG_ 2239848450 FCA_JC_OnOffEquipSta 5;
BA_ "Version" SG_ 2239848450 FCA_JC_OnOffEquipSta "20.12.03";
BA_ "Description" SG_ 2239848450 FCA_FrSdOnOffEquipSta "This signal describes the FCA-LO/LS, w/ ESA state.

 - FCA-LO/LS, w/ ESA Àû¿ë ¿©ºÎ ¹×  On/Off Á¤º¸";
BA_ "UserSigValidity" SG_ 2239848450 FCA_FrSdOnOffEquipSta 3;
BA_ "RoutingFactor" SG_ 2239848450 FCA_FrSdOnOffEquipSta 5;
BA_ "Version" SG_ 2239848450 FCA_FrSdOnOffEquipSta "20.12.03";
BA_ "Description" SG_ 2239848450 EM_WrngLvlSta "Request CLU to activate the corresponding warning device(s) according to the EM warning level. (Braking / Steering act)

- EM ±â´ÉÀÇ Á¦µ¿ ¹× Á¶Çâ Á¦¾î ÀÛµ¿ »óÅÂ Ç¥½Ã¿ë Á¤º¸½ÅÈ£";
BA_ "UserSigValidity" SG_ 2239848450 EM_WrngLvlSta 3;
BA_ "RoutingFactor" SG_ 2239848450 EM_WrngLvlSta 5;
BA_ "Version" SG_ 2239848450 EM_WrngLvlSta "19.12.00";
BA_ "Description" SG_ 2239848450 BrkDelVLimReq "- Request ESC whether to release brake control or not when FCA or EM function reduces vehicle¡¯s velocity over 50km/h for ISO 26262.

- FCA ¶Ç´Â EM ÀÛµ¿ Áß ESC°¡ 50km/h ÃÊ°ú °¨¼Ó ½Ã Á¦µ¿Á¦¾î ÇØÁ¦/¹ÌÇØÁ¦ ¿äÃ» ½ÅÈ£ (ISO 26262 ´ëÀÀ)";
BA_ "UserSigValidity" SG_ 2239848450 BrkDelVLimReq 3;
BA_ "RoutingFactor" SG_ 2239848450 BrkDelVLimReq 5;
BA_ "Version" SG_ 2239848450 BrkDelVLimReq "20.03.00";
BA_ "Description" SG_ 2239848450 ADAS_InhbtOffDispSta "This Signal dispaly the ADAS System off inhibition state 

- »óÈ²¿¡ µû¸¥ ADAS ½Ã½ºÅÛ ²ô±â ±ÝÁö »óÅÂ Ç¥½Ã ½ÅÈ£";
BA_ "UserSigValidity" SG_ 2239848450 ADAS_InhbtOffDispSta 3;
BA_ "RoutingFactor" SG_ 2239848450 ADAS_InhbtOffDispSta 5;
BA_ "Version" SG_ 2239848450 ADAS_InhbtOffDispSta "20.12.00";
BA_ "Description" SG_ 2239848450 FCA_WarnTimeSta "This signal describes the FCA warning timing state.

 - FCA °æ°í ½ÃÁ¡ Á¤º¸";
BA_ "UserSigValidity" SG_ 2239848450 FCA_WarnTimeSta 3;
BA_ "RoutingFactor" SG_ 2239848450 FCA_WarnTimeSta 5;
BA_ "Version" SG_ 2239848450 FCA_WarnTimeSta "20.12.00";
BA_ "Description" SG_ 2239848450 FCA_TimetoCllsn "This signal indicates predictive time to Collision between the host vehicle and a forward vehicle.







(PH) = 10*(HEX) [ms]



CAN Message Physical range : 0 ~ 2540 [ms], Resolution : 10ms";
BA_ "GenSigStartValue" SG_ 2239848450 FCA_TimetoCllsn 254;
BA_ "UserSigValidity" SG_ 2239848450 FCA_TimetoCllsn 3;
BA_ "RoutingFactor" SG_ 2239848450 FCA_TimetoCllsn 5;
BA_ "Version" SG_ 2239848450 FCA_TimetoCllsn "19.06.03";
BA_ "Description" SG_ 2239848449 ADAS_CMD_Crc10Val "The data area for CRC calculation is based on the data length (DLC) of the message DB.

The CRC shall be calculated over the entire data block (excluding the CRC bytes) including the user data, alive counter and Data ID



- CRC Polynomial (0x1021) , Ini";
BA_ "GenSigStartValue" SG_ 2239848449 ADAS_CMD_Crc10Val 65535;
BA_ "UserSigValidity" SG_ 2239848449 ADAS_CMD_Crc10Val 3;
BA_ "RoutingFactor" SG_ 2239848449 ADAS_CMD_Crc10Val 5;
BA_ "Version" SG_ 2239848449 ADAS_CMD_Crc10Val "21.09.03";
BA_ "Description" SG_ 2239848449 ADAS_CMD_AlvCnt10Val "For the first transmission request for a data element the counter shall be initialized with 0 and shall be incremented by 1 for every subsequent send request. 

When the counter reaches the maximum value(0xFF), then it shall restart with 0 for the next s";
BA_ "UserSigValidity" SG_ 2239848449 ADAS_CMD_AlvCnt10Val 3;
BA_ "RoutingFactor" SG_ 2239848449 ADAS_CMD_AlvCnt10Val 5;
BA_ "Version" SG_ 2239848449 ADAS_CMD_AlvCnt10Val "21.09.03";
BA_ "Description" SG_ 2239848449 FCA_OnOffEquipSta "This signal describes the FCA Function.

- ½Ã½ºÅÛ ÀåÂø ¿©ºÎ ¹× ½Ã½ºÅÛ on/off Á¤º¸";
BA_ "UserSigValidity" SG_ 2239848449 FCA_OnOffEquipSta 3;
BA_ "RoutingFactor" SG_ 2239848449 FCA_OnOffEquipSta 5;
BA_ "Version" SG_ 2239848449 FCA_OnOffEquipSta "17.12.00";
BA_ "Description" SG_ 2239848449 FCA_SysFlrSta "This signal describes the failure information of FCA Function.

- ½Ã½ºÅÛ Á¤»ó ¶Ç´Â Ä«¸Þ¶ó/·¹ÀÌ´õ/½Ã½ºÅÛ °íÀå»óÅÂ Á¤º¸

0x1: Temporary unavailable by Front View Camera (blockage, high temperature, etc) for Sensor Fusion FCA 

0x2: Temporary unavailable by";
BA_ "UserSigValidity" SG_ 2239848449 FCA_SysFlrSta 3;
BA_ "RoutingFactor" SG_ 2239848449 FCA_SysFlrSta 5;
BA_ "Version" SG_ 2239848449 FCA_SysFlrSta "19.08.04";
BA_ "Description" SG_ 2239848449 FCA_WrngLvlSta "Request CLU to activate the corresponding warning device(s) according to the FCA warning level. (Braking / Steering act)

- FCA ±â´ÉÀÇ Á¦µ¿ ¹× Á¶Çâ Á¦¾î ÀÛµ¿ »óÅÂ Ç¥½Ã¿ë Á¤º¸½ÅÈ£";
BA_ "UserSigValidity" SG_ 2239848449 FCA_WrngLvlSta 3;
BA_ "RoutingFactor" SG_ 2239848449 FCA_WrngLvlSta 5;
BA_ "Version" SG_ 2239848449 FCA_WrngLvlSta "19.06.02";
BA_ "Description" SG_ 2239848449 FCA_VehStpReq "A control request flag for vehicle stop. FCA expects vehicle to be controlled to a complete stop and hold its state by ESC.



- FCA Á¦µ¿»óÈ² Á¾·áÈÄ Á¤Â÷ »óÅÂ À¯Áö¸¦ À§ÇÑ ½ÅÈ£";
BA_ "UserSigValidity" SG_ 2239848449 FCA_VehStpReq 3;
BA_ "RoutingFactor" SG_ 2239848449 FCA_VehStpReq 5;
BA_ "Version" SG_ 2239848449 FCA_VehStpReq "17.12.00";
BA_ "Description" SG_ 2239848449 FCA_StbltActvReq "Depending on the driving situation, FCA tells PSB to release(no alert), retract or pull the seat belt for occupant protection or warning.

- FCA Á¦µ¿»óÈ²½Ã ½ÃÆ®º§Æ® ÀÛµ¿À» À§ÇÑ Á¤º¸ ½ÅÈ£";
BA_ "UserSigValidity" SG_ 2239848449 FCA_StbltActvReq 3;
BA_ "RoutingFactor" SG_ 2239848449 FCA_StbltActvReq 5;
BA_ "Version" SG_ 2239848449 FCA_StbltActvReq "17.12.00";
BA_ "Description" SG_ 2239848449 FCA_HydrlcBstAsstReq "Depending on the driving situation, FCA tells ESC to use lowered HBA (Hydraulic Boost Assist) threshold to sensitize the HBA entrance. 

The boost assist function is more easily activated than under normal driving condition.

- FCA Á¦µ¿»óÈ²½Ã HBA ÀÛµ¿À» ";
BA_ "UserSigValidity" SG_ 2239848449 FCA_HydrlcBstAsstReq 3;
BA_ "RoutingFactor" SG_ 2239848449 FCA_HydrlcBstAsstReq 5;
BA_ "Version" SG_ 2239848449 FCA_HydrlcBstAsstReq "17.12.00";
BA_ "Description" SG_ 2239848449 FCA_DclReqVal "Depending on the driving situation, FCA gives ESC the deceleration command. ESC maintains the deceleration.

- FCA Á¦µ¿À» À§ÇÑ ¿ä±¸ °¨¼Óµµ °ª";
BA_ "UserSigValidity" SG_ 2239848449 FCA_DclReqVal 3;
BA_ "RoutingFactor" SG_ 2239848449 FCA_DclReqVal 5;
BA_ "Version" SG_ 2239848449 FCA_DclReqVal "17.12.00";
BA_ "Description" SG_ 2239848449 FCA_PrefillActvReq "A control requeset flag for FCA first warning. (Audible Warning)

- FCA 1Â÷ Á¦µ¿»óÈ² ¿äÃ»½ÅÈ£";
BA_ "UserSigValidity" SG_ 2239848449 FCA_PrefillActvReq 3;
BA_ "RoutingFactor" SG_ 2239848449 FCA_PrefillActvReq 5;
BA_ "Version" SG_ 2239848449 FCA_PrefillActvReq "17.12.00";
BA_ "Description" SG_ 2239848449 FCA_PartialActvReq "A control requeset flag for FCA second warning. (Partial braking)

- FCA 2Â÷ Á¦µ¿»óÈ² ¿äÃ»½ÅÈ£";
BA_ "UserSigValidity" SG_ 2239848449 FCA_PartialActvReq 3;
BA_ "RoutingFactor" SG_ 2239848449 FCA_PartialActvReq 5;
BA_ "Version" SG_ 2239848449 FCA_PartialActvReq "17.11.00";
BA_ "Description" SG_ 2239848449 FCA_FullActvReq "A control requeset flag for FCA third warning. (Full braking)

- FCA 3Â÷ Á¦µ¿»óÈ² ¿äÃ»½ÅÈ£";
BA_ "UserSigValidity" SG_ 2239848449 FCA_FullActvReq 3;
BA_ "RoutingFactor" SG_ 2239848449 FCA_FullActvReq 5;
BA_ "Version" SG_ 2239848449 FCA_FullActvReq "17.11.00";
BA_ "Description" SG_ 2239848449 FCA_Regulation "This signal contains FCA regulation compliance information.";
BA_ "UserSigValidity" SG_ 2239848449 FCA_Regulation 3;
BA_ "RoutingFactor" SG_ 2239848449 FCA_Regulation 5;
BA_ "Version" SG_ 2239848449 FCA_Regulation "20.12.01";
BA_ "Description" SG_ 2239848449 FCA_SnstvtyModRetVal "This signal is FCA sensitive set mode switch(USM) info return value to cluster.

- FCA ¹Î°¨µµ ¼³Á¤ °ü·Ã USM ¼³Á¤ ½ºÀ§Ä¡ Á¤º¸ÀÇ ¸®ÅÏ °ª";
BA_ "UserSigValidity" SG_ 2239848449 FCA_SnstvtyModRetVal 3;
BA_ "RoutingFactor" SG_ 2239848449 FCA_SnstvtyModRetVal 5;
BA_ "Version" SG_ 2239848449 FCA_SnstvtyModRetVal "17.12.00";
BA_ "Description" SG_ 2239848449 FCA_WrngSndSta "FCA warning sound status";
BA_ "UserSigValidity" SG_ 2239848449 FCA_WrngSndSta 3;
BA_ "RoutingFactor" SG_ 2239848449 FCA_WrngSndSta 5;
BA_ "Version" SG_ 2239848449 FCA_WrngSndSta "18.12.04";
BA_ "Description" SG_ 2378398721 DATC_Crc20Val "The data area for CRC calculation is based on the data length (DLC) of the message DB.

The CRC shall be calculated over the entire data block (excluding the CRC bytes) including the user data, alive counter and Data ID



- CRC Polynomial (0x1021) , Ini";
BA_ "GenSigSendType" SG_ 2378398721 DATC_Crc20Val 4;
BA_ "GenSigStartValue" SG_ 2378398721 DATC_Crc20Val 65535;
BA_ "UserSigValidity" SG_ 2378398721 DATC_Crc20Val 3;
BA_ "Version" SG_ 2378398721 DATC_Crc20Val "21.09.03";
BA_ "Description" SG_ 2378398721 DATC_AlvCnt20Val "For the first transmission request for a data element the counter shall be initialized with 0 and shall be incremented by 1 for every subsequent send request. 

When the counter reaches the maximum value(0xFF), then it shall restart with 0 for the next s";
BA_ "GenSigSendType" SG_ 2378398721 DATC_AlvCnt20Val 4;
BA_ "UserSigValidity" SG_ 2378398721 DATC_AlvCnt20Val 3;
BA_ "Version" SG_ 2378398721 DATC_AlvCnt20Val "21.09.03";
BA_ "Description" SG_ 2378398721 DATC_FragStrhUSMSta "This signal indicate frangrance strength USM state";
BA_ "GenSigSendType" SG_ 2378398721 DATC_FragStrhUSMSta 4;
BA_ "UserSigValidity" SG_ 2378398721 DATC_FragStrhUSMSta 7;
BA_ "Version" SG_ 2378398721 DATC_FragStrhUSMSta "21.01.02";
BA_ "Description" SG_ 2378398721 DATC_FragKindUSMSta "This signal indicate fragrance kind USM state.";
BA_ "GenSigSendType" SG_ 2378398721 DATC_FragKindUSMSta 4;
BA_ "UserSigValidity" SG_ 2378398721 DATC_FragKindUSMSta 7;
BA_ "Version" SG_ 2378398721 DATC_FragKindUSMSta "21.01.02";
BA_ "Description" SG_ 2378398721 DATC_Frag1ExpireDisp "This signal indicate Expire Display of Fragrance No.1";
BA_ "GenSigSendType" SG_ 2378398721 DATC_Frag1ExpireDisp 4;
BA_ "UserSigValidity" SG_ 2378398721 DATC_Frag1ExpireDisp 7;
BA_ "Version" SG_ 2378398721 DATC_Frag1ExpireDisp "21.01.02";
BA_ "Description" SG_ 2378398721 DATC_FragStrhDis "This signal indicate frangrance strength display value.";
BA_ "GenSigSendType" SG_ 2378398721 DATC_FragStrhDis 4;
BA_ "UserSigValidity" SG_ 2378398721 DATC_FragStrhDis 7;
BA_ "Version" SG_ 2378398721 DATC_FragStrhDis "21.01.02";
BA_ "Description" SG_ 2378398721 DATC_FragKindDis "This signal indicate fragrance kind display value.";
BA_ "GenSigSendType" SG_ 2378398721 DATC_FragKindDis 4;
BA_ "UserSigValidity" SG_ 2378398721 DATC_FragKindDis 7;
BA_ "Version" SG_ 2378398721 DATC_FragKindDis "21.01.02";
BA_ "Description" SG_ 2378398721 DATC_Frag2ExpireDisp "This signal indicate Expire Display of Fragrance No.2";
BA_ "GenSigSendType" SG_ 2378398721 DATC_Frag2ExpireDisp 4;
BA_ "UserSigValidity" SG_ 2378398721 DATC_Frag2ExpireDisp 7;
BA_ "Version" SG_ 2378398721 DATC_Frag2ExpireDisp "21.01.02";
BA_ "Description" SG_ 2378398721 DATC_VitalityFragranceSta "This signal indicate USM setting state of Fragrance for Vatality Mood.";
BA_ "GenSigSendType" SG_ 2378398721 DATC_VitalityFragranceSta 4;
BA_ "UserSigValidity" SG_ 2378398721 DATC_VitalityFragranceSta 3;
BA_ "Version" SG_ 2378398721 DATC_VitalityFragranceSta "21.01.02";
BA_ "Description" SG_ 2378398721 DATC_DelightFragranceSta "This signal indicate USM setting state of Fragrance for Delight Mood.";
BA_ "GenSigSendType" SG_ 2378398721 DATC_DelightFragranceSta 4;
BA_ "UserSigValidity" SG_ 2378398721 DATC_DelightFragranceSta 3;
BA_ "Version" SG_ 2378398721 DATC_DelightFragranceSta "21.01.02";
BA_ "Description" SG_ 2378398721 DATC_CareFragranceSta "This signal indicate USM setting state of Fragrance for Care Mood.";
BA_ "GenSigSendType" SG_ 2378398721 DATC_CareFragranceSta 4;
BA_ "UserSigValidity" SG_ 2378398721 DATC_CareFragranceSta 3;
BA_ "Version" SG_ 2378398721 DATC_CareFragranceSta "21.01.02";
BA_ "Description" SG_ 2378398721 DATC_ComfortFragranceSta "This signal indicate USM setting state of Fragrance for Comfort Mood.";
BA_ "GenSigSendType" SG_ 2378398721 DATC_ComfortFragranceSta 4;
BA_ "UserSigValidity" SG_ 2378398721 DATC_ComfortFragranceSta 3;
BA_ "Version" SG_ 2378398721 DATC_ComfortFragranceSta "21.01.02";
BA_ "Description" SG_ 2378398721 DATC_Frag1Inform "This signal indicate Fragrance 1 information.";
BA_ "GenSigSendType" SG_ 2378398721 DATC_Frag1Inform 4;
BA_ "UserSigValidity" SG_ 2378398721 DATC_Frag1Inform 7;
BA_ "Version" SG_ 2378398721 DATC_Frag1Inform "21.01.02";
BA_ "Description" SG_ 2378398721 DATC_Frag1RemainDisp "This signal indicate Remain Display of Fragrance No.1";
BA_ "GenSigSendType" SG_ 2378398721 DATC_Frag1RemainDisp 4;
BA_ "UserSigValidity" SG_ 2378398721 DATC_Frag1RemainDisp 7;
BA_ "Version" SG_ 2378398721 DATC_Frag1RemainDisp "21.01.02";
BA_ "Description" SG_ 2378398721 DATC_Frag2Inform "This signal indicate Fragrance 2 Information.";
BA_ "GenSigSendType" SG_ 2378398721 DATC_Frag2Inform 4;
BA_ "UserSigValidity" SG_ 2378398721 DATC_Frag2Inform 7;
BA_ "Version" SG_ 2378398721 DATC_Frag2Inform "21.01.02";
BA_ "Description" SG_ 2378398721 DATC_Frag2RemainDisp "This signal indicate Remains Display of Fragrance No.2";
BA_ "GenSigSendType" SG_ 2378398721 DATC_Frag2RemainDisp 4;
BA_ "UserSigValidity" SG_ 2378398721 DATC_Frag2RemainDisp 7;
BA_ "Version" SG_ 2378398721 DATC_Frag2RemainDisp "21.01.02";
BA_ "Description" SG_ 2256644609 CLU_Crc1Val "The data area for CRC calculation is based on the data length (DLC) of the message DB.

The CRC shall be calculated over the entire data block (excluding the CRC bytes) including the user data, alive counter and Data ID



- CRC Polynomial (0x1021) , Ini";
BA_ "GenSigStartValue" SG_ 2256644609 CLU_Crc1Val 65535;
BA_ "UserSigValidity" SG_ 2256644609 CLU_Crc1Val 3;
BA_ "RoutingFactor" SG_ 2256644609 CLU_Crc1Val 5;
BA_ "Version" SG_ 2256644609 CLU_Crc1Val "21.09.03";
BA_ "Description" SG_ 2256644609 CLU_AlvCnt1Val "For the first transmission request for a data element the counter shall be initialized with 0 and shall be incremented by 1 for every subsequent send request. 

When the counter reaches the maximum value(0xFF), then it shall restart with 0 for the next s";
BA_ "UserSigValidity" SG_ 2256644609 CLU_AlvCnt1Val 3;
BA_ "RoutingFactor" SG_ 2256644609 CLU_AlvCnt1Val 5;
BA_ "Version" SG_ 2256644609 CLU_AlvCnt1Val "21.09.03";
BA_ "Description" SG_ 2256644609 CLU_DtntOutSta "This signal indicates the status of detent illumination. Cluster sends the detent information for a Unified Illumination system.";
BA_ "UserSigValidity" SG_ 2256644609 CLU_DtntOutSta 0;
BA_ "RoutingFactor" SG_ 2256644609 CLU_DtntOutSta 5;
BA_ "Version" SG_ 2256644609 CLU_DtntOutSta "17.11.00";
BA_ "Description" SG_ 2256644609 CLU_SpdUnitTyp "This signal indicates the unit of the speed displayed in the speedometer.";
BA_ "UserSigValidity" SG_ 2256644609 CLU_SpdUnitTyp 3;
BA_ "RoutingFactor" SG_ 2256644609 CLU_SpdUnitTyp 5;
BA_ "Version" SG_ 2256644609 CLU_SpdUnitTyp "17.11.00";
BA_ "Description" SG_ 2256644609 CLU_DisSpdDcmlVal "The signal 'CF_Clu_VanzDecimal' means the extra value of the signal 'CF_Clu_Vanz' (vehicle speed which is indicated in the speedometer)

Also, This signal should be sent in km/h or MPH according to the 'CF_Clu_SPEED_UNIT' signal.

CF_Clu_SPEED_UNIT = 0 :";
BA_ "UserSigValidity" SG_ 2256644609 CLU_DisSpdDcmlVal 3;
BA_ "RoutingFactor" SG_ 2256644609 CLU_DisSpdDcmlVal 5;
BA_ "Version" SG_ 2256644609 CLU_DisSpdDcmlVal "17.11.00";
BA_ "Description" SG_ 2256644609 CLU_SWRCCrsMainSwSta "Cruise on/off switch";
BA_ "UserSigValidity" SG_ 2256644609 CLU_SWRCCrsMainSwSta 3;
BA_ "RoutingFactor" SG_ 2256644609 CLU_SWRCCrsMainSwSta 5;
BA_ "Version" SG_ 2256644609 CLU_SWRCCrsMainSwSta "18.04.00";
BA_ "Description" SG_ 2256644609 CLU_SWRCCrsSwSta "Depending on whether One-touch logic is applied, the meaning of each signal value is divided into two cases as shown below



Case1) Not applied

0x0:Idle Position

0x1:Resume/Plus

0x2:Set/Minus

0x3:Time gap (Distance, SCC only)

0x4:ACC/SCC cancel



";
BA_ "UserSigValidity" SG_ 2256644609 CLU_SWRCCrsSwSta 3;
BA_ "RoutingFactor" SG_ 2256644609 CLU_SWRCCrsSwSta 5;
BA_ "Version" SG_ 2256644609 CLU_SWRCCrsSwSta "18.07.01";
BA_ "Description" SG_ 2256644609 CLU_SWRCLFASwSta "LFA/HDA on/off switch";
BA_ "UserSigValidity" SG_ 2256644609 CLU_SWRCLFASwSta 3;
BA_ "RoutingFactor" SG_ 2256644609 CLU_SWRCLFASwSta 5;
BA_ "Version" SG_ 2256644609 CLU_SWRCLFASwSta "18.04.00";
BA_ "Description" SG_ 2256644609 CLU_SWRCSldMainSwSta "Speedlimiter on/off switch";
BA_ "UserSigValidity" SG_ 2256644609 CLU_SWRCSldMainSwSta 3;
BA_ "RoutingFactor" SG_ 2256644609 CLU_SWRCSldMainSwSta 5;
BA_ "Version" SG_ 2256644609 CLU_SWRCSldMainSwSta "18.04.00";
BA_ "Description" SG_ 2256644609 CLU_RhstaLvlSta "This signal is used for a rheostat level of CLUSTER from 1 to 21 level (21 level : Detent) for a Unified Illumination system.



¡Ø Start Value : Current value";
BA_ "UserSigValidity" SG_ 2256644609 CLU_RhstaLvlSta 0;
BA_ "RoutingFactor" SG_ 2256644609 CLU_RhstaLvlSta 5;
BA_ "Version" SG_ 2256644609 CLU_RhstaLvlSta "17.11.00";
BA_ "Description" SG_ 2256644609 CLU_DisSpdVal "The vehicle speed which is indicated in the speedmeter has to be sent to SCC. This value is used for evalution of SCC command values instead of the vehicle velocity in order to avoid significant difference between the speedmeter indicator and the set spe";
BA_ "UserSigValidity" SG_ 2256644609 CLU_DisSpdVal 3;
BA_ "RoutingFactor" SG_ 2256644609 CLU_DisSpdVal 5;
BA_ "Version" SG_ 2256644609 CLU_DisSpdVal "17.12.03";
BA_ "Description" SG_ 2256644609 CLU_OKSwSta "This signal represents operating status of Ok Switch in Steering Wheel. Default value of this signal is 0 and the value is set to 1 only while a driver is pressing the OK Switch.";
BA_ "UserSigValidity" SG_ 2256644609 CLU_OKSwSta 3;
BA_ "RoutingFactor" SG_ 2256644609 CLU_OKSwSta 5;
BA_ "Version" SG_ 2256644609 CLU_OKSwSta "19.03.06";
BA_ "Description" SG_ 2256644610 CLU_DisSpdVal_KPH "The vehicle speed which is indicated in the speedmeter.

This signal should be sent in km/h only.";
BA_ "UserSigValidity" SG_ 2256644610 CLU_DisSpdVal_KPH 3;
BA_ "RoutingFactor" SG_ 2256644610 CLU_DisSpdVal_KPH 5;
BA_ "Version" SG_ 2256644610 CLU_DisSpdVal_KPH "17.12.09";
BA_ "Description" SG_ 2256644610 CLU_CUSTOMSta_NEW "This is a signal for New concept CUSTOM mode in AVN USM

This is a confirm signal for selecting CUSTOM mode in AVN USM

And Other units refer this signal when CUSTOM mode (CLU_DrvngModSwSta=0x6

). Other unit decided the Detailed CUSTOM Mode with this si";
BA_ "UserSigValidity" SG_ 2256644610 CLU_CUSTOMSta_NEW 3;
BA_ "RoutingFactor" SG_ 2256644610 CLU_CUSTOMSta_NEW 5;
BA_ "Version" SG_ 2256644610 CLU_CUSTOMSta_NEW "20.08.07";
BA_ "Description" SG_ 2256644610 CLU_AutoBrightSta "This signal is used for a auto bright level of CLUSTER from 1step to 200step for a Unified Illumination system.



¡Ø Start Value : Current value";
BA_ "UserSigValidity" SG_ 2256644610 CLU_AutoBrightSta 0;
BA_ "RoutingFactor" SG_ 2256644610 CLU_AutoBrightSta 5;
BA_ "Version" SG_ 2256644610 CLU_AutoBrightSta "20.12.05";
BA_ "Description" SG_ 2256644610 CLU_NotMinModeBrightSta "This signal is used for a Cluster brightness level when not in minimum brightness mode.



¡Ø Start Value : Current value";
BA_ "UserSigValidity" SG_ 2256644610 CLU_NotMinModeBrightSta 0;
BA_ "RoutingFactor" SG_ 2256644610 CLU_NotMinModeBrightSta 5;
BA_ "Version" SG_ 2256644610 CLU_NotMinModeBrightSta "22.07.06";
BA_ "Description" SG_ 2256644610 CLU_PwrAutoOffResetReq_HCU "This signal is used for a request to reset power auto off time

when OK sw on, this signal 0x1 for 3 period times,and send 0x0 

It is signal for HCU";
BA_ "UserSigValidity" SG_ 2256644610 CLU_PwrAutoOffResetReq_HCU 3;
BA_ "RoutingFactor" SG_ 2256644610 CLU_PwrAutoOffResetReq_HCU 5;
BA_ "Version" SG_ 2256644610 CLU_PwrAutoOffResetReq_HCU "19.10.03";
BA_ "Description" SG_ 350 DSAU_AirSptTimeRValueSet "Air Support Time(Massage Time) USM R Value";
BA_ "GenSigSendType" SG_ 350 DSAU_AirSptTimeRValueSet 4;
BA_ "UserSigValidity" SG_ 350 DSAU_AirSptTimeRValueSet 3;
BA_ "NetworkRequest" SG_ 350 DSAU_AirSptTimeRValueSet 0;
BA_ "NetworkRequestHoldingTime" SG_ 350 DSAU_AirSptTimeRValueSet 5000;
BA_ "Version" SG_ 350 DSAU_AirSptTimeRValueSet "19.11.06";
BA_ "Description" SG_ 350 DSAU_DrvPostureAssistRValueSet "Drive Seat Posture Assist Function USM R Value";
BA_ "GenSigSendType" SG_ 350 DSAU_DrvPostureAssistRValueSet 4;
BA_ "UserSigValidity" SG_ 350 DSAU_DrvPostureAssistRValueSet 3;
BA_ "NetworkRequest" SG_ 350 DSAU_DrvPostureAssistRValueSet 0;
BA_ "NetworkRequestHoldingTime" SG_ 350 DSAU_DrvPostureAssistRValueSet 5000;
BA_ "Version" SG_ 350 DSAU_DrvPostureAssistRValueSet "19.11.06";
BA_ "Description" SG_ 350 DSAU_DrvSmtAirSptRValueSet "Seat Smart Air Support Function USM R Value";
BA_ "GenSigSendType" SG_ 350 DSAU_DrvSmtAirSptRValueSet 4;
BA_ "UserSigValidity" SG_ 350 DSAU_DrvSmtAirSptRValueSet 3;
BA_ "NetworkRequest" SG_ 350 DSAU_DrvSmtAirSptRValueSet 0;
BA_ "NetworkRequestHoldingTime" SG_ 350 DSAU_DrvSmtAirSptRValueSet 5000;
BA_ "Version" SG_ 350 DSAU_DrvSmtAirSptRValueSet "19.12.00";
BA_ "Description" SG_ 350 DSAU_DrvSmtSptRValueSet "Seat Smart Support Function USM R Value";
BA_ "GenSigSendType" SG_ 350 DSAU_DrvSmtSptRValueSet 4;
BA_ "UserSigValidity" SG_ 350 DSAU_DrvSmtSptRValueSet 3;
BA_ "NetworkRequest" SG_ 350 DSAU_DrvSmtSptRValueSet 0;
BA_ "NetworkRequestHoldingTime" SG_ 350 DSAU_DrvSmtSptRValueSet 5000;
BA_ "Version" SG_ 350 DSAU_DrvSmtSptRValueSet "19.12.01";
BA_ "Description" SG_ 350 DSAU_CushSoftRValueSet "Cushion Soft R Value";
BA_ "GenSigSendType" SG_ 350 DSAU_CushSoftRValueSet 4;
BA_ "UserSigValidity" SG_ 350 DSAU_CushSoftRValueSet 3;
BA_ "NetworkRequest" SG_ 350 DSAU_CushSoftRValueSet 0;
BA_ "NetworkRequestHoldingTime" SG_ 350 DSAU_CushSoftRValueSet 5000;
BA_ "Version" SG_ 350 DSAU_CushSoftRValueSet "20.04.02";
BA_ "Description" SG_ 350 DSAU_BackSoftRValueSet "Back Soft USM R Value";
BA_ "GenSigSendType" SG_ 350 DSAU_BackSoftRValueSet 4;
BA_ "UserSigValidity" SG_ 350 DSAU_BackSoftRValueSet 3;
BA_ "NetworkRequest" SG_ 350 DSAU_BackSoftRValueSet 0;
BA_ "NetworkRequestHoldingTime" SG_ 350 DSAU_BackSoftRValueSet 5000;
BA_ "Version" SG_ 350 DSAU_BackSoftRValueSet "20.04.02";
BA_ "Description" SG_ 350 DSAU_AirSptModeRValueSet "Air Support Mode(Massage Mode) USM R Value";
BA_ "GenSigSendType" SG_ 350 DSAU_AirSptModeRValueSet 4;
BA_ "UserSigValidity" SG_ 350 DSAU_AirSptModeRValueSet 3;
BA_ "NetworkRequest" SG_ 350 DSAU_AirSptModeRValueSet 0;
BA_ "NetworkRequestHoldingTime" SG_ 350 DSAU_AirSptModeRValueSet 5000;
BA_ "Version" SG_ 350 DSAU_AirSptModeRValueSet "19.11.06";
BA_ "Description" SG_ 350 DSAU_MsgModeSts "Air Support Mode Function Operating Display";
BA_ "GenSigSendType" SG_ 350 DSAU_MsgModeSts 4;
BA_ "UserSigValidity" SG_ 350 DSAU_MsgModeSts 3;
BA_ "NetworkRequest" SG_ 350 DSAU_MsgModeSts 0;
BA_ "NetworkRequestHoldingTime" SG_ 350 DSAU_MsgModeSts 5000;
BA_ "Version" SG_ 350 DSAU_MsgModeSts "20.04.02";
BA_ "Description" SG_ 350 DSAU_MsgModeStrength "Air Support intensity regulation(Massage Strenth)";
BA_ "GenSigSendType" SG_ 350 DSAU_MsgModeStrength 4;
BA_ "UserSigValidity" SG_ 350 DSAU_MsgModeStrength 3;
BA_ "NetworkRequest" SG_ 350 DSAU_MsgModeStrength 0;
BA_ "NetworkRequestHoldingTime" SG_ 350 DSAU_MsgModeStrength 5000;
BA_ "Version" SG_ 350 DSAU_MsgModeStrength "19.12.01";
BA_ "Description" SG_ 350 DSAU_MoodTrpyRValueSet "Drive Seat Mood Therapy R Value";
BA_ "GenSigSendType" SG_ 350 DSAU_MoodTrpyRValueSet 4;
BA_ "UserSigValidity" SG_ 350 DSAU_MoodTrpyRValueSet 3;
BA_ "NetworkRequest" SG_ 350 DSAU_MoodTrpyRValueSet 0;
BA_ "NetworkRequestHoldingTime" SG_ 350 DSAU_MoodTrpyRValueSet 5000;
BA_ "Version" SG_ 350 DSAU_MoodTrpyRValueSet "20.07.03";
BA_ "Description" SG_ 350 DSAU_MoodTrpyCareSta "Drive Seat Mood Therapy Care Mode R Value";
BA_ "GenSigSendType" SG_ 350 DSAU_MoodTrpyCareSta 4;
BA_ "UserSigValidity" SG_ 350 DSAU_MoodTrpyCareSta 3;
BA_ "NetworkRequest" SG_ 350 DSAU_MoodTrpyCareSta 0;
BA_ "NetworkRequestHoldingTime" SG_ 350 DSAU_MoodTrpyCareSta 5000;
BA_ "Version" SG_ 350 DSAU_MoodTrpyCareSta "20.07.12";
BA_ "Description" SG_ 350 DSAU_MoodTrpyComfSta "Drive Seat Mood Therapy Comfort Mode R Value";
BA_ "GenSigSendType" SG_ 350 DSAU_MoodTrpyComfSta 4;
BA_ "UserSigValidity" SG_ 350 DSAU_MoodTrpyComfSta 3;
BA_ "NetworkRequest" SG_ 350 DSAU_MoodTrpyComfSta 0;
BA_ "NetworkRequestHoldingTime" SG_ 350 DSAU_MoodTrpyComfSta 5000;
BA_ "Version" SG_ 350 DSAU_MoodTrpyComfSta "20.07.12";
BA_ "Description" SG_ 350 DASU_AirSptStrRValueSet "Air Support Strenth(Massage Strenth) USM R Value";
BA_ "GenSigSendType" SG_ 350 DASU_AirSptStrRValueSet 4;
BA_ "UserSigValidity" SG_ 350 DASU_AirSptStrRValueSet 3;
BA_ "NetworkRequest" SG_ 350 DASU_AirSptStrRValueSet 0;
BA_ "NetworkRequestHoldingTime" SG_ 350 DASU_AirSptStrRValueSet 5000;
BA_ "Version" SG_ 350 DASU_AirSptStrRValueSet "20.07.11";
BA_ "Description" SG_ 349 DSAU_CushInfDis "DSAU_CushionInflationDisplay";
BA_ "GenSigSendType" SG_ 349 DSAU_CushInfDis 4;
BA_ "UserSigValidity" SG_ 349 DSAU_CushInfDis 3;
BA_ "NetworkRequest" SG_ 349 DSAU_CushInfDis 0;
BA_ "NetworkRequestHoldingTime" SG_ 349 DSAU_CushInfDis 5000;
BA_ "Version" SG_ 349 DSAU_CushInfDis "19.11.06";
BA_ "Description" SG_ 349 DSAU_CushDefDis "DSAU_CushionDeflationDisplay";
BA_ "GenSigSendType" SG_ 349 DSAU_CushDefDis 4;
BA_ "UserSigValidity" SG_ 349 DSAU_CushDefDis 3;
BA_ "NetworkRequest" SG_ 349 DSAU_CushDefDis 0;
BA_ "NetworkRequestHoldingTime" SG_ 349 DSAU_CushDefDis 5000;
BA_ "Version" SG_ 349 DSAU_CushDefDis "19.11.06";
BA_ "Description" SG_ 348 DSAU_BolsterInfDis "DSAU_BolsterInflationDisplay";
BA_ "GenSigSendType" SG_ 348 DSAU_BolsterInfDis 4;
BA_ "UserSigValidity" SG_ 348 DSAU_BolsterInfDis 3;
BA_ "NetworkRequest" SG_ 348 DSAU_BolsterInfDis 0;
BA_ "NetworkRequestHoldingTime" SG_ 348 DSAU_BolsterInfDis 5000;
BA_ "Version" SG_ 348 DSAU_BolsterInfDis "19.11.06";
BA_ "Description" SG_ 348 DSAU_BolsterDefDis "DSAU_BolsterDeflationDisplay";
BA_ "GenSigSendType" SG_ 348 DSAU_BolsterDefDis 4;
BA_ "UserSigValidity" SG_ 348 DSAU_BolsterDefDis 3;
BA_ "NetworkRequest" SG_ 348 DSAU_BolsterDefDis 0;
BA_ "NetworkRequestHoldingTime" SG_ 348 DSAU_BolsterDefDis 5000;
BA_ "Version" SG_ 348 DSAU_BolsterDefDis "19.11.06";
BA_ "Description" SG_ 346 DPSS_WalkInSwitchSts "DPSS_WalkInSwitchStatus";
BA_ "GenSigSendType" SG_ 346 DPSS_WalkInSwitchSts 4;
BA_ "UserSigValidity" SG_ 346 DPSS_WalkInSwitchSts 3;
BA_ "NetworkRequest" SG_ 346 DPSS_WalkInSwitchSts 0;
BA_ "NetworkRequestHoldingTime" SG_ 346 DPSS_WalkInSwitchSts 5000;
BA_ "Version" SG_ 346 DPSS_WalkInSwitchSts "19.11.06";
BA_REL_ "GenSigTimeoutTime" BU_SG_REL_ ALBCU SG_ 287 APSS_LumbarUpSw 1500;
BA_REL_ "GenSigTimeoutTime" BU_SG_REL_ CGW_CCU SG_ 287 APSS_LumbarUpSw 1500;
BA_REL_ "GenSigTimeoutTime" BU_SG_REL_ ALBCU SG_ 287 APSS_LumbarMidSw 1500;
BA_REL_ "GenSigTimeoutTime" BU_SG_REL_ CGW_CCU SG_ 287 APSS_LumbarMidSw 1500;
BA_REL_ "GenSigTimeoutTime" BU_SG_REL_ ALBCU SG_ 287 APSS_LumbarLowSw 1500;
BA_REL_ "GenSigTimeoutTime" BU_SG_REL_ CGW_CCU SG_ 287 APSS_LumbarLowSw 1500;
BA_REL_ "GenSigTimeoutTime" BU_SG_REL_ ALBCU SG_ 287 APSS_LumbarDefSw 1500;
BA_REL_ "GenSigTimeoutTime" BU_SG_REL_ CGW_CCU SG_ 287 APSS_LumbarDefSw 1500;
BA_REL_ "GenSigTimeoutTime" BU_SG_REL_ ALBCU SG_ 287 APSS_BolsterInfSw 1500;
BA_REL_ "GenSigTimeoutTime" BU_SG_REL_ CGW_CCU SG_ 287 APSS_BolsterInfSw 1500;
BA_REL_ "GenSigTimeoutTime" BU_SG_REL_ ALBCU SG_ 287 APSS_BolsterDefSw 1500;
BA_REL_ "GenSigTimeoutTime" BU_SG_REL_ CGW_CCU SG_ 287 APSS_BolsterDefSw 1500;
BA_REL_ "GenSigTimeoutTime" BU_SG_REL_ ALBCU SG_ 287 APSS_ActiveSw 1500;
BA_REL_ "GenSigTimeoutTime" BU_SG_REL_ ALBCU SG_ 287 APSS_CushInfSw 1500;
BA_REL_ "GenSigTimeoutTime" BU_SG_REL_ ALBCU SG_ 287 APSS_CushDefSw 1500;
BA_REL_ "GenSigTimeoutTime" BU_SG_REL_ ALBCU SG_ 287 APSS_CushOnOffTch 1500;
BA_REL_ "GenSigTimeoutTime" BU_SG_REL_ RLHV SG_ 2395189761 DATC_Typ 1500;
BA_REL_ "GenSigTimeoutTime" BU_SG_REL_ RRHV SG_ 2395189761 DATC_Typ 1500;
BA_REL_ "GenSigTimeoutTime" BU_SG_REL_ SHVU_FR SG_ 2395189761 DATC_Typ 1500;
BA_REL_ "GenSigTimeoutTime" BU_SG_REL_ SHVU_RR SG_ 2395189761 DATC_Typ 1500;
BA_REL_ "GenSigTimeoutTime" BU_SG_REL_ ATS SG_ 2395189761 DATC_Typ 1500;
BA_REL_ "GenSigTimeoutTime" BU_SG_REL_ ATS SG_ 2395189761 DATC_Opt1Typ 1500;
BA_REL_ "GenSigTimeoutTime" BU_SG_REL_ ATS SG_ 2395189761 DATC_Opt3Typ 1500;
BA_REL_ "GenSigTimeoutTime" BU_SG_REL_ ATS SG_ 2395189761 DATC_Opt2Typ 1500;
BA_REL_ "GenSigTimeoutTime" BU_SG_REL_ ATS SG_ 2395189761 DATC_Opt4Typ 1500;
BA_REL_ "GenSigTimeoutTime" BU_SG_REL_ APSU SG_ 2395189761 DATC_StrWhlUSMSta 1500;
BA_REL_ "GenSigTimeoutTime" BU_SG_REL_ CGW_CCU SG_ 271 ASAU_AirSptTimeRValueSet 1500;
BA_REL_ "GenSigTimeoutTime" BU_SG_REL_ CGW_CCU SG_ 271 ASAU_AstSmtAirSptRValueSet 1500;
BA_REL_ "GenSigTimeoutTime" BU_SG_REL_ CGW_CCU SG_ 271 ASAU_CushSoftRValueSet 1500;
BA_REL_ "GenSigTimeoutTime" BU_SG_REL_ CGW_CCU SG_ 271 ASAU_AirSptModeRValueSet 1500;
BA_REL_ "GenSigTimeoutTime" BU_SG_REL_ ATS SG_ 271 ASAU_NotFootMsgOperStaWarnPE 1500;
BA_REL_ "GenSigTimeoutTime" BU_SG_REL_ ATS SG_ 271 ASAU_RRFootAirSptRValueSet 1500;
BA_REL_ "GenSigTimeoutTime" BU_SG_REL_ ATS SG_ 271 ASAU_RRFootAirSptHeatRValueSet 1500;
BA_REL_ "GenSigTimeoutTime" BU_SG_REL_ CGW_CCU SG_ 271 ASAU_MoodTrpyRValueSet 1500;
BA_REL_ "GenSigTimeoutTime" BU_SG_REL_ CGW_CCU SG_ 271 ASAU_MoodTrpyCareSta 1500;
BA_REL_ "GenSigTimeoutTime" BU_SG_REL_ CGW_CCU SG_ 271 ASAU_MoodTrpyComfSta 1500;
BA_REL_ "GenSigTimeoutTime" BU_SG_REL_ CGW_CCU SG_ 271 ASAU_AirSptStrRValueSet 1500;
BA_REL_ "GenSigTimeoutTime" BU_SG_REL_ PSB SG_ 2244048130 ESC_HDP_FltMonSta 1500;
BA_REL_ "GenSigTimeoutTime" BU_SG_REL_ PSB SG_ 2244048130 ESC_HDP_EgSta 1500;
BA_REL_ "GenSigTimeoutTime" BU_SG_REL_ APSU SG_ 2239848450 FCA_WrngTrgtDis 1500;
BA_REL_ "GenSigTimeoutTime" BU_SG_REL_ PSB SG_ 2239848449 FCA_SysFlrSta 1500;
BA_REL_ "GenSigTimeoutTime" BU_SG_REL_ SWRC SG_ 2239848449 FCA_WrngLvlSta 1500;
BA_REL_ "GenSigTimeoutTime" BU_SG_REL_ APSU SG_ 2239848449 FCA_WrngLvlSta 1500;
BA_REL_ "GenSigTimeoutTime" BU_SG_REL_ RRPSU SG_ 2239848449 FCA_WrngLvlSta 1500;
BA_REL_ "GenSigTimeoutTime" BU_SG_REL_ RLPSU SG_ 2239848449 FCA_WrngLvlSta 1500;
BA_REL_ "GenSigTimeoutTime" BU_SG_REL_ SWRC SG_ 2239848449 FCA_VehStpReq 1500;
BA_REL_ "GenSigTimeoutTime" BU_SG_REL_ PSB SG_ 2239848449 FCA_StbltActvReq 1500;
BA_REL_ "GenSigTimeoutTime" BU_SG_REL_ APSU SG_ 2239848449 FCA_FullActvReq 1500;
BA_REL_ "GenSigTimeoutTime" BU_SG_REL_ RRPSU SG_ 2239848449 FCA_FullActvReq 1500;
BA_REL_ "GenSigTimeoutTime" BU_SG_REL_ RLPSU SG_ 2239848449 FCA_FullActvReq 1500;
BA_REL_ "GenSigTimeoutTime" BU_SG_REL_ ATS SG_ 2378398721 DATC_FragStrhUSMSta 1500;
BA_REL_ "GenSigTimeoutTime" BU_SG_REL_ ATS SG_ 2378398721 DATC_FragKindUSMSta 1500;
BA_REL_ "GenSigTimeoutTime" BU_SG_REL_ ATS SG_ 2378398721 DATC_Frag1ExpireDisp 1500;
BA_REL_ "GenSigTimeoutTime" BU_SG_REL_ ATS SG_ 2378398721 DATC_FragStrhDis 1500;
BA_REL_ "GenSigTimeoutTime" BU_SG_REL_ ATS SG_ 2378398721 DATC_FragKindDis 1500;
BA_REL_ "GenSigTimeoutTime" BU_SG_REL_ ATS SG_ 2378398721 DATC_Frag2ExpireDisp 1500;
BA_REL_ "GenSigTimeoutTime" BU_SG_REL_ ATS SG_ 2378398721 DATC_Frag1Inform 1500;
BA_REL_ "GenSigTimeoutTime" BU_SG_REL_ ATS SG_ 2378398721 DATC_Frag1RemainDisp 1500;
BA_REL_ "GenSigTimeoutTime" BU_SG_REL_ ATS SG_ 2378398721 DATC_Frag2Inform 1500;
BA_REL_ "GenSigTimeoutTime" BU_SG_REL_ ATS SG_ 2378398721 DATC_Frag2RemainDisp 1500;
BA_REL_ "GenSigTimeoutTime" BU_SG_REL_ SHVU_RR SG_ 2256644609 CLU_Crc1Val 1500;
BA_REL_ "GenSigTimeoutTime" BU_SG_REL_ DPSU SG_ 2256644609 CLU_Crc1Val 1500;
BA_REL_ "GenSigTimeoutTime" BU_SG_REL_ ATS SG_ 2256644609 CLU_Crc1Val 1500;
BA_REL_ "GenSigTimeoutTime" BU_SG_REL_ SHVU_RR SG_ 2256644609 CLU_AlvCnt1Val 1500;
BA_REL_ "GenSigTimeoutTime" BU_SG_REL_ DPSU SG_ 2256644609 CLU_AlvCnt1Val 1500;
BA_REL_ "GenSigTimeoutTime" BU_SG_REL_ ATS SG_ 2256644609 CLU_AlvCnt1Val 1500;
BA_REL_ "GenSigTimeoutTime" BU_SG_REL_ EMCU SG_ 2256644609 CLU_AlvCnt1Val 1500;
BA_REL_ "GenSigTimeoutTime" BU_SG_REL_ FCS SG_ 2256644609 CLU_DtntOutSta 1500;
BA_REL_ "GenSigTimeoutTime" BU_SG_REL_ WPC SG_ 2256644609 CLU_DtntOutSta 1500;
BA_REL_ "GenSigTimeoutTime" BU_SG_REL_ RWPC SG_ 2256644609 CLU_DtntOutSta 1500;
BA_REL_ "GenSigTimeoutTime" BU_SG_REL_ ARS SG_ 2256644609 CLU_DtntOutSta 1500;
BA_REL_ "GenSigTimeoutTime" BU_SG_REL_ SWRC SG_ 2256644609 CLU_DtntOutSta 1500;
BA_REL_ "GenSigTimeoutTime" BU_SG_REL_ APSU SG_ 2256644609 CLU_DtntOutSta 1500;
BA_REL_ "GenSigTimeoutTime" BU_SG_REL_ RLHV SG_ 2256644609 CLU_DtntOutSta 1500;
BA_REL_ "GenSigTimeoutTime" BU_SG_REL_ RRHV SG_ 2256644609 CLU_DtntOutSta 1500;
BA_REL_ "GenSigTimeoutTime" BU_SG_REL_ SHVU_FR SG_ 2256644609 CLU_DtntOutSta 1500;
BA_REL_ "GenSigTimeoutTime" BU_SG_REL_ SHVU_RR SG_ 2256644609 CLU_DtntOutSta 1500;
BA_REL_ "GenSigTimeoutTime" BU_SG_REL_ DPSU SG_ 2256644609 CLU_DtntOutSta 1500;
BA_REL_ "GenSigTimeoutTime" BU_SG_REL_ RCS SG_ 2256644609 CLU_DtntOutSta 1500;
BA_REL_ "GenSigTimeoutTime" BU_SG_REL_ RRPSU SG_ 2256644609 CLU_DtntOutSta 1500;
BA_REL_ "GenSigTimeoutTime" BU_SG_REL_ RLPSU SG_ 2256644609 CLU_DtntOutSta 1500;
BA_REL_ "GenSigTimeoutTime" BU_SG_REL_ ATS SG_ 2256644609 CLU_DtntOutSta 1500;
BA_REL_ "GenSigTimeoutTime" BU_SG_REL_ DSAU SG_ 2256644609 CLU_DtntOutSta 1500;
BA_REL_ "GenSigTimeoutTime" BU_SG_REL_ ASAU SG_ 2256644609 CLU_DtntOutSta 1500;
BA_REL_ "GenSigTimeoutTime" BU_SG_REL_ OHCL SG_ 2256644609 CLU_DtntOutSta 1500;
BA_REL_ "GenSigTimeoutTime" BU_SG_REL_ WPC2 SG_ 2256644609 CLU_DtntOutSta 1500;
BA_REL_ "GenSigTimeoutTime" BU_SG_REL_ DPSU SG_ 2256644609 CLU_SpdUnitTyp 1500;
BA_REL_ "GenSigTimeoutTime" BU_SG_REL_ BLTN_CAM SG_ 2256644609 CLU_SpdUnitTyp 1500;
BA_REL_ "GenSigTimeoutTime" BU_SG_REL_ EMCU SG_ 2256644609 CLU_SpdUnitTyp 1500;
BA_REL_ "GenSigTimeoutTime" BU_SG_REL_ WPC2 SG_ 2256644609 CLU_SpdUnitTyp 1500;
BA_REL_ "GenSigTimeoutTime" BU_SG_REL_ FCS SG_ 2256644609 CLU_RhstaLvlSta 1500;
BA_REL_ "GenSigTimeoutTime" BU_SG_REL_ WPC SG_ 2256644609 CLU_RhstaLvlSta 1500;
BA_REL_ "GenSigTimeoutTime" BU_SG_REL_ RWPC SG_ 2256644609 CLU_RhstaLvlSta 1500;
BA_REL_ "GenSigTimeoutTime" BU_SG_REL_ ARS SG_ 2256644609 CLU_RhstaLvlSta 1500;
BA_REL_ "GenSigTimeoutTime" BU_SG_REL_ SWRC SG_ 2256644609 CLU_RhstaLvlSta 1500;
BA_REL_ "GenSigTimeoutTime" BU_SG_REL_ APSU SG_ 2256644609 CLU_RhstaLvlSta 1500;
BA_REL_ "GenSigTimeoutTime" BU_SG_REL_ RLHV SG_ 2256644609 CLU_RhstaLvlSta 1500;
BA_REL_ "GenSigTimeoutTime" BU_SG_REL_ RRHV SG_ 2256644609 CLU_RhstaLvlSta 1500;
BA_REL_ "GenSigTimeoutTime" BU_SG_REL_ SHVU_FR SG_ 2256644609 CLU_RhstaLvlSta 1500;
BA_REL_ "GenSigTimeoutTime" BU_SG_REL_ SHVU_RR SG_ 2256644609 CLU_RhstaLvlSta 1500;
BA_REL_ "GenSigTimeoutTime" BU_SG_REL_ DPSU SG_ 2256644609 CLU_RhstaLvlSta 1500;
BA_REL_ "GenSigTimeoutTime" BU_SG_REL_ RCS SG_ 2256644609 CLU_RhstaLvlSta 1500;
BA_REL_ "GenSigTimeoutTime" BU_SG_REL_ RRPSU SG_ 2256644609 CLU_RhstaLvlSta 1500;
BA_REL_ "GenSigTimeoutTime" BU_SG_REL_ RLPSU SG_ 2256644609 CLU_RhstaLvlSta 1500;
BA_REL_ "GenSigTimeoutTime" BU_SG_REL_ ATS SG_ 2256644609 CLU_RhstaLvlSta 1500;
BA_REL_ "GenSigTimeoutTime" BU_SG_REL_ DSAU SG_ 2256644609 CLU_RhstaLvlSta 1500;
BA_REL_ "GenSigTimeoutTime" BU_SG_REL_ ASAU SG_ 2256644609 CLU_RhstaLvlSta 1500;
BA_REL_ "GenSigTimeoutTime" BU_SG_REL_ OHCL SG_ 2256644609 CLU_RhstaLvlSta 1500;
BA_REL_ "GenSigTimeoutTime" BU_SG_REL_ WPC2 SG_ 2256644609 CLU_RhstaLvlSta 1500;
BA_REL_ "GenSigTimeoutTime" BU_SG_REL_ APSU SG_ 2256644609 CLU_DisSpdVal 1500;
BA_REL_ "GenSigTimeoutTime" BU_SG_REL_ DPSU SG_ 2256644609 CLU_DisSpdVal 1500;
BA_REL_ "GenSigTimeoutTime" BU_SG_REL_ BLTN_CAM SG_ 2256644609 CLU_DisSpdVal 1500;
BA_REL_ "GenSigTimeoutTime" BU_SG_REL_ EMCU SG_ 2256644609 CLU_DisSpdVal 1500;
BA_REL_ "GenSigTimeoutTime" BU_SG_REL_ WPC2 SG_ 2256644609 CLU_DisSpdVal 1500;
BA_REL_ "GenSigTimeoutTime" BU_SG_REL_ WPC SG_ 2256644610 CLU_DisSpdVal_KPH 1500;
BA_REL_ "GenSigTimeoutTime" BU_SG_REL_ RWPC SG_ 2256644610 CLU_DisSpdVal_KPH 1500;
BA_REL_ "GenSigTimeoutTime" BU_SG_REL_ APSU SG_ 2256644610 CLU_DisSpdVal_KPH 1500;
BA_REL_ "GenSigTimeoutTime" BU_SG_REL_ RLHV SG_ 2256644610 CLU_DisSpdVal_KPH 1500;
BA_REL_ "GenSigTimeoutTime" BU_SG_REL_ RRHV SG_ 2256644610 CLU_DisSpdVal_KPH 1500;
BA_REL_ "GenSigTimeoutTime" BU_SG_REL_ SHVU_FR SG_ 2256644610 CLU_DisSpdVal_KPH 1500;
BA_REL_ "GenSigTimeoutTime" BU_SG_REL_ SHVU_RR SG_ 2256644610 CLU_DisSpdVal_KPH 1500;
BA_REL_ "GenSigTimeoutTime" BU_SG_REL_ DPSU SG_ 2256644610 CLU_DisSpdVal_KPH 1500;
BA_REL_ "GenSigTimeoutTime" BU_SG_REL_ DLBCU SG_ 2256644610 CLU_DisSpdVal_KPH 1500;
BA_REL_ "GenSigTimeoutTime" BU_SG_REL_ PFSU SG_ 2256644610 CLU_DisSpdVal_KPH 1500;
BA_REL_ "GenSigTimeoutTime" BU_SG_REL_ RRPSU SG_ 2256644610 CLU_DisSpdVal_KPH 1500;
BA_REL_ "GenSigTimeoutTime" BU_SG_REL_ RLPSU SG_ 2256644610 CLU_DisSpdVal_KPH 1500;
BA_REL_ "GenSigTimeoutTime" BU_SG_REL_ ATS SG_ 2256644610 CLU_DisSpdVal_KPH 1500;
BA_REL_ "GenSigTimeoutTime" BU_SG_REL_ DSAU SG_ 2256644610 CLU_DisSpdVal_KPH 1500;
BA_REL_ "GenSigTimeoutTime" BU_SG_REL_ ASAU SG_ 2256644610 CLU_DisSpdVal_KPH 1500;
BA_REL_ "GenSigTimeoutTime" BU_SG_REL_ RCM SG_ 2256644610 CLU_DisSpdVal_KPH 1500;
BA_REL_ "GenSigTimeoutTime" BU_SG_REL_ ALBCU SG_ 2256644610 CLU_DisSpdVal_KPH 1500;
BA_REL_ "GenSigTimeoutTime" BU_SG_REL_ WPC2 SG_ 2256644610 CLU_DisSpdVal_KPH 1500;
BA_REL_ "GenSigTimeoutTime" BU_SG_REL_ SWRC SG_ 2256644610 CLU_CUSTOMSta_NEW 1500;
BA_REL_ "GenSigTimeoutTime" BU_SG_REL_ FCS SG_ 2256644610 CLU_AutoBrightSta 1500;
BA_REL_ "GenSigTimeoutTime" BU_SG_REL_ WPC SG_ 2256644610 CLU_AutoBrightSta 1500;
BA_REL_ "GenSigTimeoutTime" BU_SG_REL_ RWPC SG_ 2256644610 CLU_AutoBrightSta 1500;
BA_REL_ "GenSigTimeoutTime" BU_SG_REL_ SWRC SG_ 2256644610 CLU_AutoBrightSta 1500;
BA_REL_ "GenSigTimeoutTime" BU_SG_REL_ APSU SG_ 2256644610 CLU_AutoBrightSta 1500;
BA_REL_ "GenSigTimeoutTime" BU_SG_REL_ RLHV SG_ 2256644610 CLU_AutoBrightSta 1500;
BA_REL_ "GenSigTimeoutTime" BU_SG_REL_ RRHV SG_ 2256644610 CLU_AutoBrightSta 1500;
BA_REL_ "GenSigTimeoutTime" BU_SG_REL_ SHVU_FR SG_ 2256644610 CLU_AutoBrightSta 1500;
BA_REL_ "GenSigTimeoutTime" BU_SG_REL_ SHVU_RR SG_ 2256644610 CLU_AutoBrightSta 1500;
BA_REL_ "GenSigTimeoutTime" BU_SG_REL_ DPSU SG_ 2256644610 CLU_AutoBrightSta 1500;
BA_REL_ "GenSigTimeoutTime" BU_SG_REL_ RCS SG_ 2256644610 CLU_AutoBrightSta 1500;
BA_REL_ "GenSigTimeoutTime" BU_SG_REL_ ATS SG_ 2256644610 CLU_AutoBrightSta 1500;
BA_REL_ "GenSigTimeoutTime" BU_SG_REL_ DSAU SG_ 2256644610 CLU_AutoBrightSta 1500;
BA_REL_ "GenSigTimeoutTime" BU_SG_REL_ ASAU SG_ 2256644610 CLU_AutoBrightSta 1500;
BA_REL_ "GenSigTimeoutTime" BU_SG_REL_ OHCL SG_ 2256644610 CLU_AutoBrightSta 1500;
BA_REL_ "GenSigTimeoutTime" BU_SG_REL_ BLTN_CAM SG_ 2256644610 CLU_AutoBrightSta 1500;
BA_REL_ "GenSigTimeoutTime" BU_SG_REL_ WPC2 SG_ 2256644610 CLU_AutoBrightSta 1500;
BA_REL_ "GenSigTimeoutTime" BU_SG_REL_ CGW_CCU SG_ 350 DSAU_AirSptTimeRValueSet 1500;
BA_REL_ "GenSigTimeoutTime" BU_SG_REL_ CGW_CCU SG_ 350 DSAU_DrvSmtAirSptRValueSet 1500;
BA_REL_ "GenSigTimeoutTime" BU_SG_REL_ CGW_CCU SG_ 350 DSAU_CushSoftRValueSet 1500;
BA_REL_ "GenSigTimeoutTime" BU_SG_REL_ CGW_CCU SG_ 350 DSAU_AirSptModeRValueSet 1500;
BA_REL_ "GenSigTimeoutTime" BU_SG_REL_ CGW_CCU SG_ 350 DSAU_MsgModeSts 1500;
BA_REL_ "GenSigTimeoutTime" BU_SG_REL_ CGW_CCU SG_ 350 DSAU_MsgModeStrength 1500;
BA_REL_ "GenSigTimeoutTime" BU_SG_REL_ CGW_CCU SG_ 350 DSAU_MoodTrpyRValueSet 1500;
BA_REL_ "GenSigTimeoutTime" BU_SG_REL_ CGW_CCU SG_ 350 DSAU_MoodTrpyCareSta 1500;
BA_REL_ "GenSigTimeoutTime" BU_SG_REL_ CGW_CCU SG_ 350 DSAU_MoodTrpyComfSta 1500;
BA_REL_ "GenSigTimeoutTime" BU_SG_REL_ CGW_CCU SG_ 350 DASU_AirSptStrRValueSet 1500;
BA_REL_ "GenSigTimeoutTime" BU_SG_REL_ CGW_CCU SG_ 349 DSAU_CushInfDis 1500;
BA_REL_ "GenSigTimeoutTime" BU_SG_REL_ CGW_CCU SG_ 349 DSAU_CushDefDis 1500;
BA_REL_ "GenSigTimeoutTime" BU_SG_REL_ CGW_CCU SG_ 348 DSAU_BolsterInfDis 1500;
BA_REL_ "GenSigTimeoutTime" BU_SG_REL_ CGW_CCU SG_ 348 DSAU_BolsterDefDis 1500;
VAL_ 273 ARS_RrCurtainBtn 0 "Default" 1 "Open ON" 2 "Close ON" 3 "Invalid" ;
VAL_ 287 APSS_LumbarUpSw 0 "Default" 1 "Off" 2 "On" 3 "Invalid" ;
VAL_ 287 APSS_LumbarMidSw 0 "Default" 1 "Off" 2 "On" 3 "Invalid" ;
VAL_ 287 APSS_LumbarLowSw 0 "Default" 1 "Off" 2 "On" 3 "Invalid" ;
VAL_ 287 APSS_LumbarDefSw 0 "Default" 1 "Off" 2 "On" 3 "Invalid" ;
VAL_ 287 APSS_BolsterInfSw 0 "Default" 1 "Off" 2 "On" 3 "Invalid" ;
VAL_ 287 APSS_BolsterDefSw 0 "Default" 1 "Off" 2 "On" 3 "Invalid" ;
VAL_ 287 APSS_ActiveSw 0 "Off" 1 "On" 2 "Not Used" 3 "Error" ;
VAL_ 287 APSS_CushInfSw 0 "Off" 1 "On" 2 "Not Used" 3 "Error" ;
VAL_ 287 APSS_CushDefSw 0 "Off" 1 "On" 2 "Not Used" 3 "Error" ;
VAL_ 287 APSS_CushOnOffTch 0 "Default" 1 "Off" 2 "On(Off State)" 3 "On(Mode1 State)" 4 "On(Mode2 State)" 5 "On(Mode3 State)" 6 "Reserved" 7 "Invalid" ;
VAL_ 2193667332 ENG_VehSpdHiVal 511 "Error indicator" ;
VAL_ 2193667332 ENG_EngInhbNCC 0 "NCC Inhibition OFF" 1 "NCC Inhibition ON" 2 "Not used" 3 "Error indicator" ;
VAL_ 2193667332 ENG_SldSwSta 0 "Speed limiter function is OFF" 1 "Speed limiter function is Active(Kickdown)" 2 "Speed limiter function is Pause" 3 "Error indicator" ;
VAL_ 2193667332 ENG_SldDrvAlertDisp 0 "Default" 1 "SldDisengaged" 2 "NoSldEngaged" 3 "ErrorIndicator" ;
VAL_ 2193667332 ENG_VehSpdLimVal 511 "Error indicator" ;
VAL_ 2193667331 ENG_TrgtIdleRpmVal 255 "Error indicator" ;
VAL_ 2193667331 ENG_GearShftDnDis 0 "Gear Shiftdown Display Off" 1 "Gear Shiftdown Display On" 2 "Not used" 3 "Error indicator" ;
VAL_ 2193667331 ENG_DsrGearPosDis 0 "No display" 1 "Gear Position 1 display" 2 "Gear Position 2 display" 3 "Gear Position 3 display" 4 "Gear Position 4 display" 5 "Gear Position 5 display" 6 "Gear Position 6 display" 7 "Gear Position 7 display" 8 "Gear Position 8 display" 9 "Gear Position 9 display" 10 "Gear Position 10 display" 15 "Error indicator" ;
VAL_ 2193667331 ENG_SldFuncSta 0 "Speed limiter function is not active" 1 "Speed limiter function is active" 2 "Not used" 3 "Error indicator" ;
VAL_ 2193667331 ENG_SldActnSta 0 "Positive action is not active" 1 "Positive action is active" 2 "Not used" 3 "Error indicator" ;
VAL_ 2193667331 ENG_FuelTnkPrsrSta 0 "Fuel Tank is not in high Pressure" 1 "Fuel Tank is in high Pressure" 2 "Not used" 3 "Error indicator" ;
VAL_ 2193667331 ENG_IsgBzrReq 0 "Request buzzer OFF" 1 "Request buzzer ON" 2 "Not used" 3 "Error indicator" ;
VAL_ 2193667331 ENG_IsgFuelCnsmptDis 0 "Not fuel consumption" 1 "Fuel consumption(=1mL)" 2 "Not used" 3 "Error indicator" ;
VAL_ 2193667331 ENG_FuelCapOpnSta 0 "Fuel cap isn't opened" 1 "Fuel cap is opened" 2 "Not used" 3 "Error indicator" ;
VAL_ 2193667331 ENG_EcoDrvActvSta 0 "Active Eco Drive is not active" 1 "Active Eco Drive is active" 2 "Not used" 3 "Error indicator" ;
VAL_ 2193667331 ENG_EngRunSta 0 "Engine Stop or Starting Phase" 1 "Engine Running" 2 "Not used" 3 "Error indicator" ;
VAL_ 2193667331 ENG_Isg2Sta 0 "Default" 1 "The condition for not-activated battery sensor. (Except EOL condition.)" 2 "In Auto Start status, when rapidly accelerating before complete gear shift. (Economy ISG Only)" 3 "Error indicator" ;
VAL_ 2193667331 ENG_IgnOnSta 0 "KEY OFF, control unit in self-holding phase" 1 "KEY ON" 2 "Not used" 3 "Error indicator" ;
VAL_ 2193667331 ENG_Ack4TcsSta 0 "TCS message not received within the last 500 ms, or a plausibility error in torque intervention is ON" 1 "TCS message received, and no plausibility error" 2 "Not used" 3 "Error indicator" ;
VAL_ 2193667331 ENG_FuelCutOffSta 0 "Engine not in fuel cut off" 1 "Engine in fuel cut off" 2 "Not used" 3 "Error indicator" ;
VAL_ 2193667331 ENG_CrctTqSta 0 "The desired intervention regarding ignition angle retardation and cylinder shut-off is executed. (Default value)" 1 "The desired intervention regarding ignition angle retardation and cylinder shut-off is executed; however, the requested target torque can not be adjusted precisely (torque steps)" 2 "The torque reduction regarding the ignition angle retardation cannot be completely executed. A cylinder shut-off is not possible at this time." 3 "Due to a failure detected the desired torque intervention for TCS regarding the ignition angle and cylinder shut-off is no longer executed." ;
VAL_ 2193667331 ENG_AirCompRlySta 0 "Air conditioner compressor relay OFF" 1 "Air conditioner compressor relay ON" 2 "Not used" 3 "Error indicator" ;
VAL_ 2193667331 ENG_LnchCntrlSta 0 "Off state" 1 "Standby" 2 "Ready" 3 "Lanch" 4 "Error indicator" ;
VAL_ 2193667331 ENG_GearShftUpDis 0 "Gear Shiftup Display Off" 1 "Gear Shiftup Display On" 2 "Not used" 3 "Error indicator" ;
VAL_ 2193667330 ENG_EngSpdErrSta 0 "No error" 1 "Engine speed sensor defective" 2 "Not used" 3 "Error indicator" ;
VAL_ 2193667330 ENG_MafErrSta 0 "No error" 1 "Error on Torque Measurement" 2 "Not used" 3 "Error indicator" ;
VAL_ 2193667330 ENG_EtcLmphModSta 0 "Engine control is available" 1 "ETC Limphome mode by ECU" 2 "Not used" 3 "Error indicator" ;
VAL_ 2193667330 ENG_SpltInjctnSta 0 "Split injection OFF" 1 "Split injection ON" 2 "Not used" 3 "Error indicator" ;
VAL_ 2193667330 ENG_MaxAirconTqVal 255 "Error indicator" ;
VAL_ 2193667330 ENG_AirconPrsrSnsrVal 255 "Error indicator" ;
VAL_ 2193667330 ENG_IsgSta 0 "ISG is not operating Normal engine operating without ISG" 1 "Idle stop is activated Idle is stopped by ECU during driving" 2 "Automatically started by ECU Engine is automatically started by ECU regardless driver¡¯s volition during idle stop because the condition that ISG function to be prohibited is satisfied, for example SOC is too low." 3 "ISG is prohibited Driver prohibits to activate ISG in order to avoid start lag when he met traffic jam for example." 4 "Fault  existing in ISG. Idle stop is prohibited and engine started automatically if it is idle stop condition." 5 "Idle stop is inhibited by system automatically for safety and  convenient condition related with battery SOC, brake vacuum pressure etc. ISG function check for EOL." 6 "Auto start is deactivated system automatically to keep safety, Such as door open, hood open and seat belt unlock." 7 "If driver shift gear N to D range without braking to make auto starting. (Economy ISG Only)" ;
VAL_ 2193667330 ENG_OilLvlSta 0 "OIL LEVEL LAMP Off" 1 "OIL LEVEL LAMP On" 2 "Not used" 3 "Error indicator" ;
VAL_ 2193667329 EMS_Crc1Val 0 "0x0x0~0xFFFF:CRCValue" 65535 "0x0x0~0xFFFF:CRCValue" ;
VAL_ 2193667329 EMS_AlvCnt1Val 0 "0x0x0~0xFF:AlvCntValue" 255 "0x0x0~0xFF:AlvCntValue" ;
VAL_ 2395189761 DATC_Crc10Val 0 "0x0x0~0xFFFF:CRCValue" 65535 "0x0x0~0xFFFF:CRCValue" ;
VAL_ 2395189761 DATC_AlvCnt10Val 0 "0x0x0~0xFF:AlvCntValue" 255 "0x0x0~0xFF:AlvCntValue" ;
VAL_ 2395189761 DATC_Typ 255 "Error Indicator" ;
VAL_ 2395189761 DATC_Opt1Typ 255 "Error Indicator" ;
VAL_ 2395189761 DATC_Opt3Typ 255 "Error Indicator" ;
VAL_ 2395189761 DATC_Opt2Typ 15 "Error Indicator" ;
VAL_ 2395189761 DATC_TxtPopupReq 0 "Off" 1 "TEXT POP-UP Request On" 2 "reserverd" 3 "Error Indicator" ;
VAL_ 2395189761 DATC_StrWhlUSMSta 0 "NOT APPLY" 1 "OFF" 2 "ON" 3 "Error Indicator" ;
VAL_ 2395189761 DATC_StrWhlHtngReq 0 "Default" 1 "Integrated control OFF" 2 "Steering Wheel heat OFF" 3 "Steering Wheel heat 1st ON" 4 "Steering Wheel heat 1st & 2nd ON" 5 "Reserved" 6 "Reserved" 7 "Invalid" ;
VAL_ 2244048129 ESC_Crc3Val 0 "0x0x0~0xFFFF:CRCValue" 65535 "0x0x0~0xFFFF:CRCValue" ;
VAL_ 2244048129 ESC_AlvCnt3Val 0 "0x0x0~0xFF:AlvCntValue" 255 "0x0x0~0xFF:AlvCntValue" ;
VAL_ 2244048129 ESC_VehAccelVal 2047 "Error" ;
VAL_ 2244048129 ESC_AccelBasisVal 2047 "Error" ;
VAL_ 2244048129 PWI_STATE 0 "nomarl" 1 "pad wear" 2 "reserved" 3 "invaild or Error" ;
VAL_ 271 ASAU_AirSptTimeRValueSet 0 "Default" 1 "Short" 2 "Normal" 3 "Long" 4 "Reserved" 5 "Reserved" 6 "Reserved" 7 "Reserved" ;
VAL_ 271 ASAU_AstSmtAirSptRValueSet 0 "Default" 1 "Off" 2 "On" 3 "Invalid" ;
VAL_ 271 ASAU_CushSoftRValueSet 0 "Default" 1 "Off" 2 "Soft" 3 "Mid" 4 "Hard" 5 "Reserved" 6 "Reserved" 7 "Reserved" ;
VAL_ 271 ASAU_BackSoftRValueSet 0 "Default" 1 "Off" 2 "Soft" 3 "Mid" 4 "Hard" 5 "Reserved" 6 "Reserved" 7 "Reserved" ;
VAL_ 271 ASAU_AirSptModeRValueSet 0 "Default" 1 "Mode 1" 2 "Mode 2" 3 "Mode 3" 4 "Mode 4" 5 "Mode 5" 6 "Reserved" 7 "Reserved" ;
VAL_ 271 ASAU_NotFootMsgOperStaWarnPE 0 "Default" 1 "Off (Disable)" 2 "On (Enable)" 3 "Invalid" ;
VAL_ 271 ASAU_RRFootAirSptRValueSet 0 "Default" 1 "Off" 2 "On" 3 "Invalid" ;
VAL_ 271 ASAU_RRFootAirSptHeatRValueSet 0 "Default" 1 "Off" 2 "On" 3 "Invalid" ;
VAL_ 271 ASAU_MoodTrpyRValueSet 0 "Default" 1 "Off" 2 "On" 3 "Invalid" ;
VAL_ 271 ASAU_MoodTrpyCareSta 0 "Default" 1 "Off" 2 "On" 3 "Invalid" ;
VAL_ 271 ASAU_MoodTrpyComfSta 0 "Default" 1 "Off" 2 "On" 3 "Invalid" ;
VAL_ 271 ASAU_AirSptStrRValueSet 0 "Default" 1 "Low" 2 "Mid" 3 "High" 4 "Off" 5 "Reserved" 6 "Reserved" 7 "Reserved" ;
VAL_ 2244048131 ESC_RccaSta 0 "RCCA availble" 1 "RCCA brake started" 2 "RCCA braking is ended" 3 "RCCA braking error" ;
VAL_ 2244048131 ESC_RspaCanFlFlag 0 "ESC received RSPA CAN message successfully" 1 "ESC failed to receive RSPA CAN message successfully" 2 "Not used" 3 "Error Indicator" ;
VAL_ 2244048131 ESC_RspaDclActv 0 "Inactive" 1 "Active" 2 "Not used" 3 "Error Indicator" ;
VAL_ 2244048131 ESC_RspaStandStill 0 "Initial" 1 "ESC stopped the vehicle by RSPA request" 2 "Not used" 3 "Error Indicator" ;
VAL_ 2244048131 ESC_PcaSta 0 "PCA available" 1 "PCA brake started" 2 "PCA brake ended" 3 "PCA disable" ;
VAL_ 2244048131 MCB_ReqBrkAck 0 "Wait Status for Crash" 1 "Received ACU Crash Information" 2 "Not used" 3 "Not used" ;
VAL_ 2244048131 MCB_CtlSta 0 "Not Activation" 1 "Activation" ;
VAL_ 2244048131 MCB_DefSta 0 "Normal state" 1 "Fail" ;
VAL_ 2244048131 ESC_DiffBrkFuncSta 0 "Differential braking available without error" 1 "Differential braking disable" 2 "Differential braking is activated" 3 "Error Indicator" ;
VAL_ 2244048131 ESC_LsdLimMod 0 "Maximum limitation mode" 1 "Minimum limitation mode" ;
VAL_ 2244048131 ESC_LsdOpn 0 "Passive" 1 "Fast Open" 2 "Slow Open" 3 "Torque Limit" 4 "eLSD Fail OPEN" 5 "Reserved" 6 "Reserved" 7 "Error" ;
VAL_ 2244048131 ESC_BcaRPlusSta 0 "BCA-R+ available" 1 "BCA-R+ braking is started" 2 "BCA-R+ braking is ended" 3 "BCA-R+ braking error" ;
VAL_ 2244048131 ESC_RspaSta 0 "Not used" 1 "ESC Initial" 2 "ESC New Start" 3 "ESC Ready" 4 "Not used" 5 "ESC Assist" 6 "ESC Assist Fail" 7 "ESC Abort" 8 "ESC Ready Fail" ;
VAL_ 2244048130 SCC_OptTyp 0 "SCC is not equipped" 1 "SCC is equipped" 2 "Not used" 3 "Not Coded" ;
VAL_ 2244048130 ESC_BrkLtReq 0 "No request" 1 "Activate brake lights" 2 "Not used" 3 "Error Indicator" ;
VAL_ 2244048130 ESC_DclEnblReq 0 "Disable deceleration control" 1 "Enable deceleration control" 2 "Not used" 3 "Error Indicator" ;
VAL_ 2244048130 ESC_DrvOvrdSta 0 "No override" 1 "Override by acceleration pedal" 2 "Override by deceleration" 3 "Error Indicator" ;
VAL_ 2244048130 ESC_DrvBrkSta 0 "Driver is not braking / failure" 1 "Driver is braking" 2 "Not used" 3 "Error Indicator" ;
VAL_ 2244048130 SCC_EnblReq 0 "SCC enabled" 1 "SCC disabled reversible" 2 "SCC disabled irreversible" 3 "SCC disabled irreversible due to communication error" ;
VAL_ 2244048130 ESC_DrvBrkActvSta 0 "Brake pedal not pressed" 1 "Brake pedal pressed" 2 "Not used" 3 "Error Indicator" ;
VAL_ 2244048130 ESC_PrkBrkActvSta 0 "Parking brake is not activated" 1 "Parking brake is activated" 2 "Not used" 3 "Error Indicator" ;
VAL_ 2244048130 ESC_HDP_FltMonSta 0 "No Fault" 1 "Main Controller Fault Detected (ADAS_DRV 2)" 2 "Sub Controller Fault Detected (FR_CMR)" 3 "Main & Sub Controller Fault Detected (ADAS_DRV 2 & FR_CMR)" 4 "Reserved" 5 "Reserved" 6 "Reserved" 7 "Reserved" ;
VAL_ 2244048130 ESC_HDPSpprtSWVer 0 "Not Supported" 1 "SW Version" 2 "SW Version" 3 "SW Version" 4 "SW Version" 5 "SW Version" 6 "SW Version" 7 "SW Version" 8 "SW Version" 9 "SW Version" 10 "SW Version" 11 "SW Version" 12 "SW Version" 13 "SW Version" 14 "SW Version" 15 "SW Version" 16 "SW Version" 17 "SW Version" 18 "SW Version" 19 "SW Version" 20 "SW Version" 21 "SW Version" 22 "SW Version" 23 "SW Version" 24 "SW Version" 25 "SW Version" 26 "SW Version" 27 "SW Version" 28 "SW Version" 29 "SW Version" 30 "SW Version" 31 "SW Version" ;
VAL_ 2244048130 FCA_EquipSta 0 "FCA is not equipped" 1 "FCA is equipped" 2 "Not used" 3 "Not Coded" ;
VAL_ 2244048130 FCA_AvlblSta 0 "Available" 1 "Temporarily not available" 2 "Permanently not available" 3 "FCA Communication Error" ;
VAL_ 2244048130 ESC_FCA_ActvSta 0 "FCA Brake is not in activation" 1 "FCA Pre-Brake" 2 "FCA Full-Brake" 3 "Invalid" ;
VAL_ 2244048130 ESC_DBS_ActvSta 0 "DBS control is inactive" 1 "DBS control is active" 2 "Not used" 3 "Not used" ;
VAL_ 2244048130 SCC_TqReq 0 "No request" 1 "Enable SCC torque request" 2 "Not used" 3 "Error Indicator" ;
VAL_ 2244048130 ESC_HDP_EgSta 0 "Not engaged" 1 "Engaged in main controller by IEB (ESC)" 2 "Engaged in sub controller by IEB (ESC)" 3 "MRM with IEB (ESC) alone" 4 "Engaged in main controller by RCU" 5 "Engaged in sub controller by RCU" 6 "MRM with RCU alone" 7 "Engaged in sub controller by IEB (ESC), but RCU Signa" ;
VAL_ 2244048130 ESC_HDP_EnblReq 0 "No Fault" 1 "Req. longitudinal control normal, Functional Fault" 2 "Req. longitudinal control normal, Partial performance degradation" 3 "Req. longitudinal control abnormal, Brake control possible" 4 "Req. longitudinal control abnormal, Brake control impossible" 5 "Req. longitudinal control normal, Acceleration control Fault (eg. Engine Fault)" 6 "HDP disabled reversible" 7 "Reserved" ;
VAL_ 2244048130 CSC_Sta 0 "Not Control(Default)" 1 "Control" 2 "Reserved" 3 "Error Indicator" ;
VAL_ 2244048130 CSC_WrngSta 0 "Not Control(Default)" 1 "Control" 2 "Reserved" 3 "Error Indicator" ;
VAL_ 2244048130 ESC_BrkdFltStndstill 0 "Undetected" 1 "Detected" 2 "Not used" 3 "Not used" ;
VAL_ 2244048130 SCC_ReqLimSta 0 "No request" 1 "Limited No Limitation" 2 "Acceleration Limited" 3 "Deceleration Limited" ;
VAL_ 2244048130 ESC_StdStillVal 0 "No stand still detected" 1 "stand still detected" 2 "Not used" 3 "Error Indicator" ;
VAL_ 2189467649 WHL_Crc1Val 0 "0x0x0~0xFFFF:CRCValue" 65535 "0x0x0~0xFFFF:CRCValue" ;
VAL_ 2189467649 WHL_AlvCnt1Val 0 "0x0x0~0xFF:AlvCntValue" 255 "0x0x0~0xFF:AlvCntValue" ;
VAL_ 2189467649 WHL_PlsFLVal 255 "Error" ;
VAL_ 2189467649 WHL_PlsFRVal 255 "Error" ;
VAL_ 2189467649 WHL_PlsRLVal 255 "Error" ;
VAL_ 2189467649 WHL_PlsRRVal 255 "Error" ;
VAL_ 2189467649 WHL_DirFLVal 0 "Unknown (Wheel moving stop state or Not applied wheel sensor for direction)" 1 "Forward direction" 2 "Backward direction" 3 "Error identifier" ;
VAL_ 2189467649 WHL_DirFRVal 0 "Unknown (Wheel moving stop state or Not applied wheel sensor for direction)" 1 "Forward direction" 2 "Backward direction" 3 "Error identifier" ;
VAL_ 2189467649 WHL_DirRLVal 0 "Unknown (Wheel moving stop state or Not applied wheel sensor for direction)" 1 "Forward direction" 2 "Backward direction" 3 "Error identifier" ;
VAL_ 2189467649 WHL_DirRRVal 0 "Unknown (Wheel moving stop state or Not applied wheel sensor for direction)" 1 "Forward direction" 2 "Backward direction" 3 "Error identifier" ;
VAL_ 2164277252 TCU_NetrlCtrlSta 0 "No NC" 1 "NC Entry" 2 "NC Applied" 3 "NC Exit" ;
VAL_ 2164277252 TCU_ShftPtrnSta 0 "Normal (ECO)" 1 "Uphill 1 (Optional)" 2 "Uphill 2 (Optional)" 3 "Reserved" 4 "Downhill 1 (Optional)" 5 "Cruise (Optional)" 6 "Cruise_Uphill 1 (Optional)" 7 "Cruise_Uphill 2 (Optional)" 8 "Active ECO (Optional)" 9 "Sport Drive (Optional)" 15 "None of the above" ;
VAL_ 2164277252 TCU_EPBReq 0 "No Request (default)" 1 "EPB Request" ;
VAL_ 2164277252 IMT_EOLstate 0 "display gear info using 'TCU_GearSlctDis'" 1 "display gear info by alphabet 'E'" ;
VAL_ 2164277252 IMT_DisCmd 0 "Not Display" 1 "Display (Not blinking)" 2 "Display (blinking)" 3 "Reserved" ;
VAL_ 2164277252 DCT_RegenInhbt 0 "No Inhibit" 1 "Regen. Inhibit" 2 "Not Used" 3 "Error Indicator" ;
VAL_ 2164277252 DCT_EngIdleReq 0 "No Request" 1 "Idle Request" 2 "Not Used" 3 "Error Indicator" ;
VAL_ 2164277252 DCT_CltchState 0 "Drivetrain (Both Clutch) Open" 1 "Odd Clutch Slipping" 2 "Even Clutch Slipping" 3 "Clutch Locked" ;
VAL_ 2164277252 DCT_FuelCutReq 0 "No request" 1 "Fuel Cut Request" 2 "Not Used" 3 "Error Indicator" ;
VAL_ 2164277252 DCT_TqIncReq 0 "No Request" 1 "Torque increase Request" 2 "Not Used" 3 "Error Indicator" ;
VAL_ 2164277252 DCT_ShftTqReq 0 "No request" 2047 "Max. Increase" 2048 "reduction to 0 torque" ;
VAL_ 2164277252 TCU_VgisInhbtReq 0 "There¡¯s no request from TCU" 1 "TCU inhibits ECU from changing VGIS status" 2 "Not used" 3 "Error Indicator" ;
VAL_ 2164277252 TCU_EngTqIncReqVal 0 "No request" 2047 "Max. Increase" 2048 "reduction to 0 torque" ;
VAL_ 2189467650 WHL_SpdFLVal 16383 "Error" ;
VAL_ 2189467650 WHL_SpdFRVal 16383 "Error" ;
VAL_ 2189467650 WHL_SpdRLVal 16383 "Error" ;
VAL_ 2189467650 WHL_SpdRRVal 16383 "Error" ;
VAL_ 2164277249 TCU_GearSlctDis 0 "P" 1 "L" 2 "2" 3 "3" 4 "DS Mode" 5 "D" 6 "N" 7 "R" 8 "sports mode / manual shift / paddle shift" 9 "Not Display at Cluster" 10 "Sub-Rom Communication" 11 "Sub-Rom Communication Error" 12 "Paddle shift (D-position)" 13 "Reserved" 14 "Intermediate Position" 15 "fault" ;
VAL_ 2164277249 TCU_Typ 0 "Reserved" 1 "Step A" 2 "CVT" 3 "DCT" 4 "AMT" 5 "eClutch (2pedal)" 6 "eClutch (3pedal)" ;
VAL_ 2164277249 TCU_TqRdctnVal 0 "Max. reduction" 2047 "No reduction" 2048 "reduction to 0 torque" ;
VAL_ 2164277249 TCU_GearStepTyp 3 "3 - Speed AT or DCT" 4 "4 - Speed AT or DCT" 5 "5 - Speed AT or DCT" 6 "6 - Speed AT or DCT" 7 "7- Speed AT or DCT" 8 "8 - Speed AT or DCT" ;
VAL_ 2164277249 TCU_GearShftSta 0 "no gear change" 1 "gear change is active" 2 "Not used" 3 "Error Indicator" ;
VAL_ 2164277249 TCU_TqCnvrtrSta 0 "No lock up control" 1 "Slip lock up" 2 "Fully lock up" 3 "Off slip lock up" ;
VAL_ 2164277251 TCU_EngRpmDis 65535 "Error Indicator" ;
VAL_ 2164277251 TCU_EngSpdIncReq 0 "No request" 1 "Engine speed increase is requested" 2 "Not used" 3 "Error Indicator" ;
VAL_ 2164277251 TCU_ObdSta 0 "Default" 2 "Failure information of TCU" 3 "Failure information of TCU" 4 "MIL on request" 5 "MIL on request" 6 "Failure information of TCU & MIL on request" 7 "Failure information of TCU & MIL on request" ;
VAL_ 2164277251 TCU_SprtyIndxSta 0 "Invalid" 1 "Step 1" 2 "Step 2" 3 "Step 3" 4 "Step 4" 5 "Step 5" 6 "Step 6" 7 "Step 7" 8 "Step 8" 9 "Step 9" 10 "Step 10" 11 "Step 11" 12 "Step 12" 13 "Step 13" 14 "Step 14" 15 "Step 15" 16 "Step 16" 17 "Step 17" 18 "Step 18" 19 "Step 19" 20 "Step 20" 21 "Step 21" 22 "Step 22" 23 "Step 23" 24 "Step 24" 25 "Step 25" 26 "Invalid" 27 "Invalid" 28 "Invalid" 29 "Invalid" 30 "Invalid" 31 "Invalid" ;
VAL_ 2164277251 TCU_DrvngModDis 0 "Inactive" 1 "Normal" 2 "Eco" 3 "Eco+" 4 "Sport" 5 "Sport+" 6 "Snow" 7 "Reserved" ;
VAL_ 2164277251 TCU_DrvngModReq 0 "Inactive" 1 "Normal" 2 "Eco" 3 "Eco+" 4 "Sport" 5 "Sport+" 6 "Snow" 7 "Reserved" ;
VAL_ 2164277251 TCU_SmrtShftSta 0 "Smart Shift not Applied" 1 "Smart Shift Applied" 2 "Not used" 3 "Error Indicator" ;
VAL_ 2164277251 TCU_FrtStcShftSta 0 "First static shift function is not activated." 1 "First static shift function is activated" 2 "Not used" 3 "Error Indicator" ;
VAL_ 2164277251 TCU_IsgInhbtReq 0 "TCU inhibits the ISG function" 1 "ISG is available" 2 "Not used" 3 "Error Indicator" ;
VAL_ 2164277251 TCU_CdaInhbtReq 0 "CDA transition is available" 1 "TCU prohibits CDA transition" 2 "Not used" 3 "Error Indicator" ;
VAL_ 2164277251 TCU_BrkOnReq 0 "No request" 1 "Brake On Request" 2 "Not used" 3 "Error Indicator" ;
VAL_ 2164277251 TCU_TqGrdntLimVal 255 "No torque gradient limitation" ;
VAL_ 2164277250 TCU_CurrGearSta 0 "if N or P are detected (no frictional connection)" 1 "1st speed" 2 "2nd speed" 3 "3rd speed" 4 "4th speed" 5 "5th speed" 6 "6th speed" 7 "7th speed" 8 "8th speed" 14 "Reverse speed" ;
VAL_ 2164277250 TCH_EngTrgtGearSta 0 "if N or P are detected (no frictional connection)" 1 "1st speed" 2 "2nd speed" 3 "3rd speed" 4 "4th speed" 5 "5th speed" 6 "6th speed" 7 "7th speed" 8 "8th speed" 14 "Reverse speed" ;
VAL_ 2164277250 TCU_EngTqLimVal 0 "Max. reduction" 2047 "No reduction" 2048 "reduction to 0 torque" ;
VAL_ 2164277250 TCU_CluTrgtGearConfg 0 "TCU_TrgtGearSta" 1 "TCU_CluTrgtGearSta" 2 "Not Used" 3 "Error Indicator" ;
VAL_ 2164277250 TCU_VehSpdKphVal 255 "Error Indicator" ;
VAL_ 2164277250 TCU_TrgtGearSta 0 "if N or P are detected (no frictional connection)" 1 "1st speed" 2 "2nd speed" 3 "3rd speed" 4 "4th speed" 5 "5th speed" 6 "6th speed" 7 "7th speed" 8 "8th speed" 14 "Reverse speed" ;
VAL_ 2164277250 TCU_DcmlVehSpdKphVal 0 "Error Indicator" ;
VAL_ 2164277250 TCU_GearLmpBlnkngReq 0 "No blink" 1 "Request lamp blinking" 2 "Not used" 3 "Error Indicator" ;
VAL_ 2164277250 TCU_FuelCutInhbtReq 0 "No request" 1 "Fuel cut inhibition request from TCU" 2 "Not used" 3 "Error Indicator" ;
VAL_ 2164277250 TCU_IdleUpReq 0 "No IDLE UP request" 1 "IDLE UP request" 2 "Not used" 3 "Error Indicator" ;
VAL_ 2164277250 TCU_CluTrgtGearSta 0 "if N or P are detected (no frictional connection)" 1 "1st speed" 2 "2nd speed" 3 "3rd speed" 4 "4th speed" 5 "5th speed" 6 "6th speed" 7 "7th speed" 8 "8th speed" 14 "Reverse speed" ;
VAL_ 2239848450 FCA_RelVel 511 "Signal Invalid" ;
VAL_ 2239848450 Nmode_FCAOff_Sta 0 "Not Applied" 1 "Disable" 2 "Enable" 3 "Invalid" ;
VAL_ 2239848450 FCA_Jnctn_OnOffEquipSta 0 "Default" 1 "Off" 2 "On" 3 "Invalid" ;
VAL_ 2239848450 HDP_EMOpSta 0 "Off" 1 "On (Not Active)" 2 "On (Active)" 3 "Reserved" 4 "Reserved" 5 "Reserved" 6 "Reserved" 7 "Error indicator" ;
VAL_ 2239848450 FCA_WrngTrgtDis 0 "None" 1 "FCA-Pedestrian" 2 "Reserved" 3 "FCA-Cyclist" 4 "Reserved" 5 "FCA-Car" 6 "Reserved" 7 "FCA-JC (L)" 8 "FCA-JC (R)" 9 "Reserved" 10 "Reserved" 11 "FCA-JT (L)" 12 "FCA-JT (R)" 13 "Reserved" 14 "Reserved" ;
VAL_ 2239848450 ADAS_DRV_FCA_Plus_Sta 0 "FCA-Car/Ped/Cyc+ »óÈ² ¹ÌÇØ´ç" 1 "FCA-Car/Ped/Cyc+ »óÈ² ÇØ´ç" 2 "Not Used" 3 "Error Indicator" ;
VAL_ 2239848450 ADAS_TrlOffStaDisp 0 "Normal" 1 "Auto Off by Trailer connected" 2 "Reserved" 3 "Reserved" ;
VAL_ 2239848450 FCA_FrOnOffEquipSta 0 "Default" 1 "Off" 2 "On" 3 "Invalid" ;
VAL_ 2239848450 FCA_JC_OnOffEquipSta 0 "Default" 1 "Off" 2 "On" 3 "Invalid" ;
VAL_ 2239848450 FCA_FrSdOnOffEquipSta 0 "Default" 1 "Off" 2 "On" 3 "Invalid" ;
VAL_ 2239848450 EM_WrngLvlSta 0 "No warning" 1 "Prefill (Warning level1)" 2 "Partial brake (Warning level2)" 3 "Full brake (Warning level3)" 4 "Reserved" 5 "Reserved" 6 "Reserved" 7 "Error indicator" ;
VAL_ 2239848450 BrkDelVLimReq 0 "Delta V limit required (Release brake control over ¥ÄV 50km/h)" 1 "Delta V limit not required w/ additional signal (Not release brake control)" 2 "Delta V limit not required w/o additional signal (Not release brake control)" 3 "Reserved" 4 "Reserved" 5 "Reserved" 6 "Reserved" 7 "Error indicator" ;
VAL_ 2239848450 ADAS_InhbtOffDispSta 0 "Default" 1 "Inhibit off in regulation (Cluster)" 2 "Inhibit off in regulation (H/UNIT)" 3 "Inhibit off in HDP (Cluster)" 4 "Reserved" 5 "Reserved" 6 "Reserved" 7 "Invalid" ;
VAL_ 2239848450 FCA_WarnTimeSta 0 "Default" 1 "Late" 2 "Normal" 3 "Reserved" 4 "Reserved" 5 "Reserved" 6 "Reserved" 7 "Invalid" ;
VAL_ 2239848449 ADAS_CMD_Crc10Val 0 "0x0x0~0xFFFF:CRCValue" 65535 "0x0x0~0xFFFF:CRCValue" ;
VAL_ 2239848449 ADAS_CMD_AlvCnt10Val 0 "0x0x0~0xFF:AlvCntValue" 255 "0x0x0~0xFF:AlvCntValue" ;
VAL_ 2239848449 FCA_OnOffEquipSta 0 "Default" 1 "Off" 2 "Warning" 3 "Assist" 4 "Reserved" 5 "Reserved" 6 "Reserved" 7 "Invalid" ;
VAL_ 2239848449 FCA_SysFlrSta 0 "Normal" 1 "Temp. Unavailable by Front View Camera (Sensor fusion)" 2 "Temp. Unavailable by Front Radar (Radar only or Sensor fusion in Radar)" 3 "Service Required" 4 "Temp. Unavailable by Front View Camera (Camera only)" 5 "Temp. Unavailable by Front View Camera (Sensor fusion in ADAS_DRV)" 6 "Temp. Unavailable by Front Radar (Sensor fusion in Camera)" 7 "Reserved" ;
VAL_ 2239848449 FCA_WrngLvlSta 0 "No warning" 1 "Warning level 1" 2 "Warning level 2" 3 "Warning level 3" ;
VAL_ 2239848449 FCA_VehStpReq 0 "No request" 1 "Stop control is required" 2 "Reserved" 3 "Error Indicator" ;
VAL_ 2239848449 FCA_StbltActvReq 0 "Release No alert" 1 "Pre-crash full retraction" 2 "Haptic warning" 3 "Reserved" 4 "Reserved" 5 "Reserved" 6 "Reserved" 7 "Reserved" ;
VAL_ 2239848449 FCA_HydrlcBstAsstReq 0 "Standard threshold" 1 "Lowered threshold 1" 2 "Lowered threshold 2" 3 "Lowered threshold 3" ;
VAL_ 2239848449 FCA_PrefillActvReq 0 "No pre-fill" 1 "Pre-fill act" 2 "Reserved" 3 "Error Indicator" ;
VAL_ 2239848449 FCA_PartialActvReq 0 "No Partial act" 1 "Partail act" 2 "Reserved" 3 "Error Indicator" ;
VAL_ 2239848449 FCA_FullActvReq 0 "No Full act" 1 "Full act" 2 "Reserved" 3 "Error Indicator" ;
VAL_ 2239848449 FCA_Regulation 0 "No warning" 1 "FCA Amber warning on" 2 "FCA Red warning blinking" 3 "Reserved" ;
VAL_ 2239848449 FCA_SnstvtyModRetVal 0 "Default" 1 "Late" 2 "Normal" 3 "Early" 4 "Reserved" 5 "Reserved" 6 "Reserved" 7 "Invalid" ;
VAL_ 2239848449 FCA_WrngSndSta 0 "No warning" 1 "Warning 1" 2 "Warning 2" 3 "Warning 3" 4 "Reserved" 5 "Reserved" 6 "Reserved" 7 "Error indicator" ;
VAL_ 2378398721 DATC_Crc20Val 0 "0x0x0~0xFFFF:CRCValue" 65535 "0x0x0~0xFFFF:CRCValue" ;
VAL_ 2378398721 DATC_AlvCnt20Val 0 "0x0x0~0xFF:AlvCntValue" 255 "0x0x0~0xFF:AlvCntValue" ;
VAL_ 2378398721 DATC_FragStrhUSMSta 0 "Default" 1 "Off" 2 "Low" 3 "Medium" 4 "High" 5 "Reserved" 6 "Reserved" 7 "Error Indicator" ;
VAL_ 2378398721 DATC_FragKindUSMSta 0 "Default" 1 "First" 2 "Second" 3 "Reserved" 4 "Reserved" 5 "Reserved" 6 "None" 7 "Error Indicator" ;
VAL_ 2378398721 DATC_Frag1ExpireDisp 0 "Default" 1 "Normal" 2 "Expired" 3 "Error Indicator" ;
VAL_ 2378398721 DATC_FragStrhDis 0 "Default" 1 "Off" 2 "Low" 3 "Medium" 4 "High" 5 "Reserved" 6 "Reserved" 7 "Error Indicator" ;
VAL_ 2378398721 DATC_FragKindDis 0 "Default" 1 "First" 2 "Second" 3 "Reserved" 4 "Reserved" 5 "Reserved" 6 "None" 7 "Error Indicator" ;
VAL_ 2378398721 DATC_Frag2ExpireDisp 0 "Default" 1 "Normal" 2 "Expired" 3 "Error Indicator" ;
VAL_ 2378398721 DATC_VitalityFragranceSta 0 "Default" 1 "Off" 2 "On" 3 "Error Indicator" ;
VAL_ 2378398721 DATC_DelightFragranceSta 0 "Default" 1 "Off" 2 "On" 3 "Error Indicator" ;
VAL_ 2378398721 DATC_CareFragranceSta 0 "Default" 1 "Off" 2 "On" 3 "Error Indicator" ;
VAL_ 2378398721 DATC_ComfortFragranceSta 0 "Default" 1 "Off" 2 "On" 3 "Error Indicator" ;
VAL_ 2378398721 DATC_Frag1Inform 0 "Default" 1 "THE DRIVER'S AWAKENING" 2 "MY FAVORITE PLACE" 3 "THE GREAT OUTDOORS" 4 "Reserved" 5 "Reserved" 6 "Reserved" 7 "Reserved" 8 "Reserved" 9 "Reserved" 10 "Reserved" 11 "Reserved" 12 "New Fragrance Mounted" 13 "No Cartridge Mounted" 14 "Unknown Cartridge Monuted" 15 "Error Indicator" ;
VAL_ 2378398721 DATC_Frag1RemainDisp 0 "Default" 1 "Remains 100% (70~100%)" 2 "Remains 70% (30~70%)" 3 "Remains 30% (0~30%)" 4 "Remains 0%" 5 "Reserved" 6 "Unknown" 7 "Error Indicator" ;
VAL_ 2378398721 DATC_Frag2Inform 0 "Default" 1 "THE DRIVER'S AWAKENING" 2 "MY FAVORITE PLACE" 3 "THE GREAT OUTDOORS" 4 "Reserved" 5 "Reserved" 6 "Reserved" 7 "Reserved" 8 "Reserved" 9 "Reserved" 10 "Reserved" 11 "Reserved" 12 "New Fragrance Mounted" 13 "No Cartridge Mounted" 14 "Unknown Cartridge Mounted" 15 "Error Indicator" ;
VAL_ 2378398721 DATC_Frag2RemainDisp 0 "Default" 1 "Remains 100% (70~100%)" 2 "Remains 70% (30~70%)" 3 "Remains 30% (0~30%)" 4 "Remains 0%" 5 "Reserved" 6 "Unknown" 7 "Error Indicator" ;
VAL_ 2256644609 CLU_Crc1Val 0 "0x0x0~0xFFFF:CRCValue" 65535 "0x0x0~0xFFFF:CRCValue" ;
VAL_ 2256644609 CLU_AlvCnt1Val 0 "0x0x0~0xFF:AlvCntValue" 255 "0x0x0~0xFF:AlvCntValue" ;
VAL_ 2256644609 CLU_DtntOutSta 0 "Detent Off" 1 "Detent On" 2 "Not used" 3 "Error Indicator" ;
VAL_ 2256644609 CLU_SpdUnitTyp 0 "km/h" 1 "MPH" 2 "Not used" 3 "Error Indicator" ;
VAL_ 2256644609 CLU_DisSpdDcmlVal 0 "0" 1 "0.125" 2 "0.250" 3 "0.375" ;
VAL_ 2256644609 CLU_SWRCCrsMainSwSta 0 "Off" 1 "Key On" 2 "Reserved" 3 "Invalid" ;
VAL_ 2256644609 CLU_SWRCCrsSwSta 0 "Idle Position" 1 "Plus" 2 "Minus" 3 "Headway" 4 "Cancel/Pause" 5 "Reserved" 6 "Reserved" 7 "Reserved" ;
VAL_ 2256644609 CLU_SWRCLFASwSta 0 "Off" 1 "Key On" 2 "Reserved" 3 "Invalid" ;
VAL_ 2256644609 CLU_SWRCSldMainSwSta 0 "Off" 1 "Key On" 2 "Reserved" 3 "Invalid" ;
VAL_ 2256644609 CLU_RhstaLvlSta 0 "Reserved" 1 "Step 1" 2 "Step 2" 3 "Step 3" 4 "Step 4" 5 "Step 5" 6 "Step 6" 7 "Step 7" 8 "Step 8" 9 "Step 9" 10 "Step 10" 11 "Step 11" 12 "Step 12" 13 "Step 13" 14 "Step 14" 15 "Step 15" 16 "Step 16" 17 "Step 17" 18 "Step 18" 19 "Step 19" 20 "Step 20 (Reset Value)" 21 "Step 21 (Detent)" ;
VAL_ 2256644609 CLU_DisSpdVal 1023 "Error" ;
VAL_ 2256644609 CLU_OKSwSta 0 "Off" 1 "Key On" 2 "Reserved" 3 "Invalid" ;
VAL_ 2256644610 CLU_DisSpdVal_KPH 511 "Error" ;
VAL_ 2256644610 CLU_CUSTOMSta_NEW 0 "Default" 1 "MY DRIVE MODE(CUSTOM)" 2 "SMART(CUSTOM)" 3 "BABY(CUSTOM)" 4 "RETRO(CUSTOM)" 5 "SNOW(CUSTOM)-Not Terrain" 6 "COMFORT(REAR)(CUSTOM)" 7 "" 8 "" 9 "" 10 "" 11 "" 12 "" 13 "" 14 "Off(CUSTOM)" 15 "Invalid" ;
VAL_ 2256644610 CLU_AutoBrightSta 0 "Reserved (Not Used)" 1 "0x01~0xC8:Bright State (1~200 Step)" 200 "0x01~0xC8:Bright State (1~200 Step)" ;
VAL_ 2256644610 CLU_NotMinModeBrightSta 0 "RESERVED" 1 "0x01~0xC8:CLU Bright State (1~200 Step)" 200 "0x01~0xC8:CLU Bright State (1~200 Step)" 201 "RESERVED" 202 "RESERVED" 203 "RESERVED" 204 "RESERVED" 205 "RESERVED" 206 "RESERVED" 207 "RESERVED" 208 "RESERVED" 209 "RESERVED" 210 "RESERVED" 211 "RESERVED" 212 "RESERVED" 213 "RESERVED" 214 "RESERVED" 215 "RESERVED" 216 "RESERVED" 217 "RESERVED" 218 "RESERVED" 219 "RESERVED" 220 "RESERVED" 221 "RESERVED" 222 "RESERVED" 223 "RESERVED" 224 "RESERVED" 225 "RESERVED" 226 "RESERVED" 227 "RESERVED" 228 "RESERVED" 229 "RESERVED" 230 "RESERVED" 231 "RESERVED" 232 "RESERVED" 233 "RESERVED" 234 "RESERVED" 235 "RESERVED" 236 "RESERVED" 237 "RESERVED" 238 "RESERVED" 239 "RESERVED" 240 "RESERVED" 241 "RESERVED" 242 "RESERVED" 243 "RESERVED" 244 "RESERVED" 245 "RESERVED" 246 "RESERVED" 247 "RESERVED" 248 "RESERVED" 249 "RESERVED" 250 "RESERVED" 251 "RESERVED" 252 "RESERVED" 253 "RESERVED" 254 "RESERVED" 255 "RESERVED" ;
VAL_ 2256644610 CLU_PwrAutoOffResetReq_HCU 0 "Default" 1 "Reset Request" 2 "Reserved" 3 "Invalid" ;
VAL_ 350 DSAU_AirSptTimeRValueSet 0 "Default" 1 "Short" 2 "Normal" 3 "Long" 4 "Reserved" 5 "Reserved" 6 "Reserved" 7 "Reserved" ;
VAL_ 350 DSAU_DrvPostureAssistRValueSet 0 "Default" 1 "Off" 2 "On" 3 "Invalid" ;
VAL_ 350 DSAU_DrvSmtAirSptRValueSet 0 "Default" 1 "Off" 2 "On" 3 "Invalid" ;
VAL_ 350 DSAU_DrvSmtSptRValueSet 0 "Default" 1 "Off" 2 "On" 3 "Invalid" ;
VAL_ 350 DSAU_CushSoftRValueSet 0 "Default" 1 "Off" 2 "Soft" 3 "Mid" 4 "Hard" 5 "Reserved" 6 "Reserved" 7 "Reserved" ;
VAL_ 350 DSAU_BackSoftRValueSet 0 "Default" 1 "Off" 2 "Soft" 3 "Mid" 4 "Hard" 5 "Reserved" 6 "Reserved" 7 "Reserved" ;
VAL_ 350 DSAU_AirSptModeRValueSet 0 "Default" 1 "Mode 1" 2 "Mode 2" 3 "Mode 3" 4 "Mode 4" 5 "Mode 5" 6 "Reserved" 7 "Reserved" ;
VAL_ 350 DSAU_MsgModeSts 0 "Default" 1 "Off" 2 "Mode 1" 3 "Mode 2" 4 "Mode 3" 5 "Mode 4" 6 "Mode 5" 7 "Reserved" ;
VAL_ 350 DSAU_MsgModeStrength 0 "Default" 1 "Off" 2 "Low" 3 "Mid" 4 "High" 5 "Reserved" 6 "Reserved" 7 "Reserved" ;
VAL_ 350 DSAU_MoodTrpyRValueSet 0 "Default" 1 "Off" 2 "On" 3 "Invalid" ;
VAL_ 350 DSAU_MoodTrpyCareSta 0 "Default" 1 "Off" 2 "On" 3 "Invalid" ;
VAL_ 350 DSAU_MoodTrpyComfSta 0 "Default" 1 "Off" 2 "On" 3 "Invalid" ;
VAL_ 350 DASU_AirSptStrRValueSet 0 "Default" 1 "Low" 2 "Mid" 3 "High" 4 "Off" 5 "Reserved" 6 "Reserved" 7 "Reserved" ;
VAL_ 349 DSAU_CushInfDis 0 "Default" 1 "Off" 2 "On" 3 "Invalid" ;
VAL_ 349 DSAU_CushDefDis 0 "Default" 1 "Off" 2 "On" 3 "Invalid" ;
VAL_ 348 DSAU_BolsterInfDis 0 "Default" 1 "Off" 2 "On" 3 "Invalid" ;
VAL_ 348 DSAU_BolsterDefDis 0 "Default" 1 "Off" 2 "On" 3 "Invalid" ;
VAL_ 346 DPSS_WalkInSwitchSts 0 "Default" 1 "Off" 2 "On" 3 "Invalid" ;
